AUTOSAR XML (schema 00049)
package /MICROSAR/NvM_swc/DataTypes
  impl type NvM_BlockIdType: range raw 1..32767, implementation-data-type=uint16
  impl type NvM_RequestResultType: compu {0=NVM_REQ_OK, 1=NVM_REQ_NOT_OK, 2=NVM_REQ_PENDING, 3=NVM_REQ_INTEGRITY_FAILED, 4=NVM_REQ_BLOCK_SKIPPED, 5=NVM_REQ_NV_INVALIDATED, 6=NVM_REQ_CANCELED, 7=NVM_REQ_REDUNDANCY_FAILED, 8=NVM_REQ_RESTORED_FROM_ROM}, range raw 0..8, implementation-data-type=uint8
package /MICROSAR/NvM_swc/Interfaces
  4 x client server interface, all with is-service=true, service-kind=NON-VOLATILE-RAM-MANAGER:
    NvMAdministration
      operation SetBlockProtection: possible-error=NvMAdministration/E_NOT_OK
        arg ProtectionEnabled: type=boolean, direction=IN
      error E_NOT_OK: error-code=1
    NvMService_AC3_SRBS_Defs
      7 x operation, all with possible-error=NvMService_AC3_SRBS_Defs/E_NOT_OK:
        GetErrorStatus
          arg ErrorStatus: type=NvM_RequestResultType, direction=OUT
        SetRamBlockStatus
          arg RamBlockStatus: type=boolean, direction=IN
        ReadBlock
          arg DstPtr: type=dtRef_VOID, direction=IN
        WriteBlock
          arg SrcPtr: type=dtRef_const_VOID, direction=IN
        RestoreBlockDefaults
          arg DstPtr: type=dtRef_VOID, direction=IN
        InvalidateNvBlock
        EraseBlock
      error E_NOT_OK: error-code=1
    NvMService_AC3_SRBS
      6 x operation, all with possible-error=NvMService_AC3_SRBS/E_NOT_OK:
        GetErrorStatus
          arg ErrorStatus: type=NvM_RequestResultType, direction=OUT
        SetRamBlockStatus
          arg RamBlockStatus: type=boolean, direction=IN
        ReadBlock
          arg DstPtr: type=dtRef_VOID, direction=IN
        WriteBlock
          arg SrcPtr: type=dtRef_const_VOID, direction=IN
        InvalidateNvBlock
        EraseBlock
      error E_NOT_OK: error-code=1
    NvMService_AC3_SRBS_DS_Defs
      9 x operation, all with possible-error=NvMService_AC3_SRBS_DS_Defs/E_NOT_OK:
        GetErrorStatus
          arg ErrorStatus: type=NvM_RequestResultType, direction=OUT
        SetRamBlockStatus
          arg RamBlockStatus: type=boolean, direction=IN
        ReadBlock
          arg DstPtr: type=dtRef_VOID, direction=IN
        WriteBlock
          arg SrcPtr: type=dtRef_const_VOID, direction=IN
        RestoreBlockDefaults
          arg DstPtr: type=dtRef_VOID, direction=IN
        SetDataIndex
          arg DataIndex: type=uint8, direction=IN
        GetDataIndex
          arg DataIndex: type=uint8, direction=OUT
        InvalidateNvBlock
        EraseBlock
      error E_NOT_OK: error-code=1
package /MICROSAR/NvM_swc/ComponentTypes
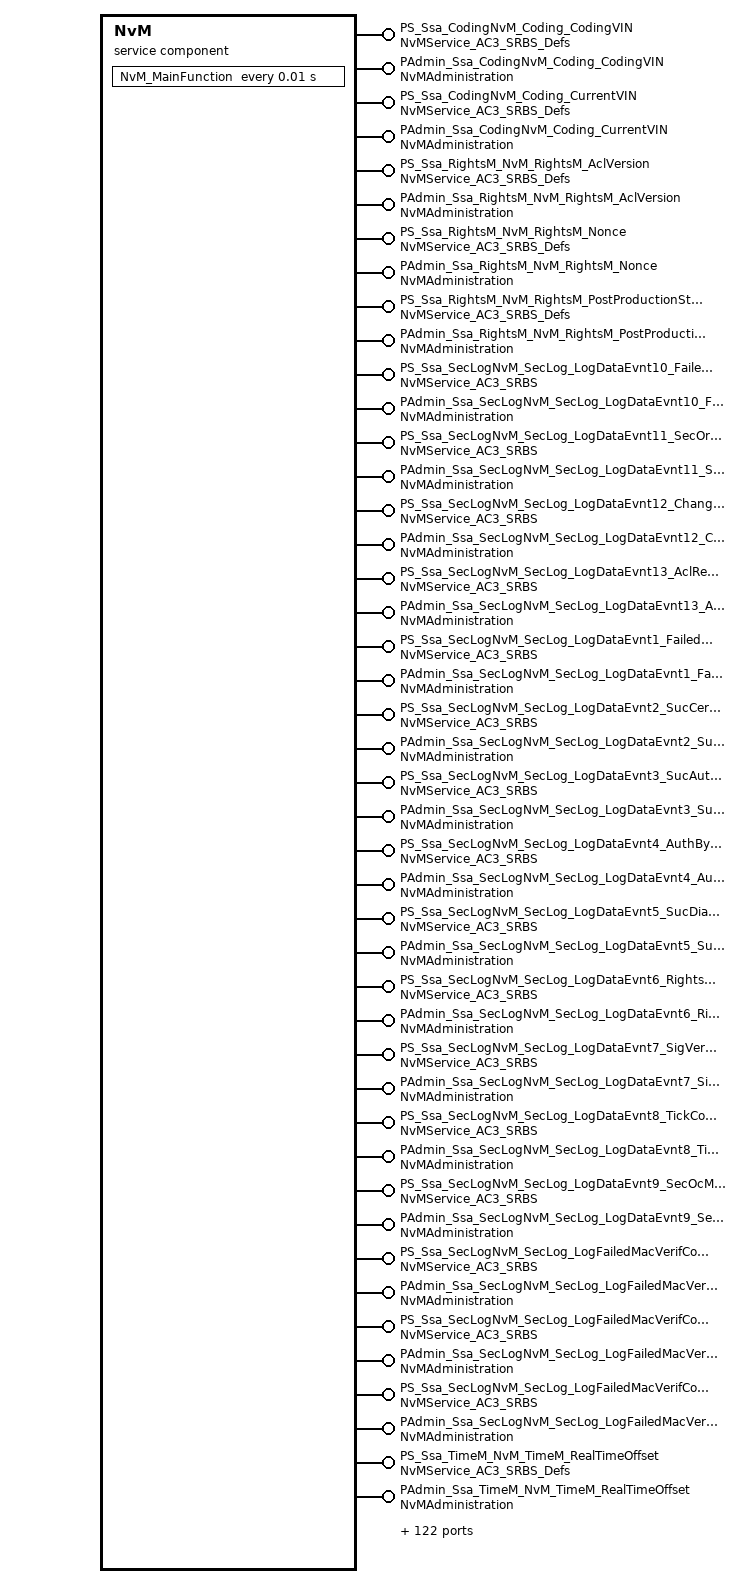
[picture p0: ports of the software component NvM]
  service sw component type NvM: category=SERVICE_COMPONENT
    166 x provide port:
      PS_Ssa_CodingNvM_Coding_CodingVIN: provided-interface=NvMService_AC3_SRBS_Defs
      PAdmin_Ssa_CodingNvM_Coding_CodingVIN: provided-interface=NvMAdministration
      PS_Ssa_CodingNvM_Coding_CurrentVIN: provided-interface=NvMService_AC3_SRBS_Defs
      PAdmin_Ssa_CodingNvM_Coding_CurrentVIN: provided-interface=NvMAdministration
      PS_Ssa_RightsM_NvM_RightsM_AclVersion: provided-interface=NvMService_AC3_SRBS_Defs
      PAdmin_Ssa_RightsM_NvM_RightsM_AclVersion: provided-interface=NvMAdministration
      PS_Ssa_RightsM_NvM_RightsM_Nonce: provided-interface=NvMService_AC3_SRBS_Defs
      PAdmin_Ssa_RightsM_NvM_RightsM_Nonce: provided-interface=NvMAdministration
      PS_Ssa_RightsM_NvM_RightsM_PostProductionStatus: provided-interface=NvMService_AC3_SRBS_Defs
      PAdmin_Ssa_RightsM_NvM_RightsM_PostProductionStatus: provided-interface=NvMAdministration
      PS_Ssa_SecLogNvM_SecLog_LogDataEvnt10_FailedPduMacVerif: provided-interface=NvMService_AC3_SRBS
      PAdmin_Ssa_SecLogNvM_SecLog_LogDataEvnt10_FailedPduMacVerif: provided-interface=NvMAdministration
      PS_Ssa_SecLogNvM_SecLog_LogDataEvnt11_SecOrAuthBoot: provided-interface=NvMService_AC3_SRBS
      PAdmin_Ssa_SecLogNvM_SecLog_LogDataEvnt11_SecOrAuthBoot: provided-interface=NvMAdministration
      PS_Ssa_SecLogNvM_SecLog_LogDataEvnt12_ChangeOfVin: provided-interface=NvMService_AC3_SRBS
      PAdmin_Ssa_SecLogNvM_SecLog_LogDataEvnt12_ChangeOfVin: provided-interface=NvMAdministration
      PS_Ssa_SecLogNvM_SecLog_LogDataEvnt13_AclReplacement: provided-interface=NvMService_AC3_SRBS
      PAdmin_Ssa_SecLogNvM_SecLog_LogDataEvnt13_AclReplacement: provided-interface=NvMAdministration
      PS_Ssa_SecLogNvM_SecLog_LogDataEvnt1_FailedCertVerif: provided-interface=NvMService_AC3_SRBS
      PAdmin_Ssa_SecLogNvM_SecLog_LogDataEvnt1_FailedCertVerif: provided-interface=NvMAdministration
      PS_Ssa_SecLogNvM_SecLog_LogDataEvnt2_SucCertVerif: provided-interface=NvMService_AC3_SRBS
      PAdmin_Ssa_SecLogNvM_SecLog_LogDataEvnt2_SucCertVerif: provided-interface=NvMAdministration
      PS_Ssa_SecLogNvM_SecLog_LogDataEvnt3_SucAuthAndEnhanceRights: provided-interface=NvMService_AC3_SRBS
      PAdmin_Ssa_SecLogNvM_SecLog_LogDataEvnt3_SucAuthAndEnhanceRights: provided-interface=NvMAdministration
      PS_Ssa_SecLogNvM_SecLog_LogDataEvnt4_AuthBySecAccess: provided-interface=NvMService_AC3_SRBS
      PAdmin_Ssa_SecLogNvM_SecLog_LogDataEvnt4_AuthBySecAccess: provided-interface=NvMAdministration
      PS_Ssa_SecLogNvM_SecLog_LogDataEvnt5_SucDiagServiceExec: provided-interface=NvMService_AC3_SRBS
      PAdmin_Ssa_SecLogNvM_SecLog_LogDataEvnt5_SucDiagServiceExec: provided-interface=NvMAdministration
      PS_Ssa_SecLogNvM_SecLog_LogDataEvnt6_RightsMgmt: provided-interface=NvMService_AC3_SRBS
      PAdmin_Ssa_SecLogNvM_SecLog_LogDataEvnt6_RightsMgmt: provided-interface=NvMAdministration
      PS_Ssa_SecLogNvM_SecLog_LogDataEvnt7_SigVerif: provided-interface=NvMService_AC3_SRBS
      PAdmin_Ssa_SecLogNvM_SecLog_LogDataEvnt7_SigVerif: provided-interface=NvMAdministration
      PS_Ssa_SecLogNvM_SecLog_LogDataEvnt8_TickCountDateAndTime: provided-interface=NvMService_AC3_SRBS
      PAdmin_Ssa_SecLogNvM_SecLog_LogDataEvnt8_TickCountDateAndTime: provided-interface=NvMAdministration
      PS_Ssa_SecLogNvM_SecLog_LogDataEvnt9_SecOcMisconfig: provided-interface=NvMService_AC3_SRBS
      PAdmin_Ssa_SecLogNvM_SecLog_LogDataEvnt9_SecOcMisconfig: provided-interface=NvMAdministration
      PS_Ssa_SecLogNvM_SecLog_LogFailedMacVerifCount_ExceededTh1: provided-interface=NvMService_AC3_SRBS
      PAdmin_Ssa_SecLogNvM_SecLog_LogFailedMacVerifCount_ExceededTh1: provided-interface=NvMAdministration
      PS_Ssa_SecLogNvM_SecLog_LogFailedMacVerifCount_ExceededTh2: provided-interface=NvMService_AC3_SRBS
      PAdmin_Ssa_SecLogNvM_SecLog_LogFailedMacVerifCount_ExceededTh2: provided-interface=NvMAdministration
      PS_Ssa_SecLogNvM_SecLog_LogFailedMacVerifCount_ExceededTh3: provided-interface=NvMService_AC3_SRBS
      PAdmin_Ssa_SecLogNvM_SecLog_LogFailedMacVerifCount_ExceededTh3: provided-interface=NvMAdministration
      PS_Ssa_TimeM_NvM_TimeM_RealTimeOffset: provided-interface=NvMService_AC3_SRBS_Defs
      PAdmin_Ssa_TimeM_NvM_TimeM_RealTimeOffset: provided-interface=NvMAdministration
      PS_Ssa_TimeM_NvM_TimeM_TickCount: provided-interface=NvMService_AC3_SRBS_Defs
      PAdmin_Ssa_TimeM_NvM_TimeM_TickCount: provided-interface=NvMAdministration
      PS_Ct_MBBL_SsaAppl_CodingNvmCoding_CurrentVehicleEquipment: provided-interface=NvMService_AC3_SRBS
      PAdmin_Ct_MBBL_SsaAppl_CodingNvmCoding_CurrentVehicleEquipment: provided-interface=NvMAdministration
      PS_Ct_MBBL_SsaAppl_CodingNvmCoding_TensioningCycleBSR: provided-interface=NvMService_AC3_SRBS
      PAdmin_Ct_MBBL_SsaAppl_CodingNvmCoding_TensioningCycleBSR: provided-interface=NvMAdministration
      PS_Ct_MBBL_SsaAppl_CodingNvmCoding_PreSafeCyclesLevel: provided-interface=NvMService_AC3_SRBS
      PAdmin_Ct_MBBL_SsaAppl_CodingNvmCoding_PreSafeCyclesLevel: provided-interface=NvMAdministration
      PS_Ct_MBBL_SsaAppl_CodingNvmCoding_ReleaseCyclesBsrAndPreSafe: provided-interface=NvMService_AC3_SRBS
      PAdmin_Ct_MBBL_SsaAppl_CodingNvmCoding_ReleaseCyclesBsrAndPreSafe: provided-interface=NvMAdministration
      PS_Ct_MBBL_SsaAppl_CodingNvmCoding_ZZZVehicleEquipmentDevelopment: provided-interface=NvMService_AC3_SRBS
      PAdmin_Ct_MBBL_SsaAppl_CodingNvmCoding_ZZZVehicleEquipmentDevelopment: provided-interface=NvMAdministration
      PS_Ct_MBBL_SsaAppl_CodingNvmCoding_CalibrationID: provided-interface=NvMService_AC3_SRBS
      PAdmin_Ct_MBBL_SsaAppl_CodingNvmCoding_CalibrationID: provided-interface=NvMAdministration
      PS_NvMBlockDescriptor_FblMetaData: provided-interface=NvMService_AC3_SRBS_DS_Defs
      PAdmin_NvMBlockDescriptor_FblMetaData: provided-interface=NvMAdministration
      PS_NVP_BLOCK_ID_ECU_LOCATION: provided-interface=NvMService_AC3_SRBS_Defs
      PAdmin_NVP_BLOCK_ID_ECU_LOCATION: provided-interface=NvMAdministration
      PS_NVP_BLOCK_ID_BELT_ASSEMBLY_MANUF_DATE_AND_SN: provided-interface=NvMService_AC3_SRBS_Defs
      PAdmin_NVP_BLOCK_ID_BELT_ASSEMBLY_MANUF_DATE_AND_SN: provided-interface=NvMAdministration
      PS_NVP_BLOCK_ID_HB_CALIBRATION: provided-interface=NvMService_AC3_SRBS_Defs
      PAdmin_NVP_BLOCK_ID_HB_CALIBRATION: provided-interface=NvMAdministration
      PS_NVP_BLOCK_ID_AEE_TRACEABILITY: provided-interface=NvMService_AC3_SRBS_Defs
      PAdmin_NVP_BLOCK_ID_AEE_TRACEABILITY: provided-interface=NvMAdministration
      PS_NVP_BLOCK_ID_EXECUTION_COUNTERS: provided-interface=NvMService_AC3_SRBS_Defs
      PAdmin_NVP_BLOCK_ID_EXECUTION_COUNTERS: provided-interface=NvMAdministration
      PS_NVP_BLOCK_ID_TESTS_PARAM: provided-interface=NvMService_AC3_SRBS_Defs
      PAdmin_NVP_BLOCK_ID_TESTS_PARAM: provided-interface=NvMAdministration
      PS_NVP_BLOCK_ID_CYCLE: provided-interface=NvMService_AC3_SRBS_Defs
      PAdmin_NVP_BLOCK_ID_CYCLE: provided-interface=NvMAdministration
      PS_NVP_BLOCK_ID_STEP: provided-interface=NvMService_AC3_SRBS_Defs
      PAdmin_NVP_BLOCK_ID_STEP: provided-interface=NvMAdministration
      PS_CALIB_BLOCK_ID_EOL_PARAM: provided-interface=NvMService_AC3_SRBS_Defs
      PAdmin_CALIB_BLOCK_ID_EOL_PARAM: provided-interface=NvMAdministration
      PS_CALIB_BLOCK_ID_BFS_PRIO_PARAM: provided-interface=NvMService_AC3_SRBS_Defs
      PAdmin_CALIB_BLOCK_ID_BFS_PRIO_PARAM: provided-interface=NvMAdministration
      PS_CALIB_BLOCK_ID_PID_PARAM: provided-interface=NvMService_AC3_SRBS_Defs
      PAdmin_CALIB_BLOCK_ID_PID_PARAM: provided-interface=NvMAdministration
      PS_CALIB_BLOCK_ID_WEIGHT_REL_TABLE: provided-interface=NvMService_AC3_SRBS_Defs
      PAdmin_CALIB_BLOCK_ID_WEIGHT_REL_TABLE: provided-interface=NvMAdministration
      PS_CALIB_BLOCK_ID_WEIGHT_TENS0_TABLE: provided-interface=NvMService_AC3_SRBS_Defs
      PAdmin_CALIB_BLOCK_ID_WEIGHT_TENS0_TABLE: provided-interface=NvMAdministration
      PS_CALIB_BLOCK_ID_WEIGHT_TENS1_TABLE: provided-interface=NvMService_AC3_SRBS_Defs
      PAdmin_CALIB_BLOCK_ID_WEIGHT_TENS1_TABLE: provided-interface=NvMAdministration
      PS_CALIB_BLOCK_ID_WEIGHT_TENS2_TABLE: provided-interface=NvMService_AC3_SRBS_Defs
      PAdmin_CALIB_BLOCK_ID_WEIGHT_TENS2_TABLE: provided-interface=NvMAdministration
      PS_CALIB_BLOCK_ID_WEIGHT_TENS3_TABLE: provided-interface=NvMService_AC3_SRBS_Defs
      PAdmin_CALIB_BLOCK_ID_WEIGHT_TENS3_TABLE: provided-interface=NvMAdministration
      PS_CALIB_BLOCK_ID_INT_CURRENT_CORR: provided-interface=NvMService_AC3_SRBS_Defs
      PAdmin_CALIB_BLOCK_ID_INT_CURRENT_CORR: provided-interface=NvMAdministration
      PS_CALIB_BLOCK_ID_INT_CURRENT_TABLE: provided-interface=NvMService_AC3_SRBS_Defs
      PAdmin_CALIB_BLOCK_ID_INT_CURRENT_TABLE: provided-interface=NvMAdministration
      PS_CALIB_BLOCK_ID_ECPL_ALPHA_TABLE: provided-interface=NvMService_AC3_SRBS_Defs
      PAdmin_CALIB_BLOCK_ID_ECPL_ALPHA_TABLE: provided-interface=NvMAdministration
      PS_CALIB_BLOCK_ID_POWER_DEGRADATION: provided-interface=NvMService_AC3_SRBS_Defs
      PAdmin_CALIB_BLOCK_ID_POWER_DEGRADATION: provided-interface=NvMAdministration
      PS_CALIB_BLOCK_ID_ECPL_BETA_TABLE: provided-interface=NvMService_AC3_SRBS_Defs
      PAdmin_CALIB_BLOCK_ID_ECPL_BETA_TABLE: provided-interface=NvMAdministration
      PS_CALIB_BLOCK_ID_ECPL_OTHER_PARAM: provided-interface=NvMService_AC3_SRBS_Defs
      PAdmin_CALIB_BLOCK_ID_ECPL_OTHER_PARAM: provided-interface=NvMAdministration
      PS_CALIB_BLOCK_ID_BPA_MOTOR_CURRENT: provided-interface=NvMService_AC3_SRBS_Defs
      PAdmin_CALIB_BLOCK_ID_BPA_MOTOR_CURRENT: provided-interface=NvMAdministration
      PS_CALIB_BLOCK_ID_VOLT_THRS: provided-interface=NvMService_AC3_SRBS_Defs
      PAdmin_CALIB_BLOCK_ID_VOLT_THRS: provided-interface=NvMAdministration
      PS_CALIB_BLOCK_ID_BATTERY_LOSS_DETECTION_THRS: provided-interface=NvMService_AC3_SRBS_Defs
      PAdmin_CALIB_BLOCK_ID_BATTERY_LOSS_DETECTION_THRS: provided-interface=NvMAdministration
      PS_CALIB_BLOCK_ID_BOOST: provided-interface=NvMService_AC3_SRBS_Defs
      PAdmin_CALIB_BLOCK_ID_BOOST: provided-interface=NvMAdministration
      PS_CALIB_BLOCK_ID_ECU_PROPERTIES: provided-interface=NvMService_AC3_SRBS_Defs
      PAdmin_CALIB_BLOCK_ID_ECU_PROPERTIES: provided-interface=NvMAdministration
      PS_CALIB_BLOCK_ID_SW_SELF_PROTECTION_THRS: provided-interface=NvMService_AC3_SRBS_Defs
      PAdmin_CALIB_BLOCK_ID_SW_SELF_PROTECTION_THRS: provided-interface=NvMAdministration
      PS_CALIB_BLOCK_ID_MOTOR_RESIST_PARAM: provided-interface=NvMService_AC3_SRBS_Defs
      PAdmin_CALIB_BLOCK_ID_MOTOR_RESIST_PARAM: provided-interface=NvMAdministration
      PS_CALIB_BLOCK_ID_BOOST_ACTIVATION: provided-interface=NvMService_AC3_SRBS_Defs
      PAdmin_CALIB_BLOCK_ID_BOOST_ACTIVATION: provided-interface=NvMAdministration
      PS_NVP_BLOCK_ID_MEASUREMENT_FRAME_12_CONFIG: provided-interface=NvMService_AC3_SRBS_Defs
      PAdmin_NVP_BLOCK_ID_MEASUREMENT_FRAME_12_CONFIG: provided-interface=NvMAdministration
      PS_NVP_BLOCK_ID_MEASUREMENT_FRAME_CONFIG: provided-interface=NvMService_AC3_SRBS_Defs
      PAdmin_NVP_BLOCK_ID_MEASUREMENT_FRAME_CONFIG: provided-interface=NvMAdministration
      PS_NVP_BLOCK_ID_WARM_RESET: provided-interface=NvMService_AC3_SRBS_Defs
      PAdmin_NVP_BLOCK_ID_WARM_RESET: provided-interface=NvMAdministration
      PS_NVP_BLOCK_ID_HWA_REPETITION: provided-interface=NvMService_AC3_SRBS_Defs
      PAdmin_NVP_BLOCK_ID_HWA_REPETITION: provided-interface=NvMAdministration
      PS_NVP_BLOCK_TEMP_SENSOR_TABLE: provided-interface=NvMService_AC3_SRBS_Defs
      PAdmin_NVP_BLOCK_TEMP_SENSOR_TABLE: provided-interface=NvMAdministration
      PS_NVP_BLOCK_ID_VELOCITY_PID_PARAM: provided-interface=NvMService_AC3_SRBS_Defs
      PAdmin_NVP_BLOCK_ID_VELOCITY_PID_PARAM: provided-interface=NvMAdministration
      PS_NVP_BLOCK_ID_AEC_STATUS: provided-interface=NvMService_AC3_SRBS_Defs
      PAdmin_NVP_BLOCK_ID_AEC_STATUS: provided-interface=NvMAdministration
      PS_NVP_BLOCK_ID_ATM_ENABLE_PARAM: provided-interface=NvMService_AC3_SRBS_Defs
      PAdmin_NVP_BLOCK_ID_ATM_ENABLE_PARAM: provided-interface=NvMAdministration
      PS_Ssa_KeyM_NvM_KeyM_TrustModelChainOfTrustState: provided-interface=NvMService_AC3_SRBS_Defs
      PAdmin_Ssa_KeyM_NvM_KeyM_TrustModelChainOfTrustState: provided-interface=NvMAdministration
      PS_NVP_BLOCK_ID_PRE_SAFE_RECORDER_1: provided-interface=NvMService_AC3_SRBS_Defs
      PAdmin_NVP_BLOCK_ID_PRE_SAFE_RECORDER_1: provided-interface=NvMAdministration
      PS_NVP_BLOCK_ID_PRE_SAFE_RECORDER_2: provided-interface=NvMService_AC3_SRBS_Defs
      PAdmin_NVP_BLOCK_ID_PRE_SAFE_RECORDER_2: provided-interface=NvMAdministration
      PS_NVP_BLOCK_ID_PRE_SAFE_RECORDER_ID: provided-interface=NvMService_AC3_SRBS_Defs
      PAdmin_NVP_BLOCK_ID_PRE_SAFE_RECORDER_ID: provided-interface=NvMAdministration
      PS_NVP_BLOCK_ID_SYSTEM_CONTEXT_0: provided-interface=NvMService_AC3_SRBS
      PAdmin_NVP_BLOCK_ID_SYSTEM_CONTEXT_0: provided-interface=NvMAdministration
      PS_NVP_BLOCK_ID_SYSTEM_CONTEXT_1: provided-interface=NvMService_AC3_SRBS
      PAdmin_NVP_BLOCK_ID_SYSTEM_CONTEXT_1: provided-interface=NvMAdministration
      PS_NVP_BLOCK_ID_SYSTEM_CONTEXT_2: provided-interface=NvMService_AC3_SRBS
      PAdmin_NVP_BLOCK_ID_SYSTEM_CONTEXT_2: provided-interface=NvMAdministration
      PS_NVP_BLOCK_ID_CYCLE_DELAYS_MB: provided-interface=NvMService_AC3_SRBS_Defs
      PAdmin_NVP_BLOCK_ID_CYCLE_DELAYS_MB: provided-interface=NvMAdministration
      PS_NVP_BLOCK_ID_HAPTIC_CONFIG_MB: provided-interface=NvMService_AC3_SRBS_Defs
      PAdmin_NVP_BLOCK_ID_HAPTIC_CONFIG_MB: provided-interface=NvMAdministration
      PS_NVP_BLOCK_ID_EOL_MAPPING_MB: provided-interface=NvMService_AC3_SRBS_Defs
      PAdmin_NVP_BLOCK_ID_EOL_MAPPING_MB: provided-interface=NvMAdministration
      PS_NVP_BLOCK_ID_HW_VERSION: provided-interface=NvMService_AC3_SRBS_Defs
      PAdmin_NVP_BLOCK_ID_HW_VERSION: provided-interface=NvMAdministration
      PS_NVP_BLOCK_ID_CAN_INPUT_SIGNALS: provided-interface=NvMService_AC3_SRBS_Defs
      PAdmin_NVP_BLOCK_ID_CAN_INPUT_SIGNALS: provided-interface=NvMAdministration
      PS_NVP_BLOCK_ID_PCBA_PPN: provided-interface=NvMService_AC3_SRBS_Defs
      PAdmin_NVP_BLOCK_ID_PCBA_PPN: provided-interface=NvMAdministration
      PS_NVP_BLOCK_ID_CSR_SUPPLIER_SIGNATURE: provided-interface=NvMService_AC3_SRBS_Defs
      PAdmin_NVP_BLOCK_ID_CSR_SUPPLIER_SIGNATURE: provided-interface=NvMAdministration
      PS_NVP_BLOCK_ID_HW_PARTNUMBER: provided-interface=NvMService_AC3_SRBS_Defs
      PAdmin_NVP_BLOCK_ID_HW_PARTNUMBER: provided-interface=NvMAdministration
    behavior NvMInternalBehavior: handle-termination-and-restart=NO-SUPPORT
      timing event Timer_NvM_MainFunction: start-on-event=NvM_MainFunction, period=0.01
      641 x operation invoked event:
        OpEventGetErrorStatus_GetErrorStatus_PS_Ssa_CodingNvM_Coding_CodingVIN: start-on-event=GetErrorStatus, operation=PS_Ssa_CodingNvM_Coding_CodingVIN.GetErrorStatus
        OpEventGetErrorStatus_GetErrorStatus_PS_Ssa_CodingNvM_Coding_CurrentVIN: start-on-event=GetErrorStatus, operation=PS_Ssa_CodingNvM_Coding_CurrentVIN.GetErrorStatus
        OpEventGetErrorStatus_GetErrorStatus_PS_Ssa_RightsM_NvM_RightsM_AclVersion: start-on-event=GetErrorStatus, operation=PS_Ssa_RightsM_NvM_RightsM_AclVersion.GetErrorStatus
        OpEventGetErrorStatus_GetErrorStatus_PS_Ssa_RightsM_NvM_RightsM_Nonce: start-on-event=GetErrorStatus, operation=PS_Ssa_RightsM_NvM_RightsM_Nonce.GetErrorStatus
        OpEventGetErrorStatus_GetErrorStatus_PS_Ssa_RightsM_NvM_RightsM_PostProductionStatus: start-on-event=GetErrorStatus, operation=PS_Ssa_RightsM_NvM_RightsM_PostProductionStatus.GetErrorStatus
        OpEventGetErrorStatus_GetErrorStatus_PS_Ssa_SecLogNvM_SecLog_LogDataEvnt10_FailedPduMacVerif: start-on-event=GetErrorStatus, operation=PS_Ssa_SecLogNvM_SecLog_LogDataEvnt10_FailedPduMacVerif.GetErrorStatus
        OpEventGetErrorStatus_GetErrorStatus_PS_Ssa_SecLogNvM_SecLog_LogDataEvnt11_SecOrAuthBoot: start-on-event=GetErrorStatus, operation=PS_Ssa_SecLogNvM_SecLog_LogDataEvnt11_SecOrAuthBoot.GetErrorStatus
        OpEventGetErrorStatus_GetErrorStatus_PS_Ssa_SecLogNvM_SecLog_LogDataEvnt12_ChangeOfVin: start-on-event=GetErrorStatus, operation=PS_Ssa_SecLogNvM_SecLog_LogDataEvnt12_ChangeOfVin.GetErrorStatus
        OpEventGetErrorStatus_GetErrorStatus_PS_Ssa_SecLogNvM_SecLog_LogDataEvnt13_AclReplacement: start-on-event=GetErrorStatus, operation=PS_Ssa_SecLogNvM_SecLog_LogDataEvnt13_AclReplacement.GetErrorStatus
        OpEventGetErrorStatus_GetErrorStatus_PS_Ssa_SecLogNvM_SecLog_LogDataEvnt1_FailedCertVerif: start-on-event=GetErrorStatus, operation=PS_Ssa_SecLogNvM_SecLog_LogDataEvnt1_FailedCertVerif.GetErrorStatus
        OpEventGetErrorStatus_GetErrorStatus_PS_Ssa_SecLogNvM_SecLog_LogDataEvnt2_SucCertVerif: start-on-event=GetErrorStatus, operation=PS_Ssa_SecLogNvM_SecLog_LogDataEvnt2_SucCertVerif.GetErrorStatus
        OpEventGetErrorStatus_GetErrorStatus_PS_Ssa_SecLogNvM_SecLog_LogDataEvnt3_SucAuthAndEnhanceRights: start-on-event=GetErrorStatus, operation=PS_Ssa_SecLogNvM_SecLog_LogDataEvnt3_SucAuthAndEnhanceRights.GetErrorStatus
        OpEventGetErrorStatus_GetErrorStatus_PS_Ssa_SecLogNvM_SecLog_LogDataEvnt4_AuthBySecAccess: start-on-event=GetErrorStatus, operation=PS_Ssa_SecLogNvM_SecLog_LogDataEvnt4_AuthBySecAccess.GetErrorStatus
        OpEventGetErrorStatus_GetErrorStatus_PS_Ssa_SecLogNvM_SecLog_LogDataEvnt5_SucDiagServiceExec: start-on-event=GetErrorStatus, operation=PS_Ssa_SecLogNvM_SecLog_LogDataEvnt5_SucDiagServiceExec.GetErrorStatus
        OpEventGetErrorStatus_GetErrorStatus_PS_Ssa_SecLogNvM_SecLog_LogDataEvnt6_RightsMgmt: start-on-event=GetErrorStatus, operation=PS_Ssa_SecLogNvM_SecLog_LogDataEvnt6_RightsMgmt.GetErrorStatus
        OpEventGetErrorStatus_GetErrorStatus_PS_Ssa_SecLogNvM_SecLog_LogDataEvnt7_SigVerif: start-on-event=GetErrorStatus, operation=PS_Ssa_SecLogNvM_SecLog_LogDataEvnt7_SigVerif.GetErrorStatus
        OpEventGetErrorStatus_GetErrorStatus_PS_Ssa_SecLogNvM_SecLog_LogDataEvnt8_TickCountDateAndTime: start-on-event=GetErrorStatus, operation=PS_Ssa_SecLogNvM_SecLog_LogDataEvnt8_TickCountDateAndTime.GetErrorStatus
        OpEventGetErrorStatus_GetErrorStatus_PS_Ssa_SecLogNvM_SecLog_LogDataEvnt9_SecOcMisconfig: start-on-event=GetErrorStatus, operation=PS_Ssa_SecLogNvM_SecLog_LogDataEvnt9_SecOcMisconfig.GetErrorStatus
        OpEventGetErrorStatus_GetErrorStatus_PS_Ssa_SecLogNvM_SecLog_LogFailedMacVerifCount_ExceededTh{1..3}: start-on-event=GetErrorStatus, operation=PS_Ssa_SecLogNvM_SecLog_LogFailedMacVerifCount_ExceededTh{1..3}.GetErrorStatus
        OpEventGetErrorStatus_GetErrorStatus_PS_Ssa_TimeM_NvM_TimeM_RealTimeOffset: start-on-event=GetErrorStatus, operation=PS_Ssa_TimeM_NvM_TimeM_RealTimeOffset.GetErrorStatus
        OpEventGetErrorStatus_GetErrorStatus_PS_Ssa_TimeM_NvM_TimeM_TickCount: start-on-event=GetErrorStatus, operation=PS_Ssa_TimeM_NvM_TimeM_TickCount.GetErrorStatus
        OpEventGetErrorStatus_GetErrorStatus_PS_Ct_MBBL_SsaAppl_CodingNvmCoding_CurrentVehicleEquipment: start-on-event=GetErrorStatus, operation=PS_Ct_MBBL_SsaAppl_CodingNvmCoding_CurrentVehicleEquipment.GetErrorStatus
        OpEventGetErrorStatus_GetErrorStatus_PS_Ct_MBBL_SsaAppl_CodingNvmCoding_TensioningCycleBSR: start-on-event=GetErrorStatus, operation=PS_Ct_MBBL_SsaAppl_CodingNvmCoding_TensioningCycleBSR.GetErrorStatus
        OpEventGetErrorStatus_GetErrorStatus_PS_Ct_MBBL_SsaAppl_CodingNvmCoding_PreSafeCyclesLevel: start-on-event=GetErrorStatus, operation=PS_Ct_MBBL_SsaAppl_CodingNvmCoding_PreSafeCyclesLevel.GetErrorStatus
        OpEventGetErrorStatus_GetErrorStatus_PS_Ct_MBBL_SsaAppl_CodingNvmCoding_ReleaseCyclesBsrAndPreSafe: start-on-event=GetErrorStatus, operation=PS_Ct_MBBL_SsaAppl_CodingNvmCoding_ReleaseCyclesBsrAndPreSafe.GetErrorStatus
        OpEventGetErrorStatus_GetErrorStatus_PS_Ct_MBBL_SsaAppl_CodingNvmCoding_ZZZVehicleEquipmentDevelopment: start-on-event=GetErrorStatus, operation=PS_Ct_MBBL_SsaAppl_CodingNvmCoding_ZZZVehicleEquipmentDevelopment.GetErrorStatus
        OpEventGetErrorStatus_GetErrorStatus_PS_Ct_MBBL_SsaAppl_CodingNvmCoding_CalibrationID: start-on-event=GetErrorStatus, operation=PS_Ct_MBBL_SsaAppl_CodingNvmCoding_CalibrationID.GetErrorStatus
        OpEventGetErrorStatus_GetErrorStatus_PS_NvMBlockDescriptor_FblMetaData: start-on-event=GetErrorStatus, operation=PS_NvMBlockDescriptor_FblMetaData.GetErrorStatus
        OpEventGetErrorStatus_GetErrorStatus_PS_NVP_BLOCK_ID_ECU_LOCATION: start-on-event=GetErrorStatus, operation=PS_NVP_BLOCK_ID_ECU_LOCATION.GetErrorStatus
        OpEventGetErrorStatus_GetErrorStatus_PS_NVP_BLOCK_ID_BELT_ASSEMBLY_MANUF_DATE_AND_SN: start-on-event=GetErrorStatus, operation=PS_NVP_BLOCK_ID_BELT_ASSEMBLY_MANUF_DATE_AND_SN.GetErrorStatus
        OpEventGetErrorStatus_GetErrorStatus_PS_NVP_BLOCK_ID_HB_CALIBRATION: start-on-event=GetErrorStatus, operation=PS_NVP_BLOCK_ID_HB_CALIBRATION.GetErrorStatus
        OpEventGetErrorStatus_GetErrorStatus_PS_NVP_BLOCK_ID_AEE_TRACEABILITY: start-on-event=GetErrorStatus, operation=PS_NVP_BLOCK_ID_AEE_TRACEABILITY.GetErrorStatus
        OpEventGetErrorStatus_GetErrorStatus_PS_NVP_BLOCK_ID_EXECUTION_COUNTERS: start-on-event=GetErrorStatus, operation=PS_NVP_BLOCK_ID_EXECUTION_COUNTERS.GetErrorStatus
        OpEventGetErrorStatus_GetErrorStatus_PS_NVP_BLOCK_ID_TESTS_PARAM: start-on-event=GetErrorStatus, operation=PS_NVP_BLOCK_ID_TESTS_PARAM.GetErrorStatus
        OpEventGetErrorStatus_GetErrorStatus_PS_NVP_BLOCK_ID_CYCLE: start-on-event=GetErrorStatus, operation=PS_NVP_BLOCK_ID_CYCLE.GetErrorStatus
        OpEventGetErrorStatus_GetErrorStatus_PS_NVP_BLOCK_ID_STEP: start-on-event=GetErrorStatus, operation=PS_NVP_BLOCK_ID_STEP.GetErrorStatus
        OpEventGetErrorStatus_GetErrorStatus_PS_CALIB_BLOCK_ID_EOL_PARAM: start-on-event=GetErrorStatus, operation=PS_CALIB_BLOCK_ID_EOL_PARAM.GetErrorStatus
        OpEventGetErrorStatus_GetErrorStatus_PS_CALIB_BLOCK_ID_BFS_PRIO_PARAM: start-on-event=GetErrorStatus, operation=PS_CALIB_BLOCK_ID_BFS_PRIO_PARAM.GetErrorStatus
        OpEventGetErrorStatus_GetErrorStatus_PS_CALIB_BLOCK_ID_PID_PARAM: start-on-event=GetErrorStatus, operation=PS_CALIB_BLOCK_ID_PID_PARAM.GetErrorStatus
        OpEventGetErrorStatus_GetErrorStatus_PS_CALIB_BLOCK_ID_WEIGHT_REL_TABLE: start-on-event=GetErrorStatus, operation=PS_CALIB_BLOCK_ID_WEIGHT_REL_TABLE.GetErrorStatus
        OpEventGetErrorStatus_GetErrorStatus_PS_CALIB_BLOCK_ID_WEIGHT_TENS{0..3}_TABLE: start-on-event=GetErrorStatus, operation=PS_CALIB_BLOCK_ID_WEIGHT_TENS{0..3}_TABLE.GetErrorStatus
        OpEventGetErrorStatus_GetErrorStatus_PS_CALIB_BLOCK_ID_INT_CURRENT_CORR: start-on-event=GetErrorStatus, operation=PS_CALIB_BLOCK_ID_INT_CURRENT_CORR.GetErrorStatus
        OpEventGetErrorStatus_GetErrorStatus_PS_CALIB_BLOCK_ID_INT_CURRENT_TABLE: start-on-event=GetErrorStatus, operation=PS_CALIB_BLOCK_ID_INT_CURRENT_TABLE.GetErrorStatus
        OpEventGetErrorStatus_GetErrorStatus_PS_CALIB_BLOCK_ID_ECPL_ALPHA_TABLE: start-on-event=GetErrorStatus, operation=PS_CALIB_BLOCK_ID_ECPL_ALPHA_TABLE.GetErrorStatus
        OpEventGetErrorStatus_GetErrorStatus_PS_CALIB_BLOCK_ID_POWER_DEGRADATION: start-on-event=GetErrorStatus, operation=PS_CALIB_BLOCK_ID_POWER_DEGRADATION.GetErrorStatus
        OpEventGetErrorStatus_GetErrorStatus_PS_CALIB_BLOCK_ID_ECPL_BETA_TABLE: start-on-event=GetErrorStatus, operation=PS_CALIB_BLOCK_ID_ECPL_BETA_TABLE.GetErrorStatus
        OpEventGetErrorStatus_GetErrorStatus_PS_CALIB_BLOCK_ID_ECPL_OTHER_PARAM: start-on-event=GetErrorStatus, operation=PS_CALIB_BLOCK_ID_ECPL_OTHER_PARAM.GetErrorStatus
        OpEventGetErrorStatus_GetErrorStatus_PS_CALIB_BLOCK_ID_BPA_MOTOR_CURRENT: start-on-event=GetErrorStatus, operation=PS_CALIB_BLOCK_ID_BPA_MOTOR_CURRENT.GetErrorStatus
        OpEventGetErrorStatus_GetErrorStatus_PS_CALIB_BLOCK_ID_VOLT_THRS: start-on-event=GetErrorStatus, operation=PS_CALIB_BLOCK_ID_VOLT_THRS.GetErrorStatus
        OpEventGetErrorStatus_GetErrorStatus_PS_CALIB_BLOCK_ID_BATTERY_LOSS_DETECTION_THRS: start-on-event=GetErrorStatus, operation=PS_CALIB_BLOCK_ID_BATTERY_LOSS_DETECTION_THRS.GetErrorStatus
        OpEventGetErrorStatus_GetErrorStatus_PS_CALIB_BLOCK_ID_BOOST: start-on-event=GetErrorStatus, operation=PS_CALIB_BLOCK_ID_BOOST.GetErrorStatus
        OpEventGetErrorStatus_GetErrorStatus_PS_CALIB_BLOCK_ID_ECU_PROPERTIES: start-on-event=GetErrorStatus, operation=PS_CALIB_BLOCK_ID_ECU_PROPERTIES.GetErrorStatus
        OpEventGetErrorStatus_GetErrorStatus_PS_CALIB_BLOCK_ID_SW_SELF_PROTECTION_THRS: start-on-event=GetErrorStatus, operation=PS_CALIB_BLOCK_ID_SW_SELF_PROTECTION_THRS.GetErrorStatus
        OpEventGetErrorStatus_GetErrorStatus_PS_CALIB_BLOCK_ID_MOTOR_RESIST_PARAM: start-on-event=GetErrorStatus, operation=PS_CALIB_BLOCK_ID_MOTOR_RESIST_PARAM.GetErrorStatus
        OpEventGetErrorStatus_GetErrorStatus_PS_CALIB_BLOCK_ID_BOOST_ACTIVATION: start-on-event=GetErrorStatus, operation=PS_CALIB_BLOCK_ID_BOOST_ACTIVATION.GetErrorStatus
        OpEventGetErrorStatus_GetErrorStatus_PS_NVP_BLOCK_ID_MEASUREMENT_FRAME_12_CONFIG: start-on-event=GetErrorStatus, operation=PS_NVP_BLOCK_ID_MEASUREMENT_FRAME_12_CONFIG.GetErrorStatus
        OpEventGetErrorStatus_GetErrorStatus_PS_NVP_BLOCK_ID_MEASUREMENT_FRAME_CONFIG: start-on-event=GetErrorStatus, operation=PS_NVP_BLOCK_ID_MEASUREMENT_FRAME_CONFIG.GetErrorStatus
        OpEventSetRamBlockStatus_SetRamBlockStatus_PS_Ssa_CodingNvM_Coding_CodingVIN: start-on-event=SetRamBlockStatus, operation=PS_Ssa_CodingNvM_Coding_CodingVIN.SetRamBlockStatus
        OpEventSetRamBlockStatus_SetRamBlockStatus_PS_Ssa_CodingNvM_Coding_CurrentVIN: start-on-event=SetRamBlockStatus, operation=PS_Ssa_CodingNvM_Coding_CurrentVIN.SetRamBlockStatus
        OpEventSetRamBlockStatus_SetRamBlockStatus_PS_Ssa_RightsM_NvM_RightsM_AclVersion: start-on-event=SetRamBlockStatus, operation=PS_Ssa_RightsM_NvM_RightsM_AclVersion.SetRamBlockStatus
        OpEventSetRamBlockStatus_SetRamBlockStatus_PS_Ssa_RightsM_NvM_RightsM_Nonce: start-on-event=SetRamBlockStatus, operation=PS_Ssa_RightsM_NvM_RightsM_Nonce.SetRamBlockStatus
        OpEventSetRamBlockStatus_SetRamBlockStatus_PS_Ssa_RightsM_NvM_RightsM_PostProductionStatus: start-on-event=SetRamBlockStatus, operation=PS_Ssa_RightsM_NvM_RightsM_PostProductionStatus.SetRamBlockStatus
        OpEventSetRamBlockStatus_SetRamBlockStatus_PS_Ssa_SecLogNvM_SecLog_LogDataEvnt10_FailedPduMacVerif: start-on-event=SetRamBlockStatus, operation=PS_Ssa_SecLogNvM_SecLog_LogDataEvnt10_FailedPduMacVerif.SetRamBlockStatus
        OpEventSetRamBlockStatus_SetRamBlockStatus_PS_Ssa_SecLogNvM_SecLog_LogDataEvnt11_SecOrAuthBoot: start-on-event=SetRamBlockStatus, operation=PS_Ssa_SecLogNvM_SecLog_LogDataEvnt11_SecOrAuthBoot.SetRamBlockStatus
        OpEventSetRamBlockStatus_SetRamBlockStatus_PS_Ssa_SecLogNvM_SecLog_LogDataEvnt12_ChangeOfVin: start-on-event=SetRamBlockStatus, operation=PS_Ssa_SecLogNvM_SecLog_LogDataEvnt12_ChangeOfVin.SetRamBlockStatus
        OpEventSetRamBlockStatus_SetRamBlockStatus_PS_Ssa_SecLogNvM_SecLog_LogDataEvnt13_AclReplacement: start-on-event=SetRamBlockStatus, operation=PS_Ssa_SecLogNvM_SecLog_LogDataEvnt13_AclReplacement.SetRamBlockStatus
        OpEventSetRamBlockStatus_SetRamBlockStatus_PS_Ssa_SecLogNvM_SecLog_LogDataEvnt1_FailedCertVerif: start-on-event=SetRamBlockStatus, operation=PS_Ssa_SecLogNvM_SecLog_LogDataEvnt1_FailedCertVerif.SetRamBlockStatus
        OpEventSetRamBlockStatus_SetRamBlockStatus_PS_Ssa_SecLogNvM_SecLog_LogDataEvnt2_SucCertVerif: start-on-event=SetRamBlockStatus, operation=PS_Ssa_SecLogNvM_SecLog_LogDataEvnt2_SucCertVerif.SetRamBlockStatus
        OpEventSetRamBlockStatus_SetRamBlockStatus_PS_Ssa_SecLogNvM_SecLog_LogDataEvnt3_SucAuthAndEnhanceRights: start-on-event=SetRamBlockStatus, operation=PS_Ssa_SecLogNvM_SecLog_LogDataEvnt3_SucAuthAndEnhanceRights.SetRamBlockStatus
        OpEventSetRamBlockStatus_SetRamBlockStatus_PS_Ssa_SecLogNvM_SecLog_LogDataEvnt4_AuthBySecAccess: start-on-event=SetRamBlockStatus, operation=PS_Ssa_SecLogNvM_SecLog_LogDataEvnt4_AuthBySecAccess.SetRamBlockStatus
        OpEventSetRamBlockStatus_SetRamBlockStatus_PS_Ssa_SecLogNvM_SecLog_LogDataEvnt5_SucDiagServiceExec: start-on-event=SetRamBlockStatus, operation=PS_Ssa_SecLogNvM_SecLog_LogDataEvnt5_SucDiagServiceExec.SetRamBlockStatus
        OpEventSetRamBlockStatus_SetRamBlockStatus_PS_Ssa_SecLogNvM_SecLog_LogDataEvnt6_RightsMgmt: start-on-event=SetRamBlockStatus, operation=PS_Ssa_SecLogNvM_SecLog_LogDataEvnt6_RightsMgmt.SetRamBlockStatus
        OpEventSetRamBlockStatus_SetRamBlockStatus_PS_Ssa_SecLogNvM_SecLog_LogDataEvnt7_SigVerif: start-on-event=SetRamBlockStatus, operation=PS_Ssa_SecLogNvM_SecLog_LogDataEvnt7_SigVerif.SetRamBlockStatus
        OpEventSetRamBlockStatus_SetRamBlockStatus_PS_Ssa_SecLogNvM_SecLog_LogDataEvnt8_TickCountDateAndTime: start-on-event=SetRamBlockStatus, operation=PS_Ssa_SecLogNvM_SecLog_LogDataEvnt8_TickCountDateAndTime.SetRamBlockStatus
        OpEventSetRamBlockStatus_SetRamBlockStatus_PS_Ssa_SecLogNvM_SecLog_LogDataEvnt9_SecOcMisconfig: start-on-event=SetRamBlockStatus, operation=PS_Ssa_SecLogNvM_SecLog_LogDataEvnt9_SecOcMisconfig.SetRamBlockStatus
        OpEventSetRamBlockStatus_SetRamBlockStatus_PS_Ssa_SecLogNvM_SecLog_LogFailedMacVerifCount_ExceededTh{1..3}: start-on-event=SetRamBlockStatus, operation=PS_Ssa_SecLogNvM_SecLog_LogFailedMacVerifCount_ExceededTh{1..3}.SetRamBlockStatus
        OpEventSetRamBlockStatus_SetRamBlockStatus_PS_Ssa_TimeM_NvM_TimeM_RealTimeOffset: start-on-event=SetRamBlockStatus, operation=PS_Ssa_TimeM_NvM_TimeM_RealTimeOffset.SetRamBlockStatus
        OpEventSetRamBlockStatus_SetRamBlockStatus_PS_Ssa_TimeM_NvM_TimeM_TickCount: start-on-event=SetRamBlockStatus, operation=PS_Ssa_TimeM_NvM_TimeM_TickCount.SetRamBlockStatus
        OpEventSetRamBlockStatus_SetRamBlockStatus_PS_Ct_MBBL_SsaAppl_CodingNvmCoding_CurrentVehicleEquipment: start-on-event=SetRamBlockStatus, operation=PS_Ct_MBBL_SsaAppl_CodingNvmCoding_CurrentVehicleEquipment.SetRamBlockStatus
        OpEventSetRamBlockStatus_SetRamBlockStatus_PS_Ct_MBBL_SsaAppl_CodingNvmCoding_TensioningCycleBSR: start-on-event=SetRamBlockStatus, operation=PS_Ct_MBBL_SsaAppl_CodingNvmCoding_TensioningCycleBSR.SetRamBlockStatus
        OpEventSetRamBlockStatus_SetRamBlockStatus_PS_Ct_MBBL_SsaAppl_CodingNvmCoding_PreSafeCyclesLevel: start-on-event=SetRamBlockStatus, operation=PS_Ct_MBBL_SsaAppl_CodingNvmCoding_PreSafeCyclesLevel.SetRamBlockStatus
        OpEventSetRamBlockStatus_SetRamBlockStatus_PS_Ct_MBBL_SsaAppl_CodingNvmCoding_ReleaseCyclesBsrAndPreSafe: start-on-event=SetRamBlockStatus, operation=PS_Ct_MBBL_SsaAppl_CodingNvmCoding_ReleaseCyclesBsrAndPreSafe.SetRamBlockStatus
        OpEventSetRamBlockStatus_SetRamBlockStatus_PS_Ct_MBBL_SsaAppl_CodingNvmCoding_ZZZVehicleEquipmentDevelopment: start-on-event=SetRamBlockStatus, operation=PS_Ct_MBBL_SsaAppl_CodingNvmCoding_ZZZVehicleEquipmentDevelopment.SetRamBlockStatus
        OpEventSetRamBlockStatus_SetRamBlockStatus_PS_Ct_MBBL_SsaAppl_CodingNvmCoding_CalibrationID: start-on-event=SetRamBlockStatus, operation=PS_Ct_MBBL_SsaAppl_CodingNvmCoding_CalibrationID.SetRamBlockStatus
        OpEventSetRamBlockStatus_SetRamBlockStatus_PS_NvMBlockDescriptor_FblMetaData: start-on-event=SetRamBlockStatus, operation=PS_NvMBlockDescriptor_FblMetaData.SetRamBlockStatus
        OpEventSetRamBlockStatus_SetRamBlockStatus_PS_NVP_BLOCK_ID_ECU_LOCATION: start-on-event=SetRamBlockStatus, operation=PS_NVP_BLOCK_ID_ECU_LOCATION.SetRamBlockStatus
        OpEventSetRamBlockStatus_SetRamBlockStatus_PS_NVP_BLOCK_ID_BELT_ASSEMBLY_MANUF_DATE_AND_SN: start-on-event=SetRamBlockStatus, operation=PS_NVP_BLOCK_ID_BELT_ASSEMBLY_MANUF_DATE_AND_SN.SetRamBlockStatus
        OpEventSetRamBlockStatus_SetRamBlockStatus_PS_NVP_BLOCK_ID_HB_CALIBRATION: start-on-event=SetRamBlockStatus, operation=PS_NVP_BLOCK_ID_HB_CALIBRATION.SetRamBlockStatus
        OpEventSetRamBlockStatus_SetRamBlockStatus_PS_NVP_BLOCK_ID_AEE_TRACEABILITY: start-on-event=SetRamBlockStatus, operation=PS_NVP_BLOCK_ID_AEE_TRACEABILITY.SetRamBlockStatus
        OpEventSetRamBlockStatus_SetRamBlockStatus_PS_NVP_BLOCK_ID_EXECUTION_COUNTERS: start-on-event=SetRamBlockStatus, operation=PS_NVP_BLOCK_ID_EXECUTION_COUNTERS.SetRamBlockStatus
        OpEventSetRamBlockStatus_SetRamBlockStatus_PS_NVP_BLOCK_ID_TESTS_PARAM: start-on-event=SetRamBlockStatus, operation=PS_NVP_BLOCK_ID_TESTS_PARAM.SetRamBlockStatus
        OpEventSetRamBlockStatus_SetRamBlockStatus_PS_NVP_BLOCK_ID_CYCLE: start-on-event=SetRamBlockStatus, operation=PS_NVP_BLOCK_ID_CYCLE.SetRamBlockStatus
        OpEventSetRamBlockStatus_SetRamBlockStatus_PS_NVP_BLOCK_ID_STEP: start-on-event=SetRamBlockStatus, operation=PS_NVP_BLOCK_ID_STEP.SetRamBlockStatus
        OpEventSetRamBlockStatus_SetRamBlockStatus_PS_CALIB_BLOCK_ID_EOL_PARAM: start-on-event=SetRamBlockStatus, operation=PS_CALIB_BLOCK_ID_EOL_PARAM.SetRamBlockStatus
        OpEventSetRamBlockStatus_SetRamBlockStatus_PS_CALIB_BLOCK_ID_BFS_PRIO_PARAM: start-on-event=SetRamBlockStatus, operation=PS_CALIB_BLOCK_ID_BFS_PRIO_PARAM.SetRamBlockStatus
        OpEventSetRamBlockStatus_SetRamBlockStatus_PS_CALIB_BLOCK_ID_PID_PARAM: start-on-event=SetRamBlockStatus, operation=PS_CALIB_BLOCK_ID_PID_PARAM.SetRamBlockStatus
        OpEventSetRamBlockStatus_SetRamBlockStatus_PS_CALIB_BLOCK_ID_WEIGHT_REL_TABLE: start-on-event=SetRamBlockStatus, operation=PS_CALIB_BLOCK_ID_WEIGHT_REL_TABLE.SetRamBlockStatus
        OpEventSetRamBlockStatus_SetRamBlockStatus_PS_CALIB_BLOCK_ID_WEIGHT_TENS{0..3}_TABLE: start-on-event=SetRamBlockStatus, operation=PS_CALIB_BLOCK_ID_WEIGHT_TENS{0..3}_TABLE.SetRamBlockStatus
        OpEventSetRamBlockStatus_SetRamBlockStatus_PS_CALIB_BLOCK_ID_INT_CURRENT_CORR: start-on-event=SetRamBlockStatus, operation=PS_CALIB_BLOCK_ID_INT_CURRENT_CORR.SetRamBlockStatus
        OpEventSetRamBlockStatus_SetRamBlockStatus_PS_CALIB_BLOCK_ID_INT_CURRENT_TABLE: start-on-event=SetRamBlockStatus, operation=PS_CALIB_BLOCK_ID_INT_CURRENT_TABLE.SetRamBlockStatus
        OpEventSetRamBlockStatus_SetRamBlockStatus_PS_CALIB_BLOCK_ID_ECPL_ALPHA_TABLE: start-on-event=SetRamBlockStatus, operation=PS_CALIB_BLOCK_ID_ECPL_ALPHA_TABLE.SetRamBlockStatus
        OpEventSetRamBlockStatus_SetRamBlockStatus_PS_CALIB_BLOCK_ID_POWER_DEGRADATION: start-on-event=SetRamBlockStatus, operation=PS_CALIB_BLOCK_ID_POWER_DEGRADATION.SetRamBlockStatus
        OpEventSetRamBlockStatus_SetRamBlockStatus_PS_CALIB_BLOCK_ID_ECPL_BETA_TABLE: start-on-event=SetRamBlockStatus, operation=PS_CALIB_BLOCK_ID_ECPL_BETA_TABLE.SetRamBlockStatus
        OpEventSetRamBlockStatus_SetRamBlockStatus_PS_CALIB_BLOCK_ID_ECPL_OTHER_PARAM: start-on-event=SetRamBlockStatus, operation=PS_CALIB_BLOCK_ID_ECPL_OTHER_PARAM.SetRamBlockStatus
        OpEventSetRamBlockStatus_SetRamBlockStatus_PS_CALIB_BLOCK_ID_BPA_MOTOR_CURRENT: start-on-event=SetRamBlockStatus, operation=PS_CALIB_BLOCK_ID_BPA_MOTOR_CURRENT.SetRamBlockStatus
        OpEventSetRamBlockStatus_SetRamBlockStatus_PS_CALIB_BLOCK_ID_VOLT_THRS: start-on-event=SetRamBlockStatus, operation=PS_CALIB_BLOCK_ID_VOLT_THRS.SetRamBlockStatus
        OpEventSetRamBlockStatus_SetRamBlockStatus_PS_CALIB_BLOCK_ID_BATTERY_LOSS_DETECTION_THRS: start-on-event=SetRamBlockStatus, operation=PS_CALIB_BLOCK_ID_BATTERY_LOSS_DETECTION_THRS.SetRamBlockStatus
        OpEventSetRamBlockStatus_SetRamBlockStatus_PS_CALIB_BLOCK_ID_BOOST: start-on-event=SetRamBlockStatus, operation=PS_CALIB_BLOCK_ID_BOOST.SetRamBlockStatus
        OpEventSetRamBlockStatus_SetRamBlockStatus_PS_CALIB_BLOCK_ID_ECU_PROPERTIES: start-on-event=SetRamBlockStatus, operation=PS_CALIB_BLOCK_ID_ECU_PROPERTIES.SetRamBlockStatus
        OpEventSetRamBlockStatus_SetRamBlockStatus_PS_CALIB_BLOCK_ID_SW_SELF_PROTECTION_THRS: start-on-event=SetRamBlockStatus, operation=PS_CALIB_BLOCK_ID_SW_SELF_PROTECTION_THRS.SetRamBlockStatus
        OpEventSetRamBlockStatus_SetRamBlockStatus_PS_CALIB_BLOCK_ID_MOTOR_RESIST_PARAM: start-on-event=SetRamBlockStatus, operation=PS_CALIB_BLOCK_ID_MOTOR_RESIST_PARAM.SetRamBlockStatus
        OpEventSetRamBlockStatus_SetRamBlockStatus_PS_CALIB_BLOCK_ID_BOOST_ACTIVATION: start-on-event=SetRamBlockStatus, operation=PS_CALIB_BLOCK_ID_BOOST_ACTIVATION.SetRamBlockStatus
        OpEventSetRamBlockStatus_SetRamBlockStatus_PS_NVP_BLOCK_ID_MEASUREMENT_FRAME_12_CONFIG: start-on-event=SetRamBlockStatus, operation=PS_NVP_BLOCK_ID_MEASUREMENT_FRAME_12_CONFIG.SetRamBlockStatus
        OpEventSetRamBlockStatus_SetRamBlockStatus_PS_NVP_BLOCK_ID_MEASUREMENT_FRAME_CONFIG: start-on-event=SetRamBlockStatus, operation=PS_NVP_BLOCK_ID_MEASUREMENT_FRAME_CONFIG.SetRamBlockStatus
        OpEventReadBlock_ReadBlock_PS_Ssa_CodingNvM_Coding_CodingVIN: start-on-event=ReadBlock, operation=PS_Ssa_CodingNvM_Coding_CodingVIN.ReadBlock
        OpEventReadBlock_ReadBlock_PS_Ssa_CodingNvM_Coding_CurrentVIN: start-on-event=ReadBlock, operation=PS_Ssa_CodingNvM_Coding_CurrentVIN.ReadBlock
        OpEventReadBlock_ReadBlock_PS_Ssa_RightsM_NvM_RightsM_AclVersion: start-on-event=ReadBlock, operation=PS_Ssa_RightsM_NvM_RightsM_AclVersion.ReadBlock
        OpEventReadBlock_ReadBlock_PS_Ssa_RightsM_NvM_RightsM_Nonce: start-on-event=ReadBlock, operation=PS_Ssa_RightsM_NvM_RightsM_Nonce.ReadBlock
        OpEventReadBlock_ReadBlock_PS_Ssa_RightsM_NvM_RightsM_PostProductionStatus: start-on-event=ReadBlock, operation=PS_Ssa_RightsM_NvM_RightsM_PostProductionStatus.ReadBlock
        OpEventReadBlock_ReadBlock_PS_Ssa_SecLogNvM_SecLog_LogDataEvnt10_FailedPduMacVerif: start-on-event=ReadBlock, operation=PS_Ssa_SecLogNvM_SecLog_LogDataEvnt10_FailedPduMacVerif.ReadBlock
        OpEventReadBlock_ReadBlock_PS_Ssa_SecLogNvM_SecLog_LogDataEvnt11_SecOrAuthBoot: start-on-event=ReadBlock, operation=PS_Ssa_SecLogNvM_SecLog_LogDataEvnt11_SecOrAuthBoot.ReadBlock
        OpEventReadBlock_ReadBlock_PS_Ssa_SecLogNvM_SecLog_LogDataEvnt12_ChangeOfVin: start-on-event=ReadBlock, operation=PS_Ssa_SecLogNvM_SecLog_LogDataEvnt12_ChangeOfVin.ReadBlock
        OpEventReadBlock_ReadBlock_PS_Ssa_SecLogNvM_SecLog_LogDataEvnt13_AclReplacement: start-on-event=ReadBlock, operation=PS_Ssa_SecLogNvM_SecLog_LogDataEvnt13_AclReplacement.ReadBlock
        OpEventReadBlock_ReadBlock_PS_Ssa_SecLogNvM_SecLog_LogDataEvnt1_FailedCertVerif: start-on-event=ReadBlock, operation=PS_Ssa_SecLogNvM_SecLog_LogDataEvnt1_FailedCertVerif.ReadBlock
        OpEventReadBlock_ReadBlock_PS_Ssa_SecLogNvM_SecLog_LogDataEvnt2_SucCertVerif: start-on-event=ReadBlock, operation=PS_Ssa_SecLogNvM_SecLog_LogDataEvnt2_SucCertVerif.ReadBlock
        OpEventReadBlock_ReadBlock_PS_Ssa_SecLogNvM_SecLog_LogDataEvnt3_SucAuthAndEnhanceRights: start-on-event=ReadBlock, operation=PS_Ssa_SecLogNvM_SecLog_LogDataEvnt3_SucAuthAndEnhanceRights.ReadBlock
        OpEventReadBlock_ReadBlock_PS_Ssa_SecLogNvM_SecLog_LogDataEvnt4_AuthBySecAccess: start-on-event=ReadBlock, operation=PS_Ssa_SecLogNvM_SecLog_LogDataEvnt4_AuthBySecAccess.ReadBlock
        OpEventReadBlock_ReadBlock_PS_Ssa_SecLogNvM_SecLog_LogDataEvnt5_SucDiagServiceExec: start-on-event=ReadBlock, operation=PS_Ssa_SecLogNvM_SecLog_LogDataEvnt5_SucDiagServiceExec.ReadBlock
        OpEventReadBlock_ReadBlock_PS_Ssa_SecLogNvM_SecLog_LogDataEvnt6_RightsMgmt: start-on-event=ReadBlock, operation=PS_Ssa_SecLogNvM_SecLog_LogDataEvnt6_RightsMgmt.ReadBlock
        OpEventReadBlock_ReadBlock_PS_Ssa_SecLogNvM_SecLog_LogDataEvnt7_SigVerif: start-on-event=ReadBlock, operation=PS_Ssa_SecLogNvM_SecLog_LogDataEvnt7_SigVerif.ReadBlock
        OpEventReadBlock_ReadBlock_PS_Ssa_SecLogNvM_SecLog_LogDataEvnt8_TickCountDateAndTime: start-on-event=ReadBlock, operation=PS_Ssa_SecLogNvM_SecLog_LogDataEvnt8_TickCountDateAndTime.ReadBlock
        OpEventReadBlock_ReadBlock_PS_Ssa_SecLogNvM_SecLog_LogDataEvnt9_SecOcMisconfig: start-on-event=ReadBlock, operation=PS_Ssa_SecLogNvM_SecLog_LogDataEvnt9_SecOcMisconfig.ReadBlock
        OpEventReadBlock_ReadBlock_PS_Ssa_SecLogNvM_SecLog_LogFailedMacVerifCount_ExceededTh{1..3}: start-on-event=ReadBlock, operation=PS_Ssa_SecLogNvM_SecLog_LogFailedMacVerifCount_ExceededTh{1..3}.ReadBlock
        OpEventReadBlock_ReadBlock_PS_Ssa_TimeM_NvM_TimeM_RealTimeOffset: start-on-event=ReadBlock, operation=PS_Ssa_TimeM_NvM_TimeM_RealTimeOffset.ReadBlock
        OpEventReadBlock_ReadBlock_PS_Ssa_TimeM_NvM_TimeM_TickCount: start-on-event=ReadBlock, operation=PS_Ssa_TimeM_NvM_TimeM_TickCount.ReadBlock
        OpEventReadBlock_ReadBlock_PS_Ct_MBBL_SsaAppl_CodingNvmCoding_CurrentVehicleEquipment: start-on-event=ReadBlock, operation=PS_Ct_MBBL_SsaAppl_CodingNvmCoding_CurrentVehicleEquipment.ReadBlock
        OpEventReadBlock_ReadBlock_PS_Ct_MBBL_SsaAppl_CodingNvmCoding_TensioningCycleBSR: start-on-event=ReadBlock, operation=PS_Ct_MBBL_SsaAppl_CodingNvmCoding_TensioningCycleBSR.ReadBlock
        OpEventReadBlock_ReadBlock_PS_Ct_MBBL_SsaAppl_CodingNvmCoding_PreSafeCyclesLevel: start-on-event=ReadBlock, operation=PS_Ct_MBBL_SsaAppl_CodingNvmCoding_PreSafeCyclesLevel.ReadBlock
        OpEventReadBlock_ReadBlock_PS_Ct_MBBL_SsaAppl_CodingNvmCoding_ReleaseCyclesBsrAndPreSafe: start-on-event=ReadBlock, operation=PS_Ct_MBBL_SsaAppl_CodingNvmCoding_ReleaseCyclesBsrAndPreSafe.ReadBlock
        OpEventReadBlock_ReadBlock_PS_Ct_MBBL_SsaAppl_CodingNvmCoding_ZZZVehicleEquipmentDevelopment: start-on-event=ReadBlock, operation=PS_Ct_MBBL_SsaAppl_CodingNvmCoding_ZZZVehicleEquipmentDevelopment.ReadBlock
        OpEventReadBlock_ReadBlock_PS_Ct_MBBL_SsaAppl_CodingNvmCoding_CalibrationID: start-on-event=ReadBlock, operation=PS_Ct_MBBL_SsaAppl_CodingNvmCoding_CalibrationID.ReadBlock
        OpEventReadBlock_ReadBlock_PS_NvMBlockDescriptor_FblMetaData: start-on-event=ReadBlock, operation=PS_NvMBlockDescriptor_FblMetaData.ReadBlock
        OpEventReadBlock_ReadBlock_PS_NVP_BLOCK_ID_ECU_LOCATION: start-on-event=ReadBlock, operation=PS_NVP_BLOCK_ID_ECU_LOCATION.ReadBlock
        OpEventReadBlock_ReadBlock_PS_NVP_BLOCK_ID_BELT_ASSEMBLY_MANUF_DATE_AND_SN: start-on-event=ReadBlock, operation=PS_NVP_BLOCK_ID_BELT_ASSEMBLY_MANUF_DATE_AND_SN.ReadBlock
        OpEventReadBlock_ReadBlock_PS_NVP_BLOCK_ID_HB_CALIBRATION: start-on-event=ReadBlock, operation=PS_NVP_BLOCK_ID_HB_CALIBRATION.ReadBlock
        OpEventReadBlock_ReadBlock_PS_NVP_BLOCK_ID_AEE_TRACEABILITY: start-on-event=ReadBlock, operation=PS_NVP_BLOCK_ID_AEE_TRACEABILITY.ReadBlock
        OpEventReadBlock_ReadBlock_PS_NVP_BLOCK_ID_EXECUTION_COUNTERS: start-on-event=ReadBlock, operation=PS_NVP_BLOCK_ID_EXECUTION_COUNTERS.ReadBlock
        OpEventReadBlock_ReadBlock_PS_NVP_BLOCK_ID_TESTS_PARAM: start-on-event=ReadBlock, operation=PS_NVP_BLOCK_ID_TESTS_PARAM.ReadBlock
        OpEventReadBlock_ReadBlock_PS_NVP_BLOCK_ID_CYCLE: start-on-event=ReadBlock, operation=PS_NVP_BLOCK_ID_CYCLE.ReadBlock
        OpEventReadBlock_ReadBlock_PS_NVP_BLOCK_ID_STEP: start-on-event=ReadBlock, operation=PS_NVP_BLOCK_ID_STEP.ReadBlock
        OpEventReadBlock_ReadBlock_PS_CALIB_BLOCK_ID_EOL_PARAM: start-on-event=ReadBlock, operation=PS_CALIB_BLOCK_ID_EOL_PARAM.ReadBlock
        OpEventReadBlock_ReadBlock_PS_CALIB_BLOCK_ID_BFS_PRIO_PARAM: start-on-event=ReadBlock, operation=PS_CALIB_BLOCK_ID_BFS_PRIO_PARAM.ReadBlock
        OpEventReadBlock_ReadBlock_PS_CALIB_BLOCK_ID_PID_PARAM: start-on-event=ReadBlock, operation=PS_CALIB_BLOCK_ID_PID_PARAM.ReadBlock
        OpEventReadBlock_ReadBlock_PS_CALIB_BLOCK_ID_WEIGHT_REL_TABLE: start-on-event=ReadBlock, operation=PS_CALIB_BLOCK_ID_WEIGHT_REL_TABLE.ReadBlock
        OpEventReadBlock_ReadBlock_PS_CALIB_BLOCK_ID_WEIGHT_TENS{0..3}_TABLE: start-on-event=ReadBlock, operation=PS_CALIB_BLOCK_ID_WEIGHT_TENS{0..3}_TABLE.ReadBlock
        OpEventReadBlock_ReadBlock_PS_CALIB_BLOCK_ID_INT_CURRENT_CORR: start-on-event=ReadBlock, operation=PS_CALIB_BLOCK_ID_INT_CURRENT_CORR.ReadBlock
        OpEventReadBlock_ReadBlock_PS_CALIB_BLOCK_ID_INT_CURRENT_TABLE: start-on-event=ReadBlock, operation=PS_CALIB_BLOCK_ID_INT_CURRENT_TABLE.ReadBlock
        OpEventReadBlock_ReadBlock_PS_CALIB_BLOCK_ID_ECPL_ALPHA_TABLE: start-on-event=ReadBlock, operation=PS_CALIB_BLOCK_ID_ECPL_ALPHA_TABLE.ReadBlock
        OpEventReadBlock_ReadBlock_PS_CALIB_BLOCK_ID_POWER_DEGRADATION: start-on-event=ReadBlock, operation=PS_CALIB_BLOCK_ID_POWER_DEGRADATION.ReadBlock
        OpEventReadBlock_ReadBlock_PS_CALIB_BLOCK_ID_ECPL_BETA_TABLE: start-on-event=ReadBlock, operation=PS_CALIB_BLOCK_ID_ECPL_BETA_TABLE.ReadBlock
        OpEventReadBlock_ReadBlock_PS_CALIB_BLOCK_ID_ECPL_OTHER_PARAM: start-on-event=ReadBlock, operation=PS_CALIB_BLOCK_ID_ECPL_OTHER_PARAM.ReadBlock
        OpEventReadBlock_ReadBlock_PS_CALIB_BLOCK_ID_BPA_MOTOR_CURRENT: start-on-event=ReadBlock, operation=PS_CALIB_BLOCK_ID_BPA_MOTOR_CURRENT.ReadBlock
        OpEventReadBlock_ReadBlock_PS_CALIB_BLOCK_ID_VOLT_THRS: start-on-event=ReadBlock, operation=PS_CALIB_BLOCK_ID_VOLT_THRS.ReadBlock
        OpEventReadBlock_ReadBlock_PS_CALIB_BLOCK_ID_BATTERY_LOSS_DETECTION_THRS: start-on-event=ReadBlock, operation=PS_CALIB_BLOCK_ID_BATTERY_LOSS_DETECTION_THRS.ReadBlock
        OpEventReadBlock_ReadBlock_PS_CALIB_BLOCK_ID_BOOST: start-on-event=ReadBlock, operation=PS_CALIB_BLOCK_ID_BOOST.ReadBlock
        OpEventReadBlock_ReadBlock_PS_CALIB_BLOCK_ID_ECU_PROPERTIES: start-on-event=ReadBlock, operation=PS_CALIB_BLOCK_ID_ECU_PROPERTIES.ReadBlock
        OpEventReadBlock_ReadBlock_PS_CALIB_BLOCK_ID_SW_SELF_PROTECTION_THRS: start-on-event=ReadBlock, operation=PS_CALIB_BLOCK_ID_SW_SELF_PROTECTION_THRS.ReadBlock
        OpEventReadBlock_ReadBlock_PS_CALIB_BLOCK_ID_MOTOR_RESIST_PARAM: start-on-event=ReadBlock, operation=PS_CALIB_BLOCK_ID_MOTOR_RESIST_PARAM.ReadBlock
        OpEventReadBlock_ReadBlock_PS_CALIB_BLOCK_ID_BOOST_ACTIVATION: start-on-event=ReadBlock, operation=PS_CALIB_BLOCK_ID_BOOST_ACTIVATION.ReadBlock
        OpEventReadBlock_ReadBlock_PS_NVP_BLOCK_ID_MEASUREMENT_FRAME_12_CONFIG: start-on-event=ReadBlock, operation=PS_NVP_BLOCK_ID_MEASUREMENT_FRAME_12_CONFIG.ReadBlock
        OpEventReadBlock_ReadBlock_PS_NVP_BLOCK_ID_MEASUREMENT_FRAME_CONFIG: start-on-event=ReadBlock, operation=PS_NVP_BLOCK_ID_MEASUREMENT_FRAME_CONFIG.ReadBlock
        OpEventWriteBlock_WriteBlock_PS_Ssa_CodingNvM_Coding_CodingVIN: start-on-event=WriteBlock, operation=PS_Ssa_CodingNvM_Coding_CodingVIN.WriteBlock
        OpEventWriteBlock_WriteBlock_PS_Ssa_CodingNvM_Coding_CurrentVIN: start-on-event=WriteBlock, operation=PS_Ssa_CodingNvM_Coding_CurrentVIN.WriteBlock
        OpEventWriteBlock_WriteBlock_PS_Ssa_RightsM_NvM_RightsM_AclVersion: start-on-event=WriteBlock, operation=PS_Ssa_RightsM_NvM_RightsM_AclVersion.WriteBlock
        OpEventWriteBlock_WriteBlock_PS_Ssa_RightsM_NvM_RightsM_Nonce: start-on-event=WriteBlock, operation=PS_Ssa_RightsM_NvM_RightsM_Nonce.WriteBlock
        OpEventWriteBlock_WriteBlock_PS_Ssa_RightsM_NvM_RightsM_PostProductionStatus: start-on-event=WriteBlock, operation=PS_Ssa_RightsM_NvM_RightsM_PostProductionStatus.WriteBlock
        OpEventWriteBlock_WriteBlock_PS_Ssa_SecLogNvM_SecLog_LogDataEvnt10_FailedPduMacVerif: start-on-event=WriteBlock, operation=PS_Ssa_SecLogNvM_SecLog_LogDataEvnt10_FailedPduMacVerif.WriteBlock
        OpEventWriteBlock_WriteBlock_PS_Ssa_SecLogNvM_SecLog_LogDataEvnt11_SecOrAuthBoot: start-on-event=WriteBlock, operation=PS_Ssa_SecLogNvM_SecLog_LogDataEvnt11_SecOrAuthBoot.WriteBlock
        OpEventWriteBlock_WriteBlock_PS_Ssa_SecLogNvM_SecLog_LogDataEvnt12_ChangeOfVin: start-on-event=WriteBlock, operation=PS_Ssa_SecLogNvM_SecLog_LogDataEvnt12_ChangeOfVin.WriteBlock
        OpEventWriteBlock_WriteBlock_PS_Ssa_SecLogNvM_SecLog_LogDataEvnt13_AclReplacement: start-on-event=WriteBlock, operation=PS_Ssa_SecLogNvM_SecLog_LogDataEvnt13_AclReplacement.WriteBlock
        OpEventWriteBlock_WriteBlock_PS_Ssa_SecLogNvM_SecLog_LogDataEvnt1_FailedCertVerif: start-on-event=WriteBlock, operation=PS_Ssa_SecLogNvM_SecLog_LogDataEvnt1_FailedCertVerif.WriteBlock
        OpEventWriteBlock_WriteBlock_PS_Ssa_SecLogNvM_SecLog_LogDataEvnt2_SucCertVerif: start-on-event=WriteBlock, operation=PS_Ssa_SecLogNvM_SecLog_LogDataEvnt2_SucCertVerif.WriteBlock
        OpEventWriteBlock_WriteBlock_PS_Ssa_SecLogNvM_SecLog_LogDataEvnt3_SucAuthAndEnhanceRights: start-on-event=WriteBlock, operation=PS_Ssa_SecLogNvM_SecLog_LogDataEvnt3_SucAuthAndEnhanceRights.WriteBlock
        OpEventWriteBlock_WriteBlock_PS_Ssa_SecLogNvM_SecLog_LogDataEvnt4_AuthBySecAccess: start-on-event=WriteBlock, operation=PS_Ssa_SecLogNvM_SecLog_LogDataEvnt4_AuthBySecAccess.WriteBlock
        OpEventWriteBlock_WriteBlock_PS_Ssa_SecLogNvM_SecLog_LogDataEvnt5_SucDiagServiceExec: start-on-event=WriteBlock, operation=PS_Ssa_SecLogNvM_SecLog_LogDataEvnt5_SucDiagServiceExec.WriteBlock
        OpEventWriteBlock_WriteBlock_PS_Ssa_SecLogNvM_SecLog_LogDataEvnt6_RightsMgmt: start-on-event=WriteBlock, operation=PS_Ssa_SecLogNvM_SecLog_LogDataEvnt6_RightsMgmt.WriteBlock
        OpEventWriteBlock_WriteBlock_PS_Ssa_SecLogNvM_SecLog_LogDataEvnt7_SigVerif: start-on-event=WriteBlock, operation=PS_Ssa_SecLogNvM_SecLog_LogDataEvnt7_SigVerif.WriteBlock
        OpEventWriteBlock_WriteBlock_PS_Ssa_SecLogNvM_SecLog_LogDataEvnt8_TickCountDateAndTime: start-on-event=WriteBlock, operation=PS_Ssa_SecLogNvM_SecLog_LogDataEvnt8_TickCountDateAndTime.WriteBlock
        OpEventWriteBlock_WriteBlock_PS_Ssa_SecLogNvM_SecLog_LogDataEvnt9_SecOcMisconfig: start-on-event=WriteBlock, operation=PS_Ssa_SecLogNvM_SecLog_LogDataEvnt9_SecOcMisconfig.WriteBlock
        OpEventWriteBlock_WriteBlock_PS_Ssa_SecLogNvM_SecLog_LogFailedMacVerifCount_ExceededTh{1..3}: start-on-event=WriteBlock, operation=PS_Ssa_SecLogNvM_SecLog_LogFailedMacVerifCount_ExceededTh{1..3}.WriteBlock
        OpEventWriteBlock_WriteBlock_PS_Ssa_TimeM_NvM_TimeM_RealTimeOffset: start-on-event=WriteBlock, operation=PS_Ssa_TimeM_NvM_TimeM_RealTimeOffset.WriteBlock
        OpEventWriteBlock_WriteBlock_PS_Ssa_TimeM_NvM_TimeM_TickCount: start-on-event=WriteBlock, operation=PS_Ssa_TimeM_NvM_TimeM_TickCount.WriteBlock
        OpEventWriteBlock_WriteBlock_PS_Ct_MBBL_SsaAppl_CodingNvmCoding_CurrentVehicleEquipment: start-on-event=WriteBlock, operation=PS_Ct_MBBL_SsaAppl_CodingNvmCoding_CurrentVehicleEquipment.WriteBlock
        OpEventWriteBlock_WriteBlock_PS_Ct_MBBL_SsaAppl_CodingNvmCoding_TensioningCycleBSR: start-on-event=WriteBlock, operation=PS_Ct_MBBL_SsaAppl_CodingNvmCoding_TensioningCycleBSR.WriteBlock
        OpEventWriteBlock_WriteBlock_PS_Ct_MBBL_SsaAppl_CodingNvmCoding_PreSafeCyclesLevel: start-on-event=WriteBlock, operation=PS_Ct_MBBL_SsaAppl_CodingNvmCoding_PreSafeCyclesLevel.WriteBlock
        OpEventWriteBlock_WriteBlock_PS_Ct_MBBL_SsaAppl_CodingNvmCoding_ReleaseCyclesBsrAndPreSafe: start-on-event=WriteBlock, operation=PS_Ct_MBBL_SsaAppl_CodingNvmCoding_ReleaseCyclesBsrAndPreSafe.WriteBlock
        OpEventWriteBlock_WriteBlock_PS_Ct_MBBL_SsaAppl_CodingNvmCoding_ZZZVehicleEquipmentDevelopment: start-on-event=WriteBlock, operation=PS_Ct_MBBL_SsaAppl_CodingNvmCoding_ZZZVehicleEquipmentDevelopment.WriteBlock
        OpEventWriteBlock_WriteBlock_PS_Ct_MBBL_SsaAppl_CodingNvmCoding_CalibrationID: start-on-event=WriteBlock, operation=PS_Ct_MBBL_SsaAppl_CodingNvmCoding_CalibrationID.WriteBlock
        OpEventWriteBlock_WriteBlock_PS_NvMBlockDescriptor_FblMetaData: start-on-event=WriteBlock, operation=PS_NvMBlockDescriptor_FblMetaData.WriteBlock
        OpEventWriteBlock_WriteBlock_PS_NVP_BLOCK_ID_ECU_LOCATION: start-on-event=WriteBlock, operation=PS_NVP_BLOCK_ID_ECU_LOCATION.WriteBlock
        OpEventWriteBlock_WriteBlock_PS_NVP_BLOCK_ID_BELT_ASSEMBLY_MANUF_DATE_AND_SN: start-on-event=WriteBlock, operation=PS_NVP_BLOCK_ID_BELT_ASSEMBLY_MANUF_DATE_AND_SN.WriteBlock
        OpEventWriteBlock_WriteBlock_PS_NVP_BLOCK_ID_HB_CALIBRATION: start-on-event=WriteBlock, operation=PS_NVP_BLOCK_ID_HB_CALIBRATION.WriteBlock
        OpEventWriteBlock_WriteBlock_PS_NVP_BLOCK_ID_AEE_TRACEABILITY: start-on-event=WriteBlock, operation=PS_NVP_BLOCK_ID_AEE_TRACEABILITY.WriteBlock
        OpEventWriteBlock_WriteBlock_PS_NVP_BLOCK_ID_EXECUTION_COUNTERS: start-on-event=WriteBlock, operation=PS_NVP_BLOCK_ID_EXECUTION_COUNTERS.WriteBlock
        OpEventWriteBlock_WriteBlock_PS_NVP_BLOCK_ID_TESTS_PARAM: start-on-event=WriteBlock, operation=PS_NVP_BLOCK_ID_TESTS_PARAM.WriteBlock
        OpEventWriteBlock_WriteBlock_PS_NVP_BLOCK_ID_CYCLE: start-on-event=WriteBlock, operation=PS_NVP_BLOCK_ID_CYCLE.WriteBlock
        OpEventWriteBlock_WriteBlock_PS_NVP_BLOCK_ID_STEP: start-on-event=WriteBlock, operation=PS_NVP_BLOCK_ID_STEP.WriteBlock
        OpEventWriteBlock_WriteBlock_PS_CALIB_BLOCK_ID_EOL_PARAM: start-on-event=WriteBlock, operation=PS_CALIB_BLOCK_ID_EOL_PARAM.WriteBlock
        OpEventWriteBlock_WriteBlock_PS_CALIB_BLOCK_ID_BFS_PRIO_PARAM: start-on-event=WriteBlock, operation=PS_CALIB_BLOCK_ID_BFS_PRIO_PARAM.WriteBlock
        OpEventWriteBlock_WriteBlock_PS_CALIB_BLOCK_ID_PID_PARAM: start-on-event=WriteBlock, operation=PS_CALIB_BLOCK_ID_PID_PARAM.WriteBlock
        OpEventWriteBlock_WriteBlock_PS_CALIB_BLOCK_ID_WEIGHT_REL_TABLE: start-on-event=WriteBlock, operation=PS_CALIB_BLOCK_ID_WEIGHT_REL_TABLE.WriteBlock
        OpEventWriteBlock_WriteBlock_PS_CALIB_BLOCK_ID_WEIGHT_TENS{0..3}_TABLE: start-on-event=WriteBlock, operation=PS_CALIB_BLOCK_ID_WEIGHT_TENS{0..3}_TABLE.WriteBlock
        OpEventWriteBlock_WriteBlock_PS_CALIB_BLOCK_ID_INT_CURRENT_CORR: start-on-event=WriteBlock, operation=PS_CALIB_BLOCK_ID_INT_CURRENT_CORR.WriteBlock
        OpEventWriteBlock_WriteBlock_PS_CALIB_BLOCK_ID_INT_CURRENT_TABLE: start-on-event=WriteBlock, operation=PS_CALIB_BLOCK_ID_INT_CURRENT_TABLE.WriteBlock
        OpEventWriteBlock_WriteBlock_PS_CALIB_BLOCK_ID_ECPL_ALPHA_TABLE: start-on-event=WriteBlock, operation=PS_CALIB_BLOCK_ID_ECPL_ALPHA_TABLE.WriteBlock
        OpEventWriteBlock_WriteBlock_PS_CALIB_BLOCK_ID_POWER_DEGRADATION: start-on-event=WriteBlock, operation=PS_CALIB_BLOCK_ID_POWER_DEGRADATION.WriteBlock
        OpEventWriteBlock_WriteBlock_PS_CALIB_BLOCK_ID_ECPL_BETA_TABLE: start-on-event=WriteBlock, operation=PS_CALIB_BLOCK_ID_ECPL_BETA_TABLE.WriteBlock
        OpEventWriteBlock_WriteBlock_PS_CALIB_BLOCK_ID_ECPL_OTHER_PARAM: start-on-event=WriteBlock, operation=PS_CALIB_BLOCK_ID_ECPL_OTHER_PARAM.WriteBlock
        OpEventWriteBlock_WriteBlock_PS_CALIB_BLOCK_ID_BPA_MOTOR_CURRENT: start-on-event=WriteBlock, operation=PS_CALIB_BLOCK_ID_BPA_MOTOR_CURRENT.WriteBlock
        OpEventWriteBlock_WriteBlock_PS_CALIB_BLOCK_ID_VOLT_THRS: start-on-event=WriteBlock, operation=PS_CALIB_BLOCK_ID_VOLT_THRS.WriteBlock
        OpEventWriteBlock_WriteBlock_PS_CALIB_BLOCK_ID_BATTERY_LOSS_DETECTION_THRS: start-on-event=WriteBlock, operation=PS_CALIB_BLOCK_ID_BATTERY_LOSS_DETECTION_THRS.WriteBlock
        OpEventWriteBlock_WriteBlock_PS_CALIB_BLOCK_ID_BOOST: start-on-event=WriteBlock, operation=PS_CALIB_BLOCK_ID_BOOST.WriteBlock
        OpEventWriteBlock_WriteBlock_PS_CALIB_BLOCK_ID_ECU_PROPERTIES: start-on-event=WriteBlock, operation=PS_CALIB_BLOCK_ID_ECU_PROPERTIES.WriteBlock
        OpEventWriteBlock_WriteBlock_PS_CALIB_BLOCK_ID_SW_SELF_PROTECTION_THRS: start-on-event=WriteBlock, operation=PS_CALIB_BLOCK_ID_SW_SELF_PROTECTION_THRS.WriteBlock
        OpEventWriteBlock_WriteBlock_PS_CALIB_BLOCK_ID_MOTOR_RESIST_PARAM: start-on-event=WriteBlock, operation=PS_CALIB_BLOCK_ID_MOTOR_RESIST_PARAM.WriteBlock
        OpEventWriteBlock_WriteBlock_PS_CALIB_BLOCK_ID_BOOST_ACTIVATION: start-on-event=WriteBlock, operation=PS_CALIB_BLOCK_ID_BOOST_ACTIVATION.WriteBlock
        OpEventWriteBlock_WriteBlock_PS_NVP_BLOCK_ID_MEASUREMENT_FRAME_12_CONFIG: start-on-event=WriteBlock, operation=PS_NVP_BLOCK_ID_MEASUREMENT_FRAME_12_CONFIG.WriteBlock
        OpEventWriteBlock_WriteBlock_PS_NVP_BLOCK_ID_MEASUREMENT_FRAME_CONFIG: start-on-event=WriteBlock, operation=PS_NVP_BLOCK_ID_MEASUREMENT_FRAME_CONFIG.WriteBlock
        OpEventRestoreBlockDefaults_RestoreBlockDefaults_PS_Ssa_CodingNvM_Coding_CodingVIN: start-on-event=RestoreBlockDefaults, operation=PS_Ssa_CodingNvM_Coding_CodingVIN.RestoreBlockDefaults
        OpEventRestoreBlockDefaults_RestoreBlockDefaults_PS_Ssa_CodingNvM_Coding_CurrentVIN: start-on-event=RestoreBlockDefaults, operation=PS_Ssa_CodingNvM_Coding_CurrentVIN.RestoreBlockDefaults
        OpEventRestoreBlockDefaults_RestoreBlockDefaults_PS_Ssa_RightsM_NvM_RightsM_AclVersion: start-on-event=RestoreBlockDefaults, operation=PS_Ssa_RightsM_NvM_RightsM_AclVersion.RestoreBlockDefaults
        OpEventRestoreBlockDefaults_RestoreBlockDefaults_PS_Ssa_RightsM_NvM_RightsM_Nonce: start-on-event=RestoreBlockDefaults, operation=PS_Ssa_RightsM_NvM_RightsM_Nonce.RestoreBlockDefaults
        OpEventRestoreBlockDefaults_RestoreBlockDefaults_PS_Ssa_RightsM_NvM_RightsM_PostProductionStatus: start-on-event=RestoreBlockDefaults, operation=PS_Ssa_RightsM_NvM_RightsM_PostProductionStatus.RestoreBlockDefaults
        OpEventRestoreBlockDefaults_RestoreBlockDefaults_PS_Ssa_TimeM_NvM_TimeM_RealTimeOffset: start-on-event=RestoreBlockDefaults, operation=PS_Ssa_TimeM_NvM_TimeM_RealTimeOffset.RestoreBlockDefaults
        OpEventRestoreBlockDefaults_RestoreBlockDefaults_PS_Ssa_TimeM_NvM_TimeM_TickCount: start-on-event=RestoreBlockDefaults, operation=PS_Ssa_TimeM_NvM_TimeM_TickCount.RestoreBlockDefaults
        OpEventRestoreBlockDefaults_RestoreBlockDefaults_PS_NvMBlockDescriptor_FblMetaData: start-on-event=RestoreBlockDefaults, operation=PS_NvMBlockDescriptor_FblMetaData.RestoreBlockDefaults
        OpEventRestoreBlockDefaults_RestoreBlockDefaults_PS_NVP_BLOCK_ID_ECU_LOCATION: start-on-event=RestoreBlockDefaults, operation=PS_NVP_BLOCK_ID_ECU_LOCATION.RestoreBlockDefaults
        OpEventRestoreBlockDefaults_RestoreBlockDefaults_PS_NVP_BLOCK_ID_BELT_ASSEMBLY_MANUF_DATE_AND_SN: start-on-event=RestoreBlockDefaults, operation=PS_NVP_BLOCK_ID_BELT_ASSEMBLY_MANUF_DATE_AND_SN.RestoreBlockDefaults
        OpEventRestoreBlockDefaults_RestoreBlockDefaults_PS_NVP_BLOCK_ID_HB_CALIBRATION: start-on-event=RestoreBlockDefaults, operation=PS_NVP_BLOCK_ID_HB_CALIBRATION.RestoreBlockDefaults
        OpEventRestoreBlockDefaults_RestoreBlockDefaults_PS_NVP_BLOCK_ID_AEE_TRACEABILITY: start-on-event=RestoreBlockDefaults, operation=PS_NVP_BLOCK_ID_AEE_TRACEABILITY.RestoreBlockDefaults
        OpEventRestoreBlockDefaults_RestoreBlockDefaults_PS_NVP_BLOCK_ID_EXECUTION_COUNTERS: start-on-event=RestoreBlockDefaults, operation=PS_NVP_BLOCK_ID_EXECUTION_COUNTERS.RestoreBlockDefaults
        OpEventRestoreBlockDefaults_RestoreBlockDefaults_PS_NVP_BLOCK_ID_TESTS_PARAM: start-on-event=RestoreBlockDefaults, operation=PS_NVP_BLOCK_ID_TESTS_PARAM.RestoreBlockDefaults
        OpEventRestoreBlockDefaults_RestoreBlockDefaults_PS_NVP_BLOCK_ID_CYCLE: start-on-event=RestoreBlockDefaults, operation=PS_NVP_BLOCK_ID_CYCLE.RestoreBlockDefaults
        OpEventRestoreBlockDefaults_RestoreBlockDefaults_PS_NVP_BLOCK_ID_STEP: start-on-event=RestoreBlockDefaults, operation=PS_NVP_BLOCK_ID_STEP.RestoreBlockDefaults
        OpEventRestoreBlockDefaults_RestoreBlockDefaults_PS_CALIB_BLOCK_ID_EOL_PARAM: start-on-event=RestoreBlockDefaults, operation=PS_CALIB_BLOCK_ID_EOL_PARAM.RestoreBlockDefaults
        OpEventRestoreBlockDefaults_RestoreBlockDefaults_PS_CALIB_BLOCK_ID_BFS_PRIO_PARAM: start-on-event=RestoreBlockDefaults, operation=PS_CALIB_BLOCK_ID_BFS_PRIO_PARAM.RestoreBlockDefaults
        OpEventRestoreBlockDefaults_RestoreBlockDefaults_PS_CALIB_BLOCK_ID_PID_PARAM: start-on-event=RestoreBlockDefaults, operation=PS_CALIB_BLOCK_ID_PID_PARAM.RestoreBlockDefaults
        OpEventRestoreBlockDefaults_RestoreBlockDefaults_PS_CALIB_BLOCK_ID_WEIGHT_REL_TABLE: start-on-event=RestoreBlockDefaults, operation=PS_CALIB_BLOCK_ID_WEIGHT_REL_TABLE.RestoreBlockDefaults
        OpEventRestoreBlockDefaults_RestoreBlockDefaults_PS_CALIB_BLOCK_ID_WEIGHT_TENS{0..3}_TABLE: start-on-event=RestoreBlockDefaults, operation=PS_CALIB_BLOCK_ID_WEIGHT_TENS{0..3}_TABLE.RestoreBlockDefaults
        OpEventRestoreBlockDefaults_RestoreBlockDefaults_PS_CALIB_BLOCK_ID_INT_CURRENT_CORR: start-on-event=RestoreBlockDefaults, operation=PS_CALIB_BLOCK_ID_INT_CURRENT_CORR.RestoreBlockDefaults
        OpEventRestoreBlockDefaults_RestoreBlockDefaults_PS_CALIB_BLOCK_ID_INT_CURRENT_TABLE: start-on-event=RestoreBlockDefaults, operation=PS_CALIB_BLOCK_ID_INT_CURRENT_TABLE.RestoreBlockDefaults
        OpEventRestoreBlockDefaults_RestoreBlockDefaults_PS_CALIB_BLOCK_ID_ECPL_ALPHA_TABLE: start-on-event=RestoreBlockDefaults, operation=PS_CALIB_BLOCK_ID_ECPL_ALPHA_TABLE.RestoreBlockDefaults
        OpEventRestoreBlockDefaults_RestoreBlockDefaults_PS_CALIB_BLOCK_ID_POWER_DEGRADATION: start-on-event=RestoreBlockDefaults, operation=PS_CALIB_BLOCK_ID_POWER_DEGRADATION.RestoreBlockDefaults
        OpEventRestoreBlockDefaults_RestoreBlockDefaults_PS_CALIB_BLOCK_ID_ECPL_BETA_TABLE: start-on-event=RestoreBlockDefaults, operation=PS_CALIB_BLOCK_ID_ECPL_BETA_TABLE.RestoreBlockDefaults
        OpEventRestoreBlockDefaults_RestoreBlockDefaults_PS_CALIB_BLOCK_ID_ECPL_OTHER_PARAM: start-on-event=RestoreBlockDefaults, operation=PS_CALIB_BLOCK_ID_ECPL_OTHER_PARAM.RestoreBlockDefaults
        OpEventRestoreBlockDefaults_RestoreBlockDefaults_PS_CALIB_BLOCK_ID_BPA_MOTOR_CURRENT: start-on-event=RestoreBlockDefaults, operation=PS_CALIB_BLOCK_ID_BPA_MOTOR_CURRENT.RestoreBlockDefaults
        OpEventRestoreBlockDefaults_RestoreBlockDefaults_PS_CALIB_BLOCK_ID_VOLT_THRS: start-on-event=RestoreBlockDefaults, operation=PS_CALIB_BLOCK_ID_VOLT_THRS.RestoreBlockDefaults
        OpEventRestoreBlockDefaults_RestoreBlockDefaults_PS_CALIB_BLOCK_ID_BATTERY_LOSS_DETECTION_THRS: start-on-event=RestoreBlockDefaults, operation=PS_CALIB_BLOCK_ID_BATTERY_LOSS_DETECTION_THRS.RestoreBlockDefaults
        OpEventRestoreBlockDefaults_RestoreBlockDefaults_PS_CALIB_BLOCK_ID_BOOST: start-on-event=RestoreBlockDefaults, operation=PS_CALIB_BLOCK_ID_BOOST.RestoreBlockDefaults
        OpEventRestoreBlockDefaults_RestoreBlockDefaults_PS_CALIB_BLOCK_ID_ECU_PROPERTIES: start-on-event=RestoreBlockDefaults, operation=PS_CALIB_BLOCK_ID_ECU_PROPERTIES.RestoreBlockDefaults
        OpEventRestoreBlockDefaults_RestoreBlockDefaults_PS_CALIB_BLOCK_ID_SW_SELF_PROTECTION_THRS: start-on-event=RestoreBlockDefaults, operation=PS_CALIB_BLOCK_ID_SW_SELF_PROTECTION_THRS.RestoreBlockDefaults
        OpEventRestoreBlockDefaults_RestoreBlockDefaults_PS_CALIB_BLOCK_ID_MOTOR_RESIST_PARAM: start-on-event=RestoreBlockDefaults, operation=PS_CALIB_BLOCK_ID_MOTOR_RESIST_PARAM.RestoreBlockDefaults
        OpEventRestoreBlockDefaults_RestoreBlockDefaults_PS_CALIB_BLOCK_ID_BOOST_ACTIVATION: start-on-event=RestoreBlockDefaults, operation=PS_CALIB_BLOCK_ID_BOOST_ACTIVATION.RestoreBlockDefaults
        OpEventRestoreBlockDefaults_RestoreBlockDefaults_PS_NVP_BLOCK_ID_MEASUREMENT_FRAME_12_CONFIG: start-on-event=RestoreBlockDefaults, operation=PS_NVP_BLOCK_ID_MEASUREMENT_FRAME_12_CONFIG.RestoreBlockDefaults
        OpEventRestoreBlockDefaults_RestoreBlockDefaults_PS_NVP_BLOCK_ID_MEASUREMENT_FRAME_CONFIG: start-on-event=RestoreBlockDefaults, operation=PS_NVP_BLOCK_ID_MEASUREMENT_FRAME_CONFIG.RestoreBlockDefaults
        OpEventInvalidateNvBlock_InvalidateNvBlock_PS_Ssa_CodingNvM_Coding_CodingVIN: start-on-event=InvalidateNvBlock, operation=PS_Ssa_CodingNvM_Coding_CodingVIN.InvalidateNvBlock
        OpEventInvalidateNvBlock_InvalidateNvBlock_PS_Ssa_CodingNvM_Coding_CurrentVIN: start-on-event=InvalidateNvBlock, operation=PS_Ssa_CodingNvM_Coding_CurrentVIN.InvalidateNvBlock
        OpEventInvalidateNvBlock_InvalidateNvBlock_PS_Ssa_RightsM_NvM_RightsM_AclVersion: start-on-event=InvalidateNvBlock, operation=PS_Ssa_RightsM_NvM_RightsM_AclVersion.InvalidateNvBlock
        OpEventInvalidateNvBlock_InvalidateNvBlock_PS_Ssa_RightsM_NvM_RightsM_Nonce: start-on-event=InvalidateNvBlock, operation=PS_Ssa_RightsM_NvM_RightsM_Nonce.InvalidateNvBlock
        OpEventInvalidateNvBlock_InvalidateNvBlock_PS_Ssa_RightsM_NvM_RightsM_PostProductionStatus: start-on-event=InvalidateNvBlock, operation=PS_Ssa_RightsM_NvM_RightsM_PostProductionStatus.InvalidateNvBlock
        OpEventInvalidateNvBlock_InvalidateNvBlock_PS_Ssa_SecLogNvM_SecLog_LogDataEvnt10_FailedPduMacVerif: start-on-event=InvalidateNvBlock, operation=PS_Ssa_SecLogNvM_SecLog_LogDataEvnt10_FailedPduMacVerif.InvalidateNvBlock
        OpEventInvalidateNvBlock_InvalidateNvBlock_PS_Ssa_SecLogNvM_SecLog_LogDataEvnt11_SecOrAuthBoot: start-on-event=InvalidateNvBlock, operation=PS_Ssa_SecLogNvM_SecLog_LogDataEvnt11_SecOrAuthBoot.InvalidateNvBlock
        OpEventInvalidateNvBlock_InvalidateNvBlock_PS_Ssa_SecLogNvM_SecLog_LogDataEvnt12_ChangeOfVin: start-on-event=InvalidateNvBlock, operation=PS_Ssa_SecLogNvM_SecLog_LogDataEvnt12_ChangeOfVin.InvalidateNvBlock
        OpEventInvalidateNvBlock_InvalidateNvBlock_PS_Ssa_SecLogNvM_SecLog_LogDataEvnt13_AclReplacement: start-on-event=InvalidateNvBlock, operation=PS_Ssa_SecLogNvM_SecLog_LogDataEvnt13_AclReplacement.InvalidateNvBlock
        OpEventInvalidateNvBlock_InvalidateNvBlock_PS_Ssa_SecLogNvM_SecLog_LogDataEvnt1_FailedCertVerif: start-on-event=InvalidateNvBlock, operation=PS_Ssa_SecLogNvM_SecLog_LogDataEvnt1_FailedCertVerif.InvalidateNvBlock
        OpEventInvalidateNvBlock_InvalidateNvBlock_PS_Ssa_SecLogNvM_SecLog_LogDataEvnt2_SucCertVerif: start-on-event=InvalidateNvBlock, operation=PS_Ssa_SecLogNvM_SecLog_LogDataEvnt2_SucCertVerif.InvalidateNvBlock
        OpEventInvalidateNvBlock_InvalidateNvBlock_PS_Ssa_SecLogNvM_SecLog_LogDataEvnt3_SucAuthAndEnhanceRights: start-on-event=InvalidateNvBlock, operation=PS_Ssa_SecLogNvM_SecLog_LogDataEvnt3_SucAuthAndEnhanceRights.InvalidateNvBlock
        OpEventInvalidateNvBlock_InvalidateNvBlock_PS_Ssa_SecLogNvM_SecLog_LogDataEvnt4_AuthBySecAccess: start-on-event=InvalidateNvBlock, operation=PS_Ssa_SecLogNvM_SecLog_LogDataEvnt4_AuthBySecAccess.InvalidateNvBlock
        OpEventInvalidateNvBlock_InvalidateNvBlock_PS_Ssa_SecLogNvM_SecLog_LogDataEvnt5_SucDiagServiceExec: start-on-event=InvalidateNvBlock, operation=PS_Ssa_SecLogNvM_SecLog_LogDataEvnt5_SucDiagServiceExec.InvalidateNvBlock
        OpEventInvalidateNvBlock_InvalidateNvBlock_PS_Ssa_SecLogNvM_SecLog_LogDataEvnt6_RightsMgmt: start-on-event=InvalidateNvBlock, operation=PS_Ssa_SecLogNvM_SecLog_LogDataEvnt6_RightsMgmt.InvalidateNvBlock
        OpEventInvalidateNvBlock_InvalidateNvBlock_PS_Ssa_SecLogNvM_SecLog_LogDataEvnt7_SigVerif: start-on-event=InvalidateNvBlock, operation=PS_Ssa_SecLogNvM_SecLog_LogDataEvnt7_SigVerif.InvalidateNvBlock
        OpEventInvalidateNvBlock_InvalidateNvBlock_PS_Ssa_SecLogNvM_SecLog_LogDataEvnt8_TickCountDateAndTime: start-on-event=InvalidateNvBlock, operation=PS_Ssa_SecLogNvM_SecLog_LogDataEvnt8_TickCountDateAndTime.InvalidateNvBlock
        OpEventInvalidateNvBlock_InvalidateNvBlock_PS_Ssa_SecLogNvM_SecLog_LogDataEvnt9_SecOcMisconfig: start-on-event=InvalidateNvBlock, operation=PS_Ssa_SecLogNvM_SecLog_LogDataEvnt9_SecOcMisconfig.InvalidateNvBlock
        OpEventInvalidateNvBlock_InvalidateNvBlock_PS_Ssa_SecLogNvM_SecLog_LogFailedMacVerifCount_ExceededTh{1..3}: start-on-event=InvalidateNvBlock, operation=PS_Ssa_SecLogNvM_SecLog_LogFailedMacVerifCount_ExceededTh{1..3}.InvalidateNvBlock
        OpEventInvalidateNvBlock_InvalidateNvBlock_PS_Ssa_TimeM_NvM_TimeM_RealTimeOffset: start-on-event=InvalidateNvBlock, operation=PS_Ssa_TimeM_NvM_TimeM_RealTimeOffset.InvalidateNvBlock
        OpEventInvalidateNvBlock_InvalidateNvBlock_PS_Ssa_TimeM_NvM_TimeM_TickCount: start-on-event=InvalidateNvBlock, operation=PS_Ssa_TimeM_NvM_TimeM_TickCount.InvalidateNvBlock
        OpEventInvalidateNvBlock_InvalidateNvBlock_PS_Ct_MBBL_SsaAppl_CodingNvmCoding_CurrentVehicleEquipment: start-on-event=InvalidateNvBlock, operation=PS_Ct_MBBL_SsaAppl_CodingNvmCoding_CurrentVehicleEquipment.InvalidateNvBlock
        OpEventInvalidateNvBlock_InvalidateNvBlock_PS_Ct_MBBL_SsaAppl_CodingNvmCoding_TensioningCycleBSR: start-on-event=InvalidateNvBlock, operation=PS_Ct_MBBL_SsaAppl_CodingNvmCoding_TensioningCycleBSR.InvalidateNvBlock
        OpEventInvalidateNvBlock_InvalidateNvBlock_PS_Ct_MBBL_SsaAppl_CodingNvmCoding_PreSafeCyclesLevel: start-on-event=InvalidateNvBlock, operation=PS_Ct_MBBL_SsaAppl_CodingNvmCoding_PreSafeCyclesLevel.InvalidateNvBlock
        OpEventInvalidateNvBlock_InvalidateNvBlock_PS_Ct_MBBL_SsaAppl_CodingNvmCoding_ReleaseCyclesBsrAndPreSafe: start-on-event=InvalidateNvBlock, operation=PS_Ct_MBBL_SsaAppl_CodingNvmCoding_ReleaseCyclesBsrAndPreSafe.InvalidateNvBlock
        OpEventInvalidateNvBlock_InvalidateNvBlock_PS_Ct_MBBL_SsaAppl_CodingNvmCoding_ZZZVehicleEquipmentDevelopment: start-on-event=InvalidateNvBlock, operation=PS_Ct_MBBL_SsaAppl_CodingNvmCoding_ZZZVehicleEquipmentDevelopment.InvalidateNvBlock
        OpEventInvalidateNvBlock_InvalidateNvBlock_PS_Ct_MBBL_SsaAppl_CodingNvmCoding_CalibrationID: start-on-event=InvalidateNvBlock, operation=PS_Ct_MBBL_SsaAppl_CodingNvmCoding_CalibrationID.InvalidateNvBlock
        OpEventInvalidateNvBlock_InvalidateNvBlock_PS_NvMBlockDescriptor_FblMetaData: start-on-event=InvalidateNvBlock, operation=PS_NvMBlockDescriptor_FblMetaData.InvalidateNvBlock
        OpEventInvalidateNvBlock_InvalidateNvBlock_PS_NVP_BLOCK_ID_ECU_LOCATION: start-on-event=InvalidateNvBlock, operation=PS_NVP_BLOCK_ID_ECU_LOCATION.InvalidateNvBlock
        OpEventInvalidateNvBlock_InvalidateNvBlock_PS_NVP_BLOCK_ID_BELT_ASSEMBLY_MANUF_DATE_AND_SN: start-on-event=InvalidateNvBlock, operation=PS_NVP_BLOCK_ID_BELT_ASSEMBLY_MANUF_DATE_AND_SN.InvalidateNvBlock
        OpEventInvalidateNvBlock_InvalidateNvBlock_PS_NVP_BLOCK_ID_HB_CALIBRATION: start-on-event=InvalidateNvBlock, operation=PS_NVP_BLOCK_ID_HB_CALIBRATION.InvalidateNvBlock
        OpEventInvalidateNvBlock_InvalidateNvBlock_PS_NVP_BLOCK_ID_AEE_TRACEABILITY: start-on-event=InvalidateNvBlock, operation=PS_NVP_BLOCK_ID_AEE_TRACEABILITY.InvalidateNvBlock
        OpEventInvalidateNvBlock_InvalidateNvBlock_PS_NVP_BLOCK_ID_EXECUTION_COUNTERS: start-on-event=InvalidateNvBlock, operation=PS_NVP_BLOCK_ID_EXECUTION_COUNTERS.InvalidateNvBlock
        OpEventInvalidateNvBlock_InvalidateNvBlock_PS_NVP_BLOCK_ID_TESTS_PARAM: start-on-event=InvalidateNvBlock, operation=PS_NVP_BLOCK_ID_TESTS_PARAM.InvalidateNvBlock
        OpEventInvalidateNvBlock_InvalidateNvBlock_PS_NVP_BLOCK_ID_CYCLE: start-on-event=InvalidateNvBlock, operation=PS_NVP_BLOCK_ID_CYCLE.InvalidateNvBlock
        OpEventInvalidateNvBlock_InvalidateNvBlock_PS_NVP_BLOCK_ID_STEP: start-on-event=InvalidateNvBlock, operation=PS_NVP_BLOCK_ID_STEP.InvalidateNvBlock
        OpEventInvalidateNvBlock_InvalidateNvBlock_PS_CALIB_BLOCK_ID_EOL_PARAM: start-on-event=InvalidateNvBlock, operation=PS_CALIB_BLOCK_ID_EOL_PARAM.InvalidateNvBlock
        OpEventInvalidateNvBlock_InvalidateNvBlock_PS_CALIB_BLOCK_ID_BFS_PRIO_PARAM: start-on-event=InvalidateNvBlock, operation=PS_CALIB_BLOCK_ID_BFS_PRIO_PARAM.InvalidateNvBlock
        OpEventInvalidateNvBlock_InvalidateNvBlock_PS_CALIB_BLOCK_ID_PID_PARAM: start-on-event=InvalidateNvBlock, operation=PS_CALIB_BLOCK_ID_PID_PARAM.InvalidateNvBlock
        OpEventInvalidateNvBlock_InvalidateNvBlock_PS_CALIB_BLOCK_ID_WEIGHT_REL_TABLE: start-on-event=InvalidateNvBlock, operation=PS_CALIB_BLOCK_ID_WEIGHT_REL_TABLE.InvalidateNvBlock
        OpEventInvalidateNvBlock_InvalidateNvBlock_PS_CALIB_BLOCK_ID_WEIGHT_TENS{0..3}_TABLE: start-on-event=InvalidateNvBlock, operation=PS_CALIB_BLOCK_ID_WEIGHT_TENS{0..3}_TABLE.InvalidateNvBlock
        OpEventInvalidateNvBlock_InvalidateNvBlock_PS_CALIB_BLOCK_ID_INT_CURRENT_CORR: start-on-event=InvalidateNvBlock, operation=PS_CALIB_BLOCK_ID_INT_CURRENT_CORR.InvalidateNvBlock
        OpEventInvalidateNvBlock_InvalidateNvBlock_PS_CALIB_BLOCK_ID_INT_CURRENT_TABLE: start-on-event=InvalidateNvBlock, operation=PS_CALIB_BLOCK_ID_INT_CURRENT_TABLE.InvalidateNvBlock
        OpEventInvalidateNvBlock_InvalidateNvBlock_PS_CALIB_BLOCK_ID_ECPL_ALPHA_TABLE: start-on-event=InvalidateNvBlock, operation=PS_CALIB_BLOCK_ID_ECPL_ALPHA_TABLE.InvalidateNvBlock
        OpEventInvalidateNvBlock_InvalidateNvBlock_PS_CALIB_BLOCK_ID_POWER_DEGRADATION: start-on-event=InvalidateNvBlock, operation=PS_CALIB_BLOCK_ID_POWER_DEGRADATION.InvalidateNvBlock
        OpEventInvalidateNvBlock_InvalidateNvBlock_PS_CALIB_BLOCK_ID_ECPL_BETA_TABLE: start-on-event=InvalidateNvBlock, operation=PS_CALIB_BLOCK_ID_ECPL_BETA_TABLE.InvalidateNvBlock
        OpEventInvalidateNvBlock_InvalidateNvBlock_PS_CALIB_BLOCK_ID_ECPL_OTHER_PARAM: start-on-event=InvalidateNvBlock, operation=PS_CALIB_BLOCK_ID_ECPL_OTHER_PARAM.InvalidateNvBlock
        OpEventInvalidateNvBlock_InvalidateNvBlock_PS_CALIB_BLOCK_ID_BPA_MOTOR_CURRENT: start-on-event=InvalidateNvBlock, operation=PS_CALIB_BLOCK_ID_BPA_MOTOR_CURRENT.InvalidateNvBlock
        OpEventInvalidateNvBlock_InvalidateNvBlock_PS_CALIB_BLOCK_ID_VOLT_THRS: start-on-event=InvalidateNvBlock, operation=PS_CALIB_BLOCK_ID_VOLT_THRS.InvalidateNvBlock
        OpEventInvalidateNvBlock_InvalidateNvBlock_PS_CALIB_BLOCK_ID_BATTERY_LOSS_DETECTION_THRS: start-on-event=InvalidateNvBlock, operation=PS_CALIB_BLOCK_ID_BATTERY_LOSS_DETECTION_THRS.InvalidateNvBlock
        OpEventInvalidateNvBlock_InvalidateNvBlock_PS_CALIB_BLOCK_ID_BOOST: start-on-event=InvalidateNvBlock, operation=PS_CALIB_BLOCK_ID_BOOST.InvalidateNvBlock
        OpEventInvalidateNvBlock_InvalidateNvBlock_PS_CALIB_BLOCK_ID_ECU_PROPERTIES: start-on-event=InvalidateNvBlock, operation=PS_CALIB_BLOCK_ID_ECU_PROPERTIES.InvalidateNvBlock
        OpEventInvalidateNvBlock_InvalidateNvBlock_PS_CALIB_BLOCK_ID_SW_SELF_PROTECTION_THRS: start-on-event=InvalidateNvBlock, operation=PS_CALIB_BLOCK_ID_SW_SELF_PROTECTION_THRS.InvalidateNvBlock
        OpEventInvalidateNvBlock_InvalidateNvBlock_PS_CALIB_BLOCK_ID_MOTOR_RESIST_PARAM: start-on-event=InvalidateNvBlock, operation=PS_CALIB_BLOCK_ID_MOTOR_RESIST_PARAM.InvalidateNvBlock
        OpEventInvalidateNvBlock_InvalidateNvBlock_PS_CALIB_BLOCK_ID_BOOST_ACTIVATION: start-on-event=InvalidateNvBlock, operation=PS_CALIB_BLOCK_ID_BOOST_ACTIVATION.InvalidateNvBlock
        OpEventInvalidateNvBlock_InvalidateNvBlock_PS_NVP_BLOCK_ID_MEASUREMENT_FRAME_12_CONFIG: start-on-event=InvalidateNvBlock, operation=PS_NVP_BLOCK_ID_MEASUREMENT_FRAME_12_CONFIG.InvalidateNvBlock
        OpEventInvalidateNvBlock_InvalidateNvBlock_PS_NVP_BLOCK_ID_MEASUREMENT_FRAME_CONFIG: start-on-event=InvalidateNvBlock, operation=PS_NVP_BLOCK_ID_MEASUREMENT_FRAME_CONFIG.InvalidateNvBlock
        OpEventEraseBlock_EraseBlock_PS_Ssa_CodingNvM_Coding_CodingVIN: start-on-event=EraseBlock, operation=PS_Ssa_CodingNvM_Coding_CodingVIN.EraseBlock
        OpEventEraseBlock_EraseBlock_PS_Ssa_CodingNvM_Coding_CurrentVIN: start-on-event=EraseBlock, operation=PS_Ssa_CodingNvM_Coding_CurrentVIN.EraseBlock
        OpEventEraseBlock_EraseBlock_PS_Ssa_RightsM_NvM_RightsM_AclVersion: start-on-event=EraseBlock, operation=PS_Ssa_RightsM_NvM_RightsM_AclVersion.EraseBlock
        OpEventEraseBlock_EraseBlock_PS_Ssa_RightsM_NvM_RightsM_Nonce: start-on-event=EraseBlock, operation=PS_Ssa_RightsM_NvM_RightsM_Nonce.EraseBlock
        OpEventEraseBlock_EraseBlock_PS_Ssa_RightsM_NvM_RightsM_PostProductionStatus: start-on-event=EraseBlock, operation=PS_Ssa_RightsM_NvM_RightsM_PostProductionStatus.EraseBlock
        OpEventEraseBlock_EraseBlock_PS_Ssa_SecLogNvM_SecLog_LogDataEvnt10_FailedPduMacVerif: start-on-event=EraseBlock, operation=PS_Ssa_SecLogNvM_SecLog_LogDataEvnt10_FailedPduMacVerif.EraseBlock
        OpEventEraseBlock_EraseBlock_PS_Ssa_SecLogNvM_SecLog_LogDataEvnt11_SecOrAuthBoot: start-on-event=EraseBlock, operation=PS_Ssa_SecLogNvM_SecLog_LogDataEvnt11_SecOrAuthBoot.EraseBlock
        OpEventEraseBlock_EraseBlock_PS_Ssa_SecLogNvM_SecLog_LogDataEvnt12_ChangeOfVin: start-on-event=EraseBlock, operation=PS_Ssa_SecLogNvM_SecLog_LogDataEvnt12_ChangeOfVin.EraseBlock
        OpEventEraseBlock_EraseBlock_PS_Ssa_SecLogNvM_SecLog_LogDataEvnt13_AclReplacement: start-on-event=EraseBlock, operation=PS_Ssa_SecLogNvM_SecLog_LogDataEvnt13_AclReplacement.EraseBlock
        OpEventEraseBlock_EraseBlock_PS_Ssa_SecLogNvM_SecLog_LogDataEvnt1_FailedCertVerif: start-on-event=EraseBlock, operation=PS_Ssa_SecLogNvM_SecLog_LogDataEvnt1_FailedCertVerif.EraseBlock
        OpEventEraseBlock_EraseBlock_PS_Ssa_SecLogNvM_SecLog_LogDataEvnt2_SucCertVerif: start-on-event=EraseBlock, operation=PS_Ssa_SecLogNvM_SecLog_LogDataEvnt2_SucCertVerif.EraseBlock
        OpEventEraseBlock_EraseBlock_PS_Ssa_SecLogNvM_SecLog_LogDataEvnt3_SucAuthAndEnhanceRights: start-on-event=EraseBlock, operation=PS_Ssa_SecLogNvM_SecLog_LogDataEvnt3_SucAuthAndEnhanceRights.EraseBlock
        OpEventEraseBlock_EraseBlock_PS_Ssa_SecLogNvM_SecLog_LogDataEvnt4_AuthBySecAccess: start-on-event=EraseBlock, operation=PS_Ssa_SecLogNvM_SecLog_LogDataEvnt4_AuthBySecAccess.EraseBlock
        OpEventEraseBlock_EraseBlock_PS_Ssa_SecLogNvM_SecLog_LogDataEvnt5_SucDiagServiceExec: start-on-event=EraseBlock, operation=PS_Ssa_SecLogNvM_SecLog_LogDataEvnt5_SucDiagServiceExec.EraseBlock
        OpEventEraseBlock_EraseBlock_PS_Ssa_SecLogNvM_SecLog_LogDataEvnt6_RightsMgmt: start-on-event=EraseBlock, operation=PS_Ssa_SecLogNvM_SecLog_LogDataEvnt6_RightsMgmt.EraseBlock
        OpEventEraseBlock_EraseBlock_PS_Ssa_SecLogNvM_SecLog_LogDataEvnt7_SigVerif: start-on-event=EraseBlock, operation=PS_Ssa_SecLogNvM_SecLog_LogDataEvnt7_SigVerif.EraseBlock
        OpEventEraseBlock_EraseBlock_PS_Ssa_SecLogNvM_SecLog_LogDataEvnt8_TickCountDateAndTime: start-on-event=EraseBlock, operation=PS_Ssa_SecLogNvM_SecLog_LogDataEvnt8_TickCountDateAndTime.EraseBlock
        OpEventEraseBlock_EraseBlock_PS_Ssa_SecLogNvM_SecLog_LogDataEvnt9_SecOcMisconfig: start-on-event=EraseBlock, operation=PS_Ssa_SecLogNvM_SecLog_LogDataEvnt9_SecOcMisconfig.EraseBlock
        OpEventEraseBlock_EraseBlock_PS_Ssa_SecLogNvM_SecLog_LogFailedMacVerifCount_ExceededTh{1..3}: start-on-event=EraseBlock, operation=PS_Ssa_SecLogNvM_SecLog_LogFailedMacVerifCount_ExceededTh{1..3}.EraseBlock
        OpEventEraseBlock_EraseBlock_PS_Ssa_TimeM_NvM_TimeM_RealTimeOffset: start-on-event=EraseBlock, operation=PS_Ssa_TimeM_NvM_TimeM_RealTimeOffset.EraseBlock
        OpEventEraseBlock_EraseBlock_PS_Ssa_TimeM_NvM_TimeM_TickCount: start-on-event=EraseBlock, operation=PS_Ssa_TimeM_NvM_TimeM_TickCount.EraseBlock
        OpEventEraseBlock_EraseBlock_PS_Ct_MBBL_SsaAppl_CodingNvmCoding_CurrentVehicleEquipment: start-on-event=EraseBlock, operation=PS_Ct_MBBL_SsaAppl_CodingNvmCoding_CurrentVehicleEquipment.EraseBlock
        OpEventEraseBlock_EraseBlock_PS_Ct_MBBL_SsaAppl_CodingNvmCoding_TensioningCycleBSR: start-on-event=EraseBlock, operation=PS_Ct_MBBL_SsaAppl_CodingNvmCoding_TensioningCycleBSR.EraseBlock
        OpEventEraseBlock_EraseBlock_PS_Ct_MBBL_SsaAppl_CodingNvmCoding_PreSafeCyclesLevel: start-on-event=EraseBlock, operation=PS_Ct_MBBL_SsaAppl_CodingNvmCoding_PreSafeCyclesLevel.EraseBlock
        OpEventEraseBlock_EraseBlock_PS_Ct_MBBL_SsaAppl_CodingNvmCoding_ReleaseCyclesBsrAndPreSafe: start-on-event=EraseBlock, operation=PS_Ct_MBBL_SsaAppl_CodingNvmCoding_ReleaseCyclesBsrAndPreSafe.EraseBlock
        OpEventEraseBlock_EraseBlock_PS_Ct_MBBL_SsaAppl_CodingNvmCoding_ZZZVehicleEquipmentDevelopment: start-on-event=EraseBlock, operation=PS_Ct_MBBL_SsaAppl_CodingNvmCoding_ZZZVehicleEquipmentDevelopment.EraseBlock
        OpEventEraseBlock_EraseBlock_PS_Ct_MBBL_SsaAppl_CodingNvmCoding_CalibrationID: start-on-event=EraseBlock, operation=PS_Ct_MBBL_SsaAppl_CodingNvmCoding_CalibrationID.EraseBlock
        OpEventEraseBlock_EraseBlock_PS_NvMBlockDescriptor_FblMetaData: start-on-event=EraseBlock, operation=PS_NvMBlockDescriptor_FblMetaData.EraseBlock
        OpEventEraseBlock_EraseBlock_PS_NVP_BLOCK_ID_ECU_LOCATION: start-on-event=EraseBlock, operation=PS_NVP_BLOCK_ID_ECU_LOCATION.EraseBlock
        OpEventEraseBlock_EraseBlock_PS_NVP_BLOCK_ID_BELT_ASSEMBLY_MANUF_DATE_AND_SN: start-on-event=EraseBlock, operation=PS_NVP_BLOCK_ID_BELT_ASSEMBLY_MANUF_DATE_AND_SN.EraseBlock
        OpEventEraseBlock_EraseBlock_PS_NVP_BLOCK_ID_HB_CALIBRATION: start-on-event=EraseBlock, operation=PS_NVP_BLOCK_ID_HB_CALIBRATION.EraseBlock
        OpEventEraseBlock_EraseBlock_PS_NVP_BLOCK_ID_AEE_TRACEABILITY: start-on-event=EraseBlock, operation=PS_NVP_BLOCK_ID_AEE_TRACEABILITY.EraseBlock
        OpEventEraseBlock_EraseBlock_PS_NVP_BLOCK_ID_EXECUTION_COUNTERS: start-on-event=EraseBlock, operation=PS_NVP_BLOCK_ID_EXECUTION_COUNTERS.EraseBlock
        OpEventEraseBlock_EraseBlock_PS_NVP_BLOCK_ID_TESTS_PARAM: start-on-event=EraseBlock, operation=PS_NVP_BLOCK_ID_TESTS_PARAM.EraseBlock
        OpEventEraseBlock_EraseBlock_PS_NVP_BLOCK_ID_CYCLE: start-on-event=EraseBlock, operation=PS_NVP_BLOCK_ID_CYCLE.EraseBlock
        OpEventEraseBlock_EraseBlock_PS_NVP_BLOCK_ID_STEP: start-on-event=EraseBlock, operation=PS_NVP_BLOCK_ID_STEP.EraseBlock
        OpEventEraseBlock_EraseBlock_PS_CALIB_BLOCK_ID_EOL_PARAM: start-on-event=EraseBlock, operation=PS_CALIB_BLOCK_ID_EOL_PARAM.EraseBlock
        OpEventEraseBlock_EraseBlock_PS_CALIB_BLOCK_ID_BFS_PRIO_PARAM: start-on-event=EraseBlock, operation=PS_CALIB_BLOCK_ID_BFS_PRIO_PARAM.EraseBlock
        OpEventEraseBlock_EraseBlock_PS_CALIB_BLOCK_ID_PID_PARAM: start-on-event=EraseBlock, operation=PS_CALIB_BLOCK_ID_PID_PARAM.EraseBlock
        OpEventEraseBlock_EraseBlock_PS_CALIB_BLOCK_ID_WEIGHT_REL_TABLE: start-on-event=EraseBlock, operation=PS_CALIB_BLOCK_ID_WEIGHT_REL_TABLE.EraseBlock
        OpEventEraseBlock_EraseBlock_PS_CALIB_BLOCK_ID_WEIGHT_TENS{0..3}_TABLE: start-on-event=EraseBlock, operation=PS_CALIB_BLOCK_ID_WEIGHT_TENS{0..3}_TABLE.EraseBlock
        OpEventEraseBlock_EraseBlock_PS_CALIB_BLOCK_ID_INT_CURRENT_CORR: start-on-event=EraseBlock, operation=PS_CALIB_BLOCK_ID_INT_CURRENT_CORR.EraseBlock
        OpEventEraseBlock_EraseBlock_PS_CALIB_BLOCK_ID_INT_CURRENT_TABLE: start-on-event=EraseBlock, operation=PS_CALIB_BLOCK_ID_INT_CURRENT_TABLE.EraseBlock
        OpEventEraseBlock_EraseBlock_PS_CALIB_BLOCK_ID_ECPL_ALPHA_TABLE: start-on-event=EraseBlock, operation=PS_CALIB_BLOCK_ID_ECPL_ALPHA_TABLE.EraseBlock
        OpEventEraseBlock_EraseBlock_PS_CALIB_BLOCK_ID_POWER_DEGRADATION: start-on-event=EraseBlock, operation=PS_CALIB_BLOCK_ID_POWER_DEGRADATION.EraseBlock
        OpEventEraseBlock_EraseBlock_PS_CALIB_BLOCK_ID_ECPL_BETA_TABLE: start-on-event=EraseBlock, operation=PS_CALIB_BLOCK_ID_ECPL_BETA_TABLE.EraseBlock
        OpEventEraseBlock_EraseBlock_PS_CALIB_BLOCK_ID_ECPL_OTHER_PARAM: start-on-event=EraseBlock, operation=PS_CALIB_BLOCK_ID_ECPL_OTHER_PARAM.EraseBlock
        OpEventEraseBlock_EraseBlock_PS_CALIB_BLOCK_ID_BPA_MOTOR_CURRENT: start-on-event=EraseBlock, operation=PS_CALIB_BLOCK_ID_BPA_MOTOR_CURRENT.EraseBlock
        OpEventEraseBlock_EraseBlock_PS_CALIB_BLOCK_ID_VOLT_THRS: start-on-event=EraseBlock, operation=PS_CALIB_BLOCK_ID_VOLT_THRS.EraseBlock
        OpEventEraseBlock_EraseBlock_PS_CALIB_BLOCK_ID_BATTERY_LOSS_DETECTION_THRS: start-on-event=EraseBlock, operation=PS_CALIB_BLOCK_ID_BATTERY_LOSS_DETECTION_THRS.EraseBlock
        OpEventEraseBlock_EraseBlock_PS_CALIB_BLOCK_ID_BOOST: start-on-event=EraseBlock, operation=PS_CALIB_BLOCK_ID_BOOST.EraseBlock
        OpEventEraseBlock_EraseBlock_PS_CALIB_BLOCK_ID_ECU_PROPERTIES: start-on-event=EraseBlock, operation=PS_CALIB_BLOCK_ID_ECU_PROPERTIES.EraseBlock
        OpEventEraseBlock_EraseBlock_PS_CALIB_BLOCK_ID_SW_SELF_PROTECTION_THRS: start-on-event=EraseBlock, operation=PS_CALIB_BLOCK_ID_SW_SELF_PROTECTION_THRS.EraseBlock
        OpEventEraseBlock_EraseBlock_PS_CALIB_BLOCK_ID_MOTOR_RESIST_PARAM: start-on-event=EraseBlock, operation=PS_CALIB_BLOCK_ID_MOTOR_RESIST_PARAM.EraseBlock
        OpEventEraseBlock_EraseBlock_PS_CALIB_BLOCK_ID_BOOST_ACTIVATION: start-on-event=EraseBlock, operation=PS_CALIB_BLOCK_ID_BOOST_ACTIVATION.EraseBlock
        OpEventEraseBlock_EraseBlock_PS_NVP_BLOCK_ID_MEASUREMENT_FRAME_12_CONFIG: start-on-event=EraseBlock, operation=PS_NVP_BLOCK_ID_MEASUREMENT_FRAME_12_CONFIG.EraseBlock
        OpEventEraseBlock_EraseBlock_PS_NVP_BLOCK_ID_MEASUREMENT_FRAME_CONFIG: start-on-event=EraseBlock, operation=PS_NVP_BLOCK_ID_MEASUREMENT_FRAME_CONFIG.EraseBlock
        OpEventSetBlockProtection_SetBlockProtection_PAdmin_Ssa_CodingNvM_Coding_CodingVIN: start-on-event=SetBlockProtection, operation=PAdmin_Ssa_CodingNvM_Coding_CodingVIN.SetBlockProtection
        OpEventSetBlockProtection_SetBlockProtection_PAdmin_Ssa_CodingNvM_Coding_CurrentVIN: start-on-event=SetBlockProtection, operation=PAdmin_Ssa_CodingNvM_Coding_CurrentVIN.SetBlockProtection
        OpEventSetBlockProtection_SetBlockProtection_PAdmin_Ssa_RightsM_NvM_RightsM_AclVersion: start-on-event=SetBlockProtection, operation=PAdmin_Ssa_RightsM_NvM_RightsM_AclVersion.SetBlockProtection
        OpEventSetBlockProtection_SetBlockProtection_PAdmin_Ssa_RightsM_NvM_RightsM_Nonce: start-on-event=SetBlockProtection, operation=PAdmin_Ssa_RightsM_NvM_RightsM_Nonce.SetBlockProtection
        OpEventSetBlockProtection_SetBlockProtection_PAdmin_Ssa_RightsM_NvM_RightsM_PostProductionStatus: start-on-event=SetBlockProtection, operation=PAdmin_Ssa_RightsM_NvM_RightsM_PostProductionStatus.SetBlockProtection
        OpEventSetBlockProtection_SetBlockProtection_PAdmin_Ssa_SecLogNvM_SecLog_LogDataEvnt10_FailedPduMacVerif: start-on-event=SetBlockProtection, operation=PAdmin_Ssa_SecLogNvM_SecLog_LogDataEvnt10_FailedPduMacVerif.SetBlockProtection
        OpEventSetBlockProtection_SetBlockProtection_PAdmin_Ssa_SecLogNvM_SecLog_LogDataEvnt11_SecOrAuthBoot: start-on-event=SetBlockProtection, operation=PAdmin_Ssa_SecLogNvM_SecLog_LogDataEvnt11_SecOrAuthBoot.SetBlockProtection
        OpEventSetBlockProtection_SetBlockProtection_PAdmin_Ssa_SecLogNvM_SecLog_LogDataEvnt12_ChangeOfVin: start-on-event=SetBlockProtection, operation=PAdmin_Ssa_SecLogNvM_SecLog_LogDataEvnt12_ChangeOfVin.SetBlockProtection
        OpEventSetBlockProtection_SetBlockProtection_PAdmin_Ssa_SecLogNvM_SecLog_LogDataEvnt13_AclReplacement: start-on-event=SetBlockProtection, operation=PAdmin_Ssa_SecLogNvM_SecLog_LogDataEvnt13_AclReplacement.SetBlockProtection
        OpEventSetBlockProtection_SetBlockProtection_PAdmin_Ssa_SecLogNvM_SecLog_LogDataEvnt1_FailedCertVerif: start-on-event=SetBlockProtection, operation=PAdmin_Ssa_SecLogNvM_SecLog_LogDataEvnt1_FailedCertVerif.SetBlockProtection
        OpEventSetBlockProtection_SetBlockProtection_PAdmin_Ssa_SecLogNvM_SecLog_LogDataEvnt2_SucCertVerif: start-on-event=SetBlockProtection, operation=PAdmin_Ssa_SecLogNvM_SecLog_LogDataEvnt2_SucCertVerif.SetBlockProtection
        OpEventSetBlockProtection_SetBlockProtection_PAdmin_Ssa_SecLogNvM_SecLog_LogDataEvnt3_SucAuthAndEnhanceRights: start-on-event=SetBlockProtection, operation=PAdmin_Ssa_SecLogNvM_SecLog_LogDataEvnt3_SucAuthAndEnhanceRights.SetBlockProtection
        OpEventSetBlockProtection_SetBlockProtection_PAdmin_Ssa_SecLogNvM_SecLog_LogDataEvnt4_AuthBySecAccess: start-on-event=SetBlockProtection, operation=PAdmin_Ssa_SecLogNvM_SecLog_LogDataEvnt4_AuthBySecAccess.SetBlockProtection
        OpEventSetBlockProtection_SetBlockProtection_PAdmin_Ssa_SecLogNvM_SecLog_LogDataEvnt5_SucDiagServiceExec: start-on-event=SetBlockProtection, operation=PAdmin_Ssa_SecLogNvM_SecLog_LogDataEvnt5_SucDiagServiceExec.SetBlockProtection
        OpEventSetBlockProtection_SetBlockProtection_PAdmin_Ssa_SecLogNvM_SecLog_LogDataEvnt6_RightsMgmt: start-on-event=SetBlockProtection, operation=PAdmin_Ssa_SecLogNvM_SecLog_LogDataEvnt6_RightsMgmt.SetBlockProtection
        OpEventSetBlockProtection_SetBlockProtection_PAdmin_Ssa_SecLogNvM_SecLog_LogDataEvnt7_SigVerif: start-on-event=SetBlockProtection, operation=PAdmin_Ssa_SecLogNvM_SecLog_LogDataEvnt7_SigVerif.SetBlockProtection
        OpEventSetBlockProtection_SetBlockProtection_PAdmin_Ssa_SecLogNvM_SecLog_LogDataEvnt8_TickCountDateAndTime: start-on-event=SetBlockProtection, operation=PAdmin_Ssa_SecLogNvM_SecLog_LogDataEvnt8_TickCountDateAndTime.SetBlockProtection
        OpEventSetBlockProtection_SetBlockProtection_PAdmin_Ssa_SecLogNvM_SecLog_LogDataEvnt9_SecOcMisconfig: start-on-event=SetBlockProtection, operation=PAdmin_Ssa_SecLogNvM_SecLog_LogDataEvnt9_SecOcMisconfig.SetBlockProtection
        OpEventSetBlockProtection_SetBlockProtection_PAdmin_Ssa_SecLogNvM_SecLog_LogFailedMacVerifCount_ExceededTh{1..3}: start-on-event=SetBlockProtection, operation=PAdmin_Ssa_SecLogNvM_SecLog_LogFailedMacVerifCount_ExceededTh{1..3}.SetBlockProtection
        OpEventSetBlockProtection_SetBlockProtection_PAdmin_Ssa_TimeM_NvM_TimeM_RealTimeOffset: start-on-event=SetBlockProtection, operation=PAdmin_Ssa_TimeM_NvM_TimeM_RealTimeOffset.SetBlockProtection
        OpEventSetBlockProtection_SetBlockProtection_PAdmin_Ssa_TimeM_NvM_TimeM_TickCount: start-on-event=SetBlockProtection, operation=PAdmin_Ssa_TimeM_NvM_TimeM_TickCount.SetBlockProtection
        OpEventSetBlockProtection_SetBlockProtection_PAdmin_Ct_MBBL_SsaAppl_CodingNvmCoding_CurrentVehicleEquipment: start-on-event=SetBlockProtection, operation=PAdmin_Ct_MBBL_SsaAppl_CodingNvmCoding_CurrentVehicleEquipment.SetBlockProtection
        OpEventSetBlockProtection_SetBlockProtection_PAdmin_Ct_MBBL_SsaAppl_CodingNvmCoding_TensioningCycleBSR: start-on-event=SetBlockProtection, operation=PAdmin_Ct_MBBL_SsaAppl_CodingNvmCoding_TensioningCycleBSR.SetBlockProtection
        OpEventSetBlockProtection_SetBlockProtection_PAdmin_Ct_MBBL_SsaAppl_CodingNvmCoding_PreSafeCyclesLevel: start-on-event=SetBlockProtection, operation=PAdmin_Ct_MBBL_SsaAppl_CodingNvmCoding_PreSafeCyclesLevel.SetBlockProtection
        OpEventSetBlockProtection_SetBlockProtection_PAdmin_Ct_MBBL_SsaAppl_CodingNvmCoding_ReleaseCyclesBsrAndPreSafe: start-on-event=SetBlockProtection, operation=PAdmin_Ct_MBBL_SsaAppl_CodingNvmCoding_ReleaseCyclesBsrAndPreSafe.SetBlockProtection
        OpEventSetBlockProtection_SetBlockProtection_PAdmin_Ct_MBBL_SsaAppl_CodingNvmCoding_ZZZVehicleEquipmentDevelopment: start-on-event=SetBlockProtection, operation=PAdmin_Ct_MBBL_SsaAppl_CodingNvmCoding_ZZZVehicleEquipmentDevelopment.SetBlockProtection
        OpEventSetBlockProtection_SetBlockProtection_PAdmin_Ct_MBBL_SsaAppl_CodingNvmCoding_CalibrationID: start-on-event=SetBlockProtection, operation=PAdmin_Ct_MBBL_SsaAppl_CodingNvmCoding_CalibrationID.SetBlockProtection
        OpEventSetBlockProtection_SetBlockProtection_PAdmin_NvMBlockDescriptor_FblMetaData: start-on-event=SetBlockProtection, operation=PAdmin_NvMBlockDescriptor_FblMetaData.SetBlockProtection
        OpEventSetBlockProtection_SetBlockProtection_PAdmin_NVP_BLOCK_ID_ECU_LOCATION: start-on-event=SetBlockProtection, operation=PAdmin_NVP_BLOCK_ID_ECU_LOCATION.SetBlockProtection
        OpEventSetBlockProtection_SetBlockProtection_PAdmin_NVP_BLOCK_ID_BELT_ASSEMBLY_MANUF_DATE_AND_SN: start-on-event=SetBlockProtection, operation=PAdmin_NVP_BLOCK_ID_BELT_ASSEMBLY_MANUF_DATE_AND_SN.SetBlockProtection
        OpEventSetBlockProtection_SetBlockProtection_PAdmin_NVP_BLOCK_ID_HB_CALIBRATION: start-on-event=SetBlockProtection, operation=PAdmin_NVP_BLOCK_ID_HB_CALIBRATION.SetBlockProtection
        OpEventSetBlockProtection_SetBlockProtection_PAdmin_NVP_BLOCK_ID_AEE_TRACEABILITY: start-on-event=SetBlockProtection, operation=PAdmin_NVP_BLOCK_ID_AEE_TRACEABILITY.SetBlockProtection
        OpEventSetBlockProtection_SetBlockProtection_PAdmin_NVP_BLOCK_ID_EXECUTION_COUNTERS: start-on-event=SetBlockProtection, operation=PAdmin_NVP_BLOCK_ID_EXECUTION_COUNTERS.SetBlockProtection
        OpEventSetBlockProtection_SetBlockProtection_PAdmin_NVP_BLOCK_ID_TESTS_PARAM: start-on-event=SetBlockProtection, operation=PAdmin_NVP_BLOCK_ID_TESTS_PARAM.SetBlockProtection
        OpEventSetBlockProtection_SetBlockProtection_PAdmin_NVP_BLOCK_ID_CYCLE: start-on-event=SetBlockProtection, operation=PAdmin_NVP_BLOCK_ID_CYCLE.SetBlockProtection
        OpEventSetBlockProtection_SetBlockProtection_PAdmin_NVP_BLOCK_ID_STEP: start-on-event=SetBlockProtection, operation=PAdmin_NVP_BLOCK_ID_STEP.SetBlockProtection
        OpEventSetBlockProtection_SetBlockProtection_PAdmin_CALIB_BLOCK_ID_EOL_PARAM: start-on-event=SetBlockProtection, operation=PAdmin_CALIB_BLOCK_ID_EOL_PARAM.SetBlockProtection
        OpEventSetBlockProtection_SetBlockProtection_PAdmin_CALIB_BLOCK_ID_BFS_PRIO_PARAM: start-on-event=SetBlockProtection, operation=PAdmin_CALIB_BLOCK_ID_BFS_PRIO_PARAM.SetBlockProtection
        OpEventSetBlockProtection_SetBlockProtection_PAdmin_CALIB_BLOCK_ID_PID_PARAM: start-on-event=SetBlockProtection, operation=PAdmin_CALIB_BLOCK_ID_PID_PARAM.SetBlockProtection
        OpEventSetBlockProtection_SetBlockProtection_PAdmin_CALIB_BLOCK_ID_WEIGHT_REL_TABLE: start-on-event=SetBlockProtection, operation=PAdmin_CALIB_BLOCK_ID_WEIGHT_REL_TABLE.SetBlockProtection
        OpEventSetBlockProtection_SetBlockProtection_PAdmin_CALIB_BLOCK_ID_WEIGHT_TENS{0..3}_TABLE: start-on-event=SetBlockProtection, operation=PAdmin_CALIB_BLOCK_ID_WEIGHT_TENS{0..3}_TABLE.SetBlockProtection
        OpEventSetBlockProtection_SetBlockProtection_PAdmin_CALIB_BLOCK_ID_INT_CURRENT_CORR: start-on-event=SetBlockProtection, operation=PAdmin_CALIB_BLOCK_ID_INT_CURRENT_CORR.SetBlockProtection
        OpEventSetBlockProtection_SetBlockProtection_PAdmin_CALIB_BLOCK_ID_INT_CURRENT_TABLE: start-on-event=SetBlockProtection, operation=PAdmin_CALIB_BLOCK_ID_INT_CURRENT_TABLE.SetBlockProtection
        OpEventSetBlockProtection_SetBlockProtection_PAdmin_CALIB_BLOCK_ID_ECPL_ALPHA_TABLE: start-on-event=SetBlockProtection, operation=PAdmin_CALIB_BLOCK_ID_ECPL_ALPHA_TABLE.SetBlockProtection
        OpEventSetBlockProtection_SetBlockProtection_PAdmin_CALIB_BLOCK_ID_POWER_DEGRADATION: start-on-event=SetBlockProtection, operation=PAdmin_CALIB_BLOCK_ID_POWER_DEGRADATION.SetBlockProtection
        OpEventSetBlockProtection_SetBlockProtection_PAdmin_CALIB_BLOCK_ID_ECPL_BETA_TABLE: start-on-event=SetBlockProtection, operation=PAdmin_CALIB_BLOCK_ID_ECPL_BETA_TABLE.SetBlockProtection
        OpEventSetBlockProtection_SetBlockProtection_PAdmin_CALIB_BLOCK_ID_ECPL_OTHER_PARAM: start-on-event=SetBlockProtection, operation=PAdmin_CALIB_BLOCK_ID_ECPL_OTHER_PARAM.SetBlockProtection
        OpEventSetBlockProtection_SetBlockProtection_PAdmin_CALIB_BLOCK_ID_BPA_MOTOR_CURRENT: start-on-event=SetBlockProtection, operation=PAdmin_CALIB_BLOCK_ID_BPA_MOTOR_CURRENT.SetBlockProtection
        OpEventSetBlockProtection_SetBlockProtection_PAdmin_CALIB_BLOCK_ID_VOLT_THRS: start-on-event=SetBlockProtection, operation=PAdmin_CALIB_BLOCK_ID_VOLT_THRS.SetBlockProtection
        OpEventSetBlockProtection_SetBlockProtection_PAdmin_CALIB_BLOCK_ID_BATTERY_LOSS_DETECTION_THRS: start-on-event=SetBlockProtection, operation=PAdmin_CALIB_BLOCK_ID_BATTERY_LOSS_DETECTION_THRS.SetBlockProtection
        OpEventSetBlockProtection_SetBlockProtection_PAdmin_CALIB_BLOCK_ID_BOOST: start-on-event=SetBlockProtection, operation=PAdmin_CALIB_BLOCK_ID_BOOST.SetBlockProtection
        OpEventSetBlockProtection_SetBlockProtection_PAdmin_CALIB_BLOCK_ID_ECU_PROPERTIES: start-on-event=SetBlockProtection, operation=PAdmin_CALIB_BLOCK_ID_ECU_PROPERTIES.SetBlockProtection
        OpEventSetBlockProtection_SetBlockProtection_PAdmin_CALIB_BLOCK_ID_SW_SELF_PROTECTION_THRS: start-on-event=SetBlockProtection, operation=PAdmin_CALIB_BLOCK_ID_SW_SELF_PROTECTION_THRS.SetBlockProtection
        OpEventSetBlockProtection_SetBlockProtection_PAdmin_CALIB_BLOCK_ID_MOTOR_RESIST_PARAM: start-on-event=SetBlockProtection, operation=PAdmin_CALIB_BLOCK_ID_MOTOR_RESIST_PARAM.SetBlockProtection
        OpEventSetBlockProtection_SetBlockProtection_PAdmin_CALIB_BLOCK_ID_BOOST_ACTIVATION: start-on-event=SetBlockProtection, operation=PAdmin_CALIB_BLOCK_ID_BOOST_ACTIVATION.SetBlockProtection
        OpEventSetBlockProtection_SetBlockProtection_PAdmin_NVP_BLOCK_ID_MEASUREMENT_FRAME_12_CONFIG: start-on-event=SetBlockProtection, operation=PAdmin_NVP_BLOCK_ID_MEASUREMENT_FRAME_12_CONFIG.SetBlockProtection
        OpEventSetBlockProtection_SetBlockProtection_PAdmin_NVP_BLOCK_ID_MEASUREMENT_FRAME_CONFIG: start-on-event=SetBlockProtection, operation=PAdmin_NVP_BLOCK_ID_MEASUREMENT_FRAME_CONFIG.SetBlockProtection
        OpEventSetDataIndex_SetDataIndex_PS_NvMBlockDescriptor_FblMetaData: start-on-event=SetDataIndex, operation=PS_NvMBlockDescriptor_FblMetaData.SetDataIndex
        OpEventGetDataIndex_GetDataIndex_PS_NvMBlockDescriptor_FblMetaData: start-on-event=GetDataIndex, operation=PS_NvMBlockDescriptor_FblMetaData.GetDataIndex
        OpEventGetErrorStatus_GetErrorStatus_PS_NVP_BLOCK_ID_WARM_RESET: start-on-event=GetErrorStatus, operation=PS_NVP_BLOCK_ID_WARM_RESET.GetErrorStatus
        OpEventSetRamBlockStatus_SetRamBlockStatus_PS_NVP_BLOCK_ID_WARM_RESET: start-on-event=SetRamBlockStatus, operation=PS_NVP_BLOCK_ID_WARM_RESET.SetRamBlockStatus
        OpEventReadBlock_ReadBlock_PS_NVP_BLOCK_ID_WARM_RESET: start-on-event=ReadBlock, operation=PS_NVP_BLOCK_ID_WARM_RESET.ReadBlock
        OpEventWriteBlock_WriteBlock_PS_NVP_BLOCK_ID_WARM_RESET: start-on-event=WriteBlock, operation=PS_NVP_BLOCK_ID_WARM_RESET.WriteBlock
        OpEventRestoreBlockDefaults_RestoreBlockDefaults_PS_NVP_BLOCK_ID_WARM_RESET: start-on-event=RestoreBlockDefaults, operation=PS_NVP_BLOCK_ID_WARM_RESET.RestoreBlockDefaults
        OpEventInvalidateNvBlock_InvalidateNvBlock_PS_NVP_BLOCK_ID_WARM_RESET: start-on-event=InvalidateNvBlock, operation=PS_NVP_BLOCK_ID_WARM_RESET.InvalidateNvBlock
        OpEventEraseBlock_EraseBlock_PS_NVP_BLOCK_ID_WARM_RESET: start-on-event=EraseBlock, operation=PS_NVP_BLOCK_ID_WARM_RESET.EraseBlock
        OpEventSetBlockProtection_SetBlockProtection_PAdmin_NVP_BLOCK_ID_WARM_RESET: start-on-event=SetBlockProtection, operation=PAdmin_NVP_BLOCK_ID_WARM_RESET.SetBlockProtection
        OpEventGetErrorStatus_GetErrorStatus_PS_NVP_BLOCK_ID_HWA_REPETITION: start-on-event=GetErrorStatus, operation=PS_NVP_BLOCK_ID_HWA_REPETITION.GetErrorStatus
        OpEventGetErrorStatus_GetErrorStatus_PS_NVP_BLOCK_TEMP_SENSOR_TABLE: start-on-event=GetErrorStatus, operation=PS_NVP_BLOCK_TEMP_SENSOR_TABLE.GetErrorStatus
        OpEventGetErrorStatus_GetErrorStatus_PS_NVP_BLOCK_ID_VELOCITY_PID_PARAM: start-on-event=GetErrorStatus, operation=PS_NVP_BLOCK_ID_VELOCITY_PID_PARAM.GetErrorStatus
        OpEventGetErrorStatus_GetErrorStatus_PS_NVP_BLOCK_ID_AEC_STATUS: start-on-event=GetErrorStatus, operation=PS_NVP_BLOCK_ID_AEC_STATUS.GetErrorStatus
        OpEventGetErrorStatus_GetErrorStatus_PS_NVP_BLOCK_ID_ATM_ENABLE_PARAM: start-on-event=GetErrorStatus, operation=PS_NVP_BLOCK_ID_ATM_ENABLE_PARAM.GetErrorStatus
        OpEventSetRamBlockStatus_SetRamBlockStatus_PS_NVP_BLOCK_ID_HWA_REPETITION: start-on-event=SetRamBlockStatus, operation=PS_NVP_BLOCK_ID_HWA_REPETITION.SetRamBlockStatus
        OpEventSetRamBlockStatus_SetRamBlockStatus_PS_NVP_BLOCK_TEMP_SENSOR_TABLE: start-on-event=SetRamBlockStatus, operation=PS_NVP_BLOCK_TEMP_SENSOR_TABLE.SetRamBlockStatus
        OpEventSetRamBlockStatus_SetRamBlockStatus_PS_NVP_BLOCK_ID_VELOCITY_PID_PARAM: start-on-event=SetRamBlockStatus, operation=PS_NVP_BLOCK_ID_VELOCITY_PID_PARAM.SetRamBlockStatus
        OpEventSetRamBlockStatus_SetRamBlockStatus_PS_NVP_BLOCK_ID_AEC_STATUS: start-on-event=SetRamBlockStatus, operation=PS_NVP_BLOCK_ID_AEC_STATUS.SetRamBlockStatus
        OpEventSetRamBlockStatus_SetRamBlockStatus_PS_NVP_BLOCK_ID_ATM_ENABLE_PARAM: start-on-event=SetRamBlockStatus, operation=PS_NVP_BLOCK_ID_ATM_ENABLE_PARAM.SetRamBlockStatus
        OpEventReadBlock_ReadBlock_PS_NVP_BLOCK_ID_HWA_REPETITION: start-on-event=ReadBlock, operation=PS_NVP_BLOCK_ID_HWA_REPETITION.ReadBlock
        OpEventReadBlock_ReadBlock_PS_NVP_BLOCK_TEMP_SENSOR_TABLE: start-on-event=ReadBlock, operation=PS_NVP_BLOCK_TEMP_SENSOR_TABLE.ReadBlock
        OpEventReadBlock_ReadBlock_PS_NVP_BLOCK_ID_VELOCITY_PID_PARAM: start-on-event=ReadBlock, operation=PS_NVP_BLOCK_ID_VELOCITY_PID_PARAM.ReadBlock
        OpEventReadBlock_ReadBlock_PS_NVP_BLOCK_ID_AEC_STATUS: start-on-event=ReadBlock, operation=PS_NVP_BLOCK_ID_AEC_STATUS.ReadBlock
        OpEventReadBlock_ReadBlock_PS_NVP_BLOCK_ID_ATM_ENABLE_PARAM: start-on-event=ReadBlock, operation=PS_NVP_BLOCK_ID_ATM_ENABLE_PARAM.ReadBlock
        OpEventWriteBlock_WriteBlock_PS_NVP_BLOCK_ID_HWA_REPETITION: start-on-event=WriteBlock, operation=PS_NVP_BLOCK_ID_HWA_REPETITION.WriteBlock
        OpEventWriteBlock_WriteBlock_PS_NVP_BLOCK_TEMP_SENSOR_TABLE: start-on-event=WriteBlock, operation=PS_NVP_BLOCK_TEMP_SENSOR_TABLE.WriteBlock
        OpEventWriteBlock_WriteBlock_PS_NVP_BLOCK_ID_VELOCITY_PID_PARAM: start-on-event=WriteBlock, operation=PS_NVP_BLOCK_ID_VELOCITY_PID_PARAM.WriteBlock
        OpEventWriteBlock_WriteBlock_PS_NVP_BLOCK_ID_AEC_STATUS: start-on-event=WriteBlock, operation=PS_NVP_BLOCK_ID_AEC_STATUS.WriteBlock
        OpEventWriteBlock_WriteBlock_PS_NVP_BLOCK_ID_ATM_ENABLE_PARAM: start-on-event=WriteBlock, operation=PS_NVP_BLOCK_ID_ATM_ENABLE_PARAM.WriteBlock
        OpEventRestoreBlockDefaults_RestoreBlockDefaults_PS_NVP_BLOCK_ID_HWA_REPETITION: start-on-event=RestoreBlockDefaults, operation=PS_NVP_BLOCK_ID_HWA_REPETITION.RestoreBlockDefaults
        OpEventRestoreBlockDefaults_RestoreBlockDefaults_PS_NVP_BLOCK_TEMP_SENSOR_TABLE: start-on-event=RestoreBlockDefaults, operation=PS_NVP_BLOCK_TEMP_SENSOR_TABLE.RestoreBlockDefaults
        OpEventRestoreBlockDefaults_RestoreBlockDefaults_PS_NVP_BLOCK_ID_VELOCITY_PID_PARAM: start-on-event=RestoreBlockDefaults, operation=PS_NVP_BLOCK_ID_VELOCITY_PID_PARAM.RestoreBlockDefaults
        OpEventRestoreBlockDefaults_RestoreBlockDefaults_PS_NVP_BLOCK_ID_AEC_STATUS: start-on-event=RestoreBlockDefaults, operation=PS_NVP_BLOCK_ID_AEC_STATUS.RestoreBlockDefaults
        OpEventRestoreBlockDefaults_RestoreBlockDefaults_PS_NVP_BLOCK_ID_ATM_ENABLE_PARAM: start-on-event=RestoreBlockDefaults, operation=PS_NVP_BLOCK_ID_ATM_ENABLE_PARAM.RestoreBlockDefaults
        OpEventInvalidateNvBlock_InvalidateNvBlock_PS_NVP_BLOCK_ID_HWA_REPETITION: start-on-event=InvalidateNvBlock, operation=PS_NVP_BLOCK_ID_HWA_REPETITION.InvalidateNvBlock
        OpEventInvalidateNvBlock_InvalidateNvBlock_PS_NVP_BLOCK_TEMP_SENSOR_TABLE: start-on-event=InvalidateNvBlock, operation=PS_NVP_BLOCK_TEMP_SENSOR_TABLE.InvalidateNvBlock
        OpEventInvalidateNvBlock_InvalidateNvBlock_PS_NVP_BLOCK_ID_VELOCITY_PID_PARAM: start-on-event=InvalidateNvBlock, operation=PS_NVP_BLOCK_ID_VELOCITY_PID_PARAM.InvalidateNvBlock
        OpEventInvalidateNvBlock_InvalidateNvBlock_PS_NVP_BLOCK_ID_AEC_STATUS: start-on-event=InvalidateNvBlock, operation=PS_NVP_BLOCK_ID_AEC_STATUS.InvalidateNvBlock
        OpEventInvalidateNvBlock_InvalidateNvBlock_PS_NVP_BLOCK_ID_ATM_ENABLE_PARAM: start-on-event=InvalidateNvBlock, operation=PS_NVP_BLOCK_ID_ATM_ENABLE_PARAM.InvalidateNvBlock
        OpEventEraseBlock_EraseBlock_PS_NVP_BLOCK_ID_HWA_REPETITION: start-on-event=EraseBlock, operation=PS_NVP_BLOCK_ID_HWA_REPETITION.EraseBlock
        OpEventEraseBlock_EraseBlock_PS_NVP_BLOCK_TEMP_SENSOR_TABLE: start-on-event=EraseBlock, operation=PS_NVP_BLOCK_TEMP_SENSOR_TABLE.EraseBlock
        OpEventEraseBlock_EraseBlock_PS_NVP_BLOCK_ID_VELOCITY_PID_PARAM: start-on-event=EraseBlock, operation=PS_NVP_BLOCK_ID_VELOCITY_PID_PARAM.EraseBlock
        OpEventEraseBlock_EraseBlock_PS_NVP_BLOCK_ID_AEC_STATUS: start-on-event=EraseBlock, operation=PS_NVP_BLOCK_ID_AEC_STATUS.EraseBlock
        OpEventEraseBlock_EraseBlock_PS_NVP_BLOCK_ID_ATM_ENABLE_PARAM: start-on-event=EraseBlock, operation=PS_NVP_BLOCK_ID_ATM_ENABLE_PARAM.EraseBlock
        OpEventSetBlockProtection_SetBlockProtection_PAdmin_NVP_BLOCK_ID_HWA_REPETITION: start-on-event=SetBlockProtection, operation=PAdmin_NVP_BLOCK_ID_HWA_REPETITION.SetBlockProtection
        OpEventSetBlockProtection_SetBlockProtection_PAdmin_NVP_BLOCK_TEMP_SENSOR_TABLE: start-on-event=SetBlockProtection, operation=PAdmin_NVP_BLOCK_TEMP_SENSOR_TABLE.SetBlockProtection
        OpEventSetBlockProtection_SetBlockProtection_PAdmin_NVP_BLOCK_ID_VELOCITY_PID_PARAM: start-on-event=SetBlockProtection, operation=PAdmin_NVP_BLOCK_ID_VELOCITY_PID_PARAM.SetBlockProtection
        OpEventSetBlockProtection_SetBlockProtection_PAdmin_NVP_BLOCK_ID_AEC_STATUS: start-on-event=SetBlockProtection, operation=PAdmin_NVP_BLOCK_ID_AEC_STATUS.SetBlockProtection
        OpEventSetBlockProtection_SetBlockProtection_PAdmin_NVP_BLOCK_ID_ATM_ENABLE_PARAM: start-on-event=SetBlockProtection, operation=PAdmin_NVP_BLOCK_ID_ATM_ENABLE_PARAM.SetBlockProtection
        OpEventGetErrorStatus_GetErrorStatus_PS_Ssa_KeyM_NvM_KeyM_TrustModelChainOfTrustState: start-on-event=GetErrorStatus, operation=PS_Ssa_KeyM_NvM_KeyM_TrustModelChainOfTrustState.GetErrorStatus
        OpEventSetRamBlockStatus_SetRamBlockStatus_PS_Ssa_KeyM_NvM_KeyM_TrustModelChainOfTrustState: start-on-event=SetRamBlockStatus, operation=PS_Ssa_KeyM_NvM_KeyM_TrustModelChainOfTrustState.SetRamBlockStatus
        OpEventReadBlock_ReadBlock_PS_Ssa_KeyM_NvM_KeyM_TrustModelChainOfTrustState: start-on-event=ReadBlock, operation=PS_Ssa_KeyM_NvM_KeyM_TrustModelChainOfTrustState.ReadBlock
        OpEventWriteBlock_WriteBlock_PS_Ssa_KeyM_NvM_KeyM_TrustModelChainOfTrustState: start-on-event=WriteBlock, operation=PS_Ssa_KeyM_NvM_KeyM_TrustModelChainOfTrustState.WriteBlock
        OpEventRestoreBlockDefaults_RestoreBlockDefaults_PS_Ssa_KeyM_NvM_KeyM_TrustModelChainOfTrustState: start-on-event=RestoreBlockDefaults, operation=PS_Ssa_KeyM_NvM_KeyM_TrustModelChainOfTrustState.RestoreBlockDefaults
        OpEventInvalidateNvBlock_InvalidateNvBlock_PS_Ssa_KeyM_NvM_KeyM_TrustModelChainOfTrustState: start-on-event=InvalidateNvBlock, operation=PS_Ssa_KeyM_NvM_KeyM_TrustModelChainOfTrustState.InvalidateNvBlock
        OpEventEraseBlock_EraseBlock_PS_Ssa_KeyM_NvM_KeyM_TrustModelChainOfTrustState: start-on-event=EraseBlock, operation=PS_Ssa_KeyM_NvM_KeyM_TrustModelChainOfTrustState.EraseBlock
        OpEventSetBlockProtection_SetBlockProtection_PAdmin_Ssa_KeyM_NvM_KeyM_TrustModelChainOfTrustState: start-on-event=SetBlockProtection, operation=PAdmin_Ssa_KeyM_NvM_KeyM_TrustModelChainOfTrustState.SetBlockProtection
        OpEventGetErrorStatus_GetErrorStatus_PS_NVP_BLOCK_ID_PRE_SAFE_RECORDER_1: start-on-event=GetErrorStatus, operation=PS_NVP_BLOCK_ID_PRE_SAFE_RECORDER_1.GetErrorStatus
        OpEventSetRamBlockStatus_SetRamBlockStatus_PS_NVP_BLOCK_ID_PRE_SAFE_RECORDER_1: start-on-event=SetRamBlockStatus, operation=PS_NVP_BLOCK_ID_PRE_SAFE_RECORDER_1.SetRamBlockStatus
        OpEventReadBlock_ReadBlock_PS_NVP_BLOCK_ID_PRE_SAFE_RECORDER_1: start-on-event=ReadBlock, operation=PS_NVP_BLOCK_ID_PRE_SAFE_RECORDER_1.ReadBlock
        OpEventWriteBlock_WriteBlock_PS_NVP_BLOCK_ID_PRE_SAFE_RECORDER_1: start-on-event=WriteBlock, operation=PS_NVP_BLOCK_ID_PRE_SAFE_RECORDER_1.WriteBlock
        OpEventRestoreBlockDefaults_RestoreBlockDefaults_PS_NVP_BLOCK_ID_PRE_SAFE_RECORDER_1: start-on-event=RestoreBlockDefaults, operation=PS_NVP_BLOCK_ID_PRE_SAFE_RECORDER_1.RestoreBlockDefaults
        OpEventInvalidateNvBlock_InvalidateNvBlock_PS_NVP_BLOCK_ID_PRE_SAFE_RECORDER_1: start-on-event=InvalidateNvBlock, operation=PS_NVP_BLOCK_ID_PRE_SAFE_RECORDER_1.InvalidateNvBlock
        OpEventEraseBlock_EraseBlock_PS_NVP_BLOCK_ID_PRE_SAFE_RECORDER_1: start-on-event=EraseBlock, operation=PS_NVP_BLOCK_ID_PRE_SAFE_RECORDER_1.EraseBlock
        OpEventSetBlockProtection_SetBlockProtection_PAdmin_NVP_BLOCK_ID_PRE_SAFE_RECORDER_1: start-on-event=SetBlockProtection, operation=PAdmin_NVP_BLOCK_ID_PRE_SAFE_RECORDER_1.SetBlockProtection
        OpEventGetErrorStatus_GetErrorStatus_PS_NVP_BLOCK_ID_PRE_SAFE_RECORDER_2: start-on-event=GetErrorStatus, operation=PS_NVP_BLOCK_ID_PRE_SAFE_RECORDER_2.GetErrorStatus
        OpEventSetRamBlockStatus_SetRamBlockStatus_PS_NVP_BLOCK_ID_PRE_SAFE_RECORDER_2: start-on-event=SetRamBlockStatus, operation=PS_NVP_BLOCK_ID_PRE_SAFE_RECORDER_2.SetRamBlockStatus
        OpEventReadBlock_ReadBlock_PS_NVP_BLOCK_ID_PRE_SAFE_RECORDER_2: start-on-event=ReadBlock, operation=PS_NVP_BLOCK_ID_PRE_SAFE_RECORDER_2.ReadBlock
        OpEventWriteBlock_WriteBlock_PS_NVP_BLOCK_ID_PRE_SAFE_RECORDER_2: start-on-event=WriteBlock, operation=PS_NVP_BLOCK_ID_PRE_SAFE_RECORDER_2.WriteBlock
        OpEventRestoreBlockDefaults_RestoreBlockDefaults_PS_NVP_BLOCK_ID_PRE_SAFE_RECORDER_2: start-on-event=RestoreBlockDefaults, operation=PS_NVP_BLOCK_ID_PRE_SAFE_RECORDER_2.RestoreBlockDefaults
        OpEventInvalidateNvBlock_InvalidateNvBlock_PS_NVP_BLOCK_ID_PRE_SAFE_RECORDER_2: start-on-event=InvalidateNvBlock, operation=PS_NVP_BLOCK_ID_PRE_SAFE_RECORDER_2.InvalidateNvBlock
        OpEventEraseBlock_EraseBlock_PS_NVP_BLOCK_ID_PRE_SAFE_RECORDER_2: start-on-event=EraseBlock, operation=PS_NVP_BLOCK_ID_PRE_SAFE_RECORDER_2.EraseBlock
        OpEventSetBlockProtection_SetBlockProtection_PAdmin_NVP_BLOCK_ID_PRE_SAFE_RECORDER_2: start-on-event=SetBlockProtection, operation=PAdmin_NVP_BLOCK_ID_PRE_SAFE_RECORDER_2.SetBlockProtection
        OpEventGetErrorStatus_GetErrorStatus_PS_NVP_BLOCK_ID_PRE_SAFE_RECORDER_ID: start-on-event=GetErrorStatus, operation=PS_NVP_BLOCK_ID_PRE_SAFE_RECORDER_ID.GetErrorStatus
        OpEventSetRamBlockStatus_SetRamBlockStatus_PS_NVP_BLOCK_ID_PRE_SAFE_RECORDER_ID: start-on-event=SetRamBlockStatus, operation=PS_NVP_BLOCK_ID_PRE_SAFE_RECORDER_ID.SetRamBlockStatus
        OpEventReadBlock_ReadBlock_PS_NVP_BLOCK_ID_PRE_SAFE_RECORDER_ID: start-on-event=ReadBlock, operation=PS_NVP_BLOCK_ID_PRE_SAFE_RECORDER_ID.ReadBlock
        OpEventWriteBlock_WriteBlock_PS_NVP_BLOCK_ID_PRE_SAFE_RECORDER_ID: start-on-event=WriteBlock, operation=PS_NVP_BLOCK_ID_PRE_SAFE_RECORDER_ID.WriteBlock
        OpEventRestoreBlockDefaults_RestoreBlockDefaults_PS_NVP_BLOCK_ID_PRE_SAFE_RECORDER_ID: start-on-event=RestoreBlockDefaults, operation=PS_NVP_BLOCK_ID_PRE_SAFE_RECORDER_ID.RestoreBlockDefaults
        OpEventInvalidateNvBlock_InvalidateNvBlock_PS_NVP_BLOCK_ID_PRE_SAFE_RECORDER_ID: start-on-event=InvalidateNvBlock, operation=PS_NVP_BLOCK_ID_PRE_SAFE_RECORDER_ID.InvalidateNvBlock
        OpEventEraseBlock_EraseBlock_PS_NVP_BLOCK_ID_PRE_SAFE_RECORDER_ID: start-on-event=EraseBlock, operation=PS_NVP_BLOCK_ID_PRE_SAFE_RECORDER_ID.EraseBlock
        OpEventSetBlockProtection_SetBlockProtection_PAdmin_NVP_BLOCK_ID_PRE_SAFE_RECORDER_ID: start-on-event=SetBlockProtection, operation=PAdmin_NVP_BLOCK_ID_PRE_SAFE_RECORDER_ID.SetBlockProtection
        OpEventGetErrorStatus_GetErrorStatus_PS_NVP_BLOCK_ID_SYSTEM_CONTEXT_0: start-on-event=GetErrorStatus, operation=PS_NVP_BLOCK_ID_SYSTEM_CONTEXT_0.GetErrorStatus
        OpEventSetRamBlockStatus_SetRamBlockStatus_PS_NVP_BLOCK_ID_SYSTEM_CONTEXT_0: start-on-event=SetRamBlockStatus, operation=PS_NVP_BLOCK_ID_SYSTEM_CONTEXT_0.SetRamBlockStatus
        OpEventReadBlock_ReadBlock_PS_NVP_BLOCK_ID_SYSTEM_CONTEXT_0: start-on-event=ReadBlock, operation=PS_NVP_BLOCK_ID_SYSTEM_CONTEXT_0.ReadBlock
        OpEventWriteBlock_WriteBlock_PS_NVP_BLOCK_ID_SYSTEM_CONTEXT_0: start-on-event=WriteBlock, operation=PS_NVP_BLOCK_ID_SYSTEM_CONTEXT_0.WriteBlock
        OpEventInvalidateNvBlock_InvalidateNvBlock_PS_NVP_BLOCK_ID_SYSTEM_CONTEXT_0: start-on-event=InvalidateNvBlock, operation=PS_NVP_BLOCK_ID_SYSTEM_CONTEXT_0.InvalidateNvBlock
        OpEventEraseBlock_EraseBlock_PS_NVP_BLOCK_ID_SYSTEM_CONTEXT_0: start-on-event=EraseBlock, operation=PS_NVP_BLOCK_ID_SYSTEM_CONTEXT_0.EraseBlock
        OpEventSetBlockProtection_SetBlockProtection_PAdmin_NVP_BLOCK_ID_SYSTEM_CONTEXT_0: start-on-event=SetBlockProtection, operation=PAdmin_NVP_BLOCK_ID_SYSTEM_CONTEXT_0.SetBlockProtection
        OpEventGetErrorStatus_GetErrorStatus_PS_NVP_BLOCK_ID_SYSTEM_CONTEXT_1: start-on-event=GetErrorStatus, operation=PS_NVP_BLOCK_ID_SYSTEM_CONTEXT_1.GetErrorStatus
        OpEventGetErrorStatus_GetErrorStatus_PS_NVP_BLOCK_ID_SYSTEM_CONTEXT_2: start-on-event=GetErrorStatus, operation=PS_NVP_BLOCK_ID_SYSTEM_CONTEXT_2.GetErrorStatus
        OpEventSetRamBlockStatus_SetRamBlockStatus_PS_NVP_BLOCK_ID_SYSTEM_CONTEXT_1: start-on-event=SetRamBlockStatus, operation=PS_NVP_BLOCK_ID_SYSTEM_CONTEXT_1.SetRamBlockStatus
        OpEventSetRamBlockStatus_SetRamBlockStatus_PS_NVP_BLOCK_ID_SYSTEM_CONTEXT_2: start-on-event=SetRamBlockStatus, operation=PS_NVP_BLOCK_ID_SYSTEM_CONTEXT_2.SetRamBlockStatus
        OpEventReadBlock_ReadBlock_PS_NVP_BLOCK_ID_SYSTEM_CONTEXT_1: start-on-event=ReadBlock, operation=PS_NVP_BLOCK_ID_SYSTEM_CONTEXT_1.ReadBlock
        OpEventReadBlock_ReadBlock_PS_NVP_BLOCK_ID_SYSTEM_CONTEXT_2: start-on-event=ReadBlock, operation=PS_NVP_BLOCK_ID_SYSTEM_CONTEXT_2.ReadBlock
        OpEventWriteBlock_WriteBlock_PS_NVP_BLOCK_ID_SYSTEM_CONTEXT_1: start-on-event=WriteBlock, operation=PS_NVP_BLOCK_ID_SYSTEM_CONTEXT_1.WriteBlock
        OpEventWriteBlock_WriteBlock_PS_NVP_BLOCK_ID_SYSTEM_CONTEXT_2: start-on-event=WriteBlock, operation=PS_NVP_BLOCK_ID_SYSTEM_CONTEXT_2.WriteBlock
        OpEventInvalidateNvBlock_InvalidateNvBlock_PS_NVP_BLOCK_ID_SYSTEM_CONTEXT_1: start-on-event=InvalidateNvBlock, operation=PS_NVP_BLOCK_ID_SYSTEM_CONTEXT_1.InvalidateNvBlock
        OpEventInvalidateNvBlock_InvalidateNvBlock_PS_NVP_BLOCK_ID_SYSTEM_CONTEXT_2: start-on-event=InvalidateNvBlock, operation=PS_NVP_BLOCK_ID_SYSTEM_CONTEXT_2.InvalidateNvBlock
        OpEventEraseBlock_EraseBlock_PS_NVP_BLOCK_ID_SYSTEM_CONTEXT_1: start-on-event=EraseBlock, operation=PS_NVP_BLOCK_ID_SYSTEM_CONTEXT_1.EraseBlock
        OpEventEraseBlock_EraseBlock_PS_NVP_BLOCK_ID_SYSTEM_CONTEXT_2: start-on-event=EraseBlock, operation=PS_NVP_BLOCK_ID_SYSTEM_CONTEXT_2.EraseBlock
        OpEventSetBlockProtection_SetBlockProtection_PAdmin_NVP_BLOCK_ID_SYSTEM_CONTEXT_1: start-on-event=SetBlockProtection, operation=PAdmin_NVP_BLOCK_ID_SYSTEM_CONTEXT_1.SetBlockProtection
        OpEventSetBlockProtection_SetBlockProtection_PAdmin_NVP_BLOCK_ID_SYSTEM_CONTEXT_2: start-on-event=SetBlockProtection, operation=PAdmin_NVP_BLOCK_ID_SYSTEM_CONTEXT_2.SetBlockProtection
        OpEventGetErrorStatus_GetErrorStatus_PS_NVP_BLOCK_ID_CYCLE_DELAYS_MB: start-on-event=GetErrorStatus, operation=PS_NVP_BLOCK_ID_CYCLE_DELAYS_MB.GetErrorStatus
        OpEventGetErrorStatus_GetErrorStatus_PS_NVP_BLOCK_ID_HAPTIC_CONFIG_MB: start-on-event=GetErrorStatus, operation=PS_NVP_BLOCK_ID_HAPTIC_CONFIG_MB.GetErrorStatus
        OpEventGetErrorStatus_GetErrorStatus_PS_NVP_BLOCK_ID_EOL_MAPPING_MB: start-on-event=GetErrorStatus, operation=PS_NVP_BLOCK_ID_EOL_MAPPING_MB.GetErrorStatus
        OpEventSetRamBlockStatus_SetRamBlockStatus_PS_NVP_BLOCK_ID_CYCLE_DELAYS_MB: start-on-event=SetRamBlockStatus, operation=PS_NVP_BLOCK_ID_CYCLE_DELAYS_MB.SetRamBlockStatus
        OpEventSetRamBlockStatus_SetRamBlockStatus_PS_NVP_BLOCK_ID_HAPTIC_CONFIG_MB: start-on-event=SetRamBlockStatus, operation=PS_NVP_BLOCK_ID_HAPTIC_CONFIG_MB.SetRamBlockStatus
        OpEventSetRamBlockStatus_SetRamBlockStatus_PS_NVP_BLOCK_ID_EOL_MAPPING_MB: start-on-event=SetRamBlockStatus, operation=PS_NVP_BLOCK_ID_EOL_MAPPING_MB.SetRamBlockStatus
        OpEventReadBlock_ReadBlock_PS_NVP_BLOCK_ID_CYCLE_DELAYS_MB: start-on-event=ReadBlock, operation=PS_NVP_BLOCK_ID_CYCLE_DELAYS_MB.ReadBlock
        OpEventReadBlock_ReadBlock_PS_NVP_BLOCK_ID_HAPTIC_CONFIG_MB: start-on-event=ReadBlock, operation=PS_NVP_BLOCK_ID_HAPTIC_CONFIG_MB.ReadBlock
        OpEventReadBlock_ReadBlock_PS_NVP_BLOCK_ID_EOL_MAPPING_MB: start-on-event=ReadBlock, operation=PS_NVP_BLOCK_ID_EOL_MAPPING_MB.ReadBlock
        OpEventWriteBlock_WriteBlock_PS_NVP_BLOCK_ID_CYCLE_DELAYS_MB: start-on-event=WriteBlock, operation=PS_NVP_BLOCK_ID_CYCLE_DELAYS_MB.WriteBlock
        OpEventWriteBlock_WriteBlock_PS_NVP_BLOCK_ID_HAPTIC_CONFIG_MB: start-on-event=WriteBlock, operation=PS_NVP_BLOCK_ID_HAPTIC_CONFIG_MB.WriteBlock
        OpEventWriteBlock_WriteBlock_PS_NVP_BLOCK_ID_EOL_MAPPING_MB: start-on-event=WriteBlock, operation=PS_NVP_BLOCK_ID_EOL_MAPPING_MB.WriteBlock
        OpEventRestoreBlockDefaults_RestoreBlockDefaults_PS_NVP_BLOCK_ID_CYCLE_DELAYS_MB: start-on-event=RestoreBlockDefaults, operation=PS_NVP_BLOCK_ID_CYCLE_DELAYS_MB.RestoreBlockDefaults
        OpEventRestoreBlockDefaults_RestoreBlockDefaults_PS_NVP_BLOCK_ID_HAPTIC_CONFIG_MB: start-on-event=RestoreBlockDefaults, operation=PS_NVP_BLOCK_ID_HAPTIC_CONFIG_MB.RestoreBlockDefaults
        OpEventRestoreBlockDefaults_RestoreBlockDefaults_PS_NVP_BLOCK_ID_EOL_MAPPING_MB: start-on-event=RestoreBlockDefaults, operation=PS_NVP_BLOCK_ID_EOL_MAPPING_MB.RestoreBlockDefaults
        OpEventInvalidateNvBlock_InvalidateNvBlock_PS_NVP_BLOCK_ID_CYCLE_DELAYS_MB: start-on-event=InvalidateNvBlock, operation=PS_NVP_BLOCK_ID_CYCLE_DELAYS_MB.InvalidateNvBlock
        OpEventInvalidateNvBlock_InvalidateNvBlock_PS_NVP_BLOCK_ID_HAPTIC_CONFIG_MB: start-on-event=InvalidateNvBlock, operation=PS_NVP_BLOCK_ID_HAPTIC_CONFIG_MB.InvalidateNvBlock
        OpEventInvalidateNvBlock_InvalidateNvBlock_PS_NVP_BLOCK_ID_EOL_MAPPING_MB: start-on-event=InvalidateNvBlock, operation=PS_NVP_BLOCK_ID_EOL_MAPPING_MB.InvalidateNvBlock
        OpEventEraseBlock_EraseBlock_PS_NVP_BLOCK_ID_CYCLE_DELAYS_MB: start-on-event=EraseBlock, operation=PS_NVP_BLOCK_ID_CYCLE_DELAYS_MB.EraseBlock
        OpEventEraseBlock_EraseBlock_PS_NVP_BLOCK_ID_HAPTIC_CONFIG_MB: start-on-event=EraseBlock, operation=PS_NVP_BLOCK_ID_HAPTIC_CONFIG_MB.EraseBlock
        OpEventEraseBlock_EraseBlock_PS_NVP_BLOCK_ID_EOL_MAPPING_MB: start-on-event=EraseBlock, operation=PS_NVP_BLOCK_ID_EOL_MAPPING_MB.EraseBlock
        OpEventSetBlockProtection_SetBlockProtection_PAdmin_NVP_BLOCK_ID_CYCLE_DELAYS_MB: start-on-event=SetBlockProtection, operation=PAdmin_NVP_BLOCK_ID_CYCLE_DELAYS_MB.SetBlockProtection
        OpEventSetBlockProtection_SetBlockProtection_PAdmin_NVP_BLOCK_ID_HAPTIC_CONFIG_MB: start-on-event=SetBlockProtection, operation=PAdmin_NVP_BLOCK_ID_HAPTIC_CONFIG_MB.SetBlockProtection
        OpEventSetBlockProtection_SetBlockProtection_PAdmin_NVP_BLOCK_ID_EOL_MAPPING_MB: start-on-event=SetBlockProtection, operation=PAdmin_NVP_BLOCK_ID_EOL_MAPPING_MB.SetBlockProtection
        OpEventGetErrorStatus_GetErrorStatus_PS_NVP_BLOCK_ID_HW_VERSION: start-on-event=GetErrorStatus, operation=PS_NVP_BLOCK_ID_HW_VERSION.GetErrorStatus
        OpEventSetRamBlockStatus_SetRamBlockStatus_PS_NVP_BLOCK_ID_HW_VERSION: start-on-event=SetRamBlockStatus, operation=PS_NVP_BLOCK_ID_HW_VERSION.SetRamBlockStatus
        OpEventReadBlock_ReadBlock_PS_NVP_BLOCK_ID_HW_VERSION: start-on-event=ReadBlock, operation=PS_NVP_BLOCK_ID_HW_VERSION.ReadBlock
        OpEventWriteBlock_WriteBlock_PS_NVP_BLOCK_ID_HW_VERSION: start-on-event=WriteBlock, operation=PS_NVP_BLOCK_ID_HW_VERSION.WriteBlock
        OpEventRestoreBlockDefaults_RestoreBlockDefaults_PS_NVP_BLOCK_ID_HW_VERSION: start-on-event=RestoreBlockDefaults, operation=PS_NVP_BLOCK_ID_HW_VERSION.RestoreBlockDefaults
        OpEventInvalidateNvBlock_InvalidateNvBlock_PS_NVP_BLOCK_ID_HW_VERSION: start-on-event=InvalidateNvBlock, operation=PS_NVP_BLOCK_ID_HW_VERSION.InvalidateNvBlock
        OpEventEraseBlock_EraseBlock_PS_NVP_BLOCK_ID_HW_VERSION: start-on-event=EraseBlock, operation=PS_NVP_BLOCK_ID_HW_VERSION.EraseBlock
        OpEventSetBlockProtection_SetBlockProtection_PAdmin_NVP_BLOCK_ID_HW_VERSION: start-on-event=SetBlockProtection, operation=PAdmin_NVP_BLOCK_ID_HW_VERSION.SetBlockProtection
        OpEventGetErrorStatus_GetErrorStatus_PS_NVP_BLOCK_ID_CAN_INPUT_SIGNALS: start-on-event=GetErrorStatus, operation=PS_NVP_BLOCK_ID_CAN_INPUT_SIGNALS.GetErrorStatus
        OpEventSetRamBlockStatus_SetRamBlockStatus_PS_NVP_BLOCK_ID_CAN_INPUT_SIGNALS: start-on-event=SetRamBlockStatus, operation=PS_NVP_BLOCK_ID_CAN_INPUT_SIGNALS.SetRamBlockStatus
        OpEventReadBlock_ReadBlock_PS_NVP_BLOCK_ID_CAN_INPUT_SIGNALS: start-on-event=ReadBlock, operation=PS_NVP_BLOCK_ID_CAN_INPUT_SIGNALS.ReadBlock
        OpEventWriteBlock_WriteBlock_PS_NVP_BLOCK_ID_CAN_INPUT_SIGNALS: start-on-event=WriteBlock, operation=PS_NVP_BLOCK_ID_CAN_INPUT_SIGNALS.WriteBlock
        OpEventRestoreBlockDefaults_RestoreBlockDefaults_PS_NVP_BLOCK_ID_CAN_INPUT_SIGNALS: start-on-event=RestoreBlockDefaults, operation=PS_NVP_BLOCK_ID_CAN_INPUT_SIGNALS.RestoreBlockDefaults
        OpEventInvalidateNvBlock_InvalidateNvBlock_PS_NVP_BLOCK_ID_CAN_INPUT_SIGNALS: start-on-event=InvalidateNvBlock, operation=PS_NVP_BLOCK_ID_CAN_INPUT_SIGNALS.InvalidateNvBlock
        OpEventEraseBlock_EraseBlock_PS_NVP_BLOCK_ID_CAN_INPUT_SIGNALS: start-on-event=EraseBlock, operation=PS_NVP_BLOCK_ID_CAN_INPUT_SIGNALS.EraseBlock
        OpEventSetBlockProtection_SetBlockProtection_PAdmin_NVP_BLOCK_ID_CAN_INPUT_SIGNALS: start-on-event=SetBlockProtection, operation=PAdmin_NVP_BLOCK_ID_CAN_INPUT_SIGNALS.SetBlockProtection
        OpEventGetErrorStatus_GetErrorStatus_PS_NVP_BLOCK_ID_PCBA_PPN: start-on-event=GetErrorStatus, operation=PS_NVP_BLOCK_ID_PCBA_PPN.GetErrorStatus
        OpEventSetRamBlockStatus_SetRamBlockStatus_PS_NVP_BLOCK_ID_PCBA_PPN: start-on-event=SetRamBlockStatus, operation=PS_NVP_BLOCK_ID_PCBA_PPN.SetRamBlockStatus
        OpEventReadBlock_ReadBlock_PS_NVP_BLOCK_ID_PCBA_PPN: start-on-event=ReadBlock, operation=PS_NVP_BLOCK_ID_PCBA_PPN.ReadBlock
        OpEventWriteBlock_WriteBlock_PS_NVP_BLOCK_ID_PCBA_PPN: start-on-event=WriteBlock, operation=PS_NVP_BLOCK_ID_PCBA_PPN.WriteBlock
        OpEventRestoreBlockDefaults_RestoreBlockDefaults_PS_NVP_BLOCK_ID_PCBA_PPN: start-on-event=RestoreBlockDefaults, operation=PS_NVP_BLOCK_ID_PCBA_PPN.RestoreBlockDefaults
        OpEventInvalidateNvBlock_InvalidateNvBlock_PS_NVP_BLOCK_ID_PCBA_PPN: start-on-event=InvalidateNvBlock, operation=PS_NVP_BLOCK_ID_PCBA_PPN.InvalidateNvBlock
        OpEventEraseBlock_EraseBlock_PS_NVP_BLOCK_ID_PCBA_PPN: start-on-event=EraseBlock, operation=PS_NVP_BLOCK_ID_PCBA_PPN.EraseBlock
        OpEventSetBlockProtection_SetBlockProtection_PAdmin_NVP_BLOCK_ID_PCBA_PPN: start-on-event=SetBlockProtection, operation=PAdmin_NVP_BLOCK_ID_PCBA_PPN.SetBlockProtection
        OpEventGetErrorStatus_GetErrorStatus_PS_NVP_BLOCK_ID_CSR_SUPPLIER_SIGNATURE: start-on-event=GetErrorStatus, operation=PS_NVP_BLOCK_ID_CSR_SUPPLIER_SIGNATURE.GetErrorStatus
        OpEventSetRamBlockStatus_SetRamBlockStatus_PS_NVP_BLOCK_ID_CSR_SUPPLIER_SIGNATURE: start-on-event=SetRamBlockStatus, operation=PS_NVP_BLOCK_ID_CSR_SUPPLIER_SIGNATURE.SetRamBlockStatus
        OpEventReadBlock_ReadBlock_PS_NVP_BLOCK_ID_CSR_SUPPLIER_SIGNATURE: start-on-event=ReadBlock, operation=PS_NVP_BLOCK_ID_CSR_SUPPLIER_SIGNATURE.ReadBlock
        OpEventWriteBlock_WriteBlock_PS_NVP_BLOCK_ID_CSR_SUPPLIER_SIGNATURE: start-on-event=WriteBlock, operation=PS_NVP_BLOCK_ID_CSR_SUPPLIER_SIGNATURE.WriteBlock
        OpEventInvalidateNvBlock_InvalidateNvBlock_PS_NVP_BLOCK_ID_CSR_SUPPLIER_SIGNATURE: start-on-event=InvalidateNvBlock, operation=PS_NVP_BLOCK_ID_CSR_SUPPLIER_SIGNATURE.InvalidateNvBlock
        OpEventEraseBlock_EraseBlock_PS_NVP_BLOCK_ID_CSR_SUPPLIER_SIGNATURE: start-on-event=EraseBlock, operation=PS_NVP_BLOCK_ID_CSR_SUPPLIER_SIGNATURE.EraseBlock
        OpEventSetBlockProtection_SetBlockProtection_PAdmin_NVP_BLOCK_ID_CSR_SUPPLIER_SIGNATURE: start-on-event=SetBlockProtection, operation=PAdmin_NVP_BLOCK_ID_CSR_SUPPLIER_SIGNATURE.SetBlockProtection
        OpEventGetErrorStatus_GetErrorStatus_PS_NVP_BLOCK_ID_HW_PARTNUMBER: start-on-event=GetErrorStatus, operation=PS_NVP_BLOCK_ID_HW_PARTNUMBER.GetErrorStatus
        OpEventSetRamBlockStatus_SetRamBlockStatus_PS_NVP_BLOCK_ID_HW_PARTNUMBER: start-on-event=SetRamBlockStatus, operation=PS_NVP_BLOCK_ID_HW_PARTNUMBER.SetRamBlockStatus
        OpEventReadBlock_ReadBlock_PS_NVP_BLOCK_ID_HW_PARTNUMBER: start-on-event=ReadBlock, operation=PS_NVP_BLOCK_ID_HW_PARTNUMBER.ReadBlock
        OpEventWriteBlock_WriteBlock_PS_NVP_BLOCK_ID_HW_PARTNUMBER: start-on-event=WriteBlock, operation=PS_NVP_BLOCK_ID_HW_PARTNUMBER.WriteBlock
        OpEventInvalidateNvBlock_InvalidateNvBlock_PS_NVP_BLOCK_ID_HW_PARTNUMBER: start-on-event=InvalidateNvBlock, operation=PS_NVP_BLOCK_ID_HW_PARTNUMBER.InvalidateNvBlock
        OpEventEraseBlock_EraseBlock_PS_NVP_BLOCK_ID_HW_PARTNUMBER: start-on-event=EraseBlock, operation=PS_NVP_BLOCK_ID_HW_PARTNUMBER.EraseBlock
        OpEventSetBlockProtection_SetBlockProtection_PAdmin_NVP_BLOCK_ID_HW_PARTNUMBER: start-on-event=SetBlockProtection, operation=PAdmin_NVP_BLOCK_ID_HW_PARTNUMBER.SetBlockProtection
        OpEventRestoreBlockDefaults_RestoreBlockDefaults_PS_NVP_BLOCK_ID_HW_PARTNUMBER: start-on-event=RestoreBlockDefaults, operation=PS_NVP_BLOCK_ID_HW_PARTNUMBER.RestoreBlockDefaults
        OpEventRestoreBlockDefaults_RestoreBlockDefaults_PS_NVP_BLOCK_ID_CSR_SUPPLIER_SIGNATURE: start-on-event=RestoreBlockDefaults, operation=PS_NVP_BLOCK_ID_CSR_SUPPLIER_SIGNATURE.RestoreBlockDefaults
      port-api-options:
        {enable-take-address=true, indirect-api=false, port-defined-argument-value{value=3, value-type=NvM_BlockIdType}, port=PS_Ssa_CodingNvM_Coding_CodingVIN}
        {enable-take-address=true, indirect-api=false, port-defined-argument-value{value=3, value-type=NvM_BlockIdType}, port=PAdmin_Ssa_CodingNvM_Coding_CodingVIN}
        {enable-take-address=true, indirect-api=false, port-defined-argument-value{value=4, value-type=NvM_BlockIdType}, port=PS_Ssa_CodingNvM_Coding_CurrentVIN}
        {enable-take-address=true, indirect-api=false, port-defined-argument-value{value=4, value-type=NvM_BlockIdType}, port=PAdmin_Ssa_CodingNvM_Coding_CurrentVIN}
        {enable-take-address=true, indirect-api=false, port-defined-argument-value{value=5, value-type=NvM_BlockIdType}, port=PS_Ssa_RightsM_NvM_RightsM_AclVersion}
        {enable-take-address=true, indirect-api=false, port-defined-argument-value{value=5, value-type=NvM_BlockIdType}, port=PAdmin_Ssa_RightsM_NvM_RightsM_AclVersion}
        {enable-take-address=true, indirect-api=false, port-defined-argument-value{value=6, value-type=NvM_BlockIdType}, port=PS_Ssa_RightsM_NvM_RightsM_Nonce}
        {enable-take-address=true, indirect-api=false, port-defined-argument-value{value=6, value-type=NvM_BlockIdType}, port=PAdmin_Ssa_RightsM_NvM_RightsM_Nonce}
        {enable-take-address=true, indirect-api=false, port-defined-argument-value{value=7, value-type=NvM_BlockIdType}, port=PS_Ssa_RightsM_NvM_RightsM_PostProductionStatus}
        {enable-take-address=true, indirect-api=false, port-defined-argument-value{value=7, value-type=NvM_BlockIdType}, port=PAdmin_Ssa_RightsM_NvM_RightsM_PostProductionStatus}
        {enable-take-address=true, indirect-api=false, port-defined-argument-value{value=8, value-type=NvM_BlockIdType}, port=PS_Ssa_SecLogNvM_SecLog_LogDataEvnt10_FailedPduMacVerif}
        {enable-take-address=true, indirect-api=false, port-defined-argument-value{value=8, value-type=NvM_BlockIdType}, port=PAdmin_Ssa_SecLogNvM_SecLog_LogDataEvnt10_FailedPduMacVerif}
        {enable-take-address=true, indirect-api=false, port-defined-argument-value{value=9, value-type=NvM_BlockIdType}, port=PS_Ssa_SecLogNvM_SecLog_LogDataEvnt11_SecOrAuthBoot}
        {enable-take-address=true, indirect-api=false, port-defined-argument-value{value=9, value-type=NvM_BlockIdType}, port=PAdmin_Ssa_SecLogNvM_SecLog_LogDataEvnt11_SecOrAuthBoot}
        {enable-take-address=true, indirect-api=false, port-defined-argument-value{value=10, value-type=NvM_BlockIdType}, port=PS_Ssa_SecLogNvM_SecLog_LogDataEvnt12_ChangeOfVin}
        {enable-take-address=true, indirect-api=false, port-defined-argument-value{value=10, value-type=NvM_BlockIdType}, port=PAdmin_Ssa_SecLogNvM_SecLog_LogDataEvnt12_ChangeOfVin}
        {enable-take-address=true, indirect-api=false, port-defined-argument-value{value=11, value-type=NvM_BlockIdType}, port=PS_Ssa_SecLogNvM_SecLog_LogDataEvnt13_AclReplacement}
        {enable-take-address=true, indirect-api=false, port-defined-argument-value{value=11, value-type=NvM_BlockIdType}, port=PAdmin_Ssa_SecLogNvM_SecLog_LogDataEvnt13_AclReplacement}
        {enable-take-address=true, indirect-api=false, port-defined-argument-value{value=12, value-type=NvM_BlockIdType}, port=PS_Ssa_SecLogNvM_SecLog_LogDataEvnt1_FailedCertVerif}
        {enable-take-address=true, indirect-api=false, port-defined-argument-value{value=12, value-type=NvM_BlockIdType}, port=PAdmin_Ssa_SecLogNvM_SecLog_LogDataEvnt1_FailedCertVerif}
        {enable-take-address=true, indirect-api=false, port-defined-argument-value{value=13, value-type=NvM_BlockIdType}, port=PS_Ssa_SecLogNvM_SecLog_LogDataEvnt2_SucCertVerif}
        {enable-take-address=true, indirect-api=false, port-defined-argument-value{value=13, value-type=NvM_BlockIdType}, port=PAdmin_Ssa_SecLogNvM_SecLog_LogDataEvnt2_SucCertVerif}
        {enable-take-address=true, indirect-api=false, port-defined-argument-value{value=14, value-type=NvM_BlockIdType}, port=PS_Ssa_SecLogNvM_SecLog_LogDataEvnt3_SucAuthAndEnhanceRights}
        {enable-take-address=true, indirect-api=false, port-defined-argument-value{value=14, value-type=NvM_BlockIdType}, port=PAdmin_Ssa_SecLogNvM_SecLog_LogDataEvnt3_SucAuthAndEnhanceRights}
        {enable-take-address=true, indirect-api=false, port-defined-argument-value{value=15, value-type=NvM_BlockIdType}, port=PS_Ssa_SecLogNvM_SecLog_LogDataEvnt4_AuthBySecAccess}
        {enable-take-address=true, indirect-api=false, port-defined-argument-value{value=15, value-type=NvM_BlockIdType}, port=PAdmin_Ssa_SecLogNvM_SecLog_LogDataEvnt4_AuthBySecAccess}
        {enable-take-address=true, indirect-api=false, port-defined-argument-value{value=16, value-type=NvM_BlockIdType}, port=PS_Ssa_SecLogNvM_SecLog_LogDataEvnt5_SucDiagServiceExec}
        {enable-take-address=true, indirect-api=false, port-defined-argument-value{value=16, value-type=NvM_BlockIdType}, port=PAdmin_Ssa_SecLogNvM_SecLog_LogDataEvnt5_SucDiagServiceExec}
        {enable-take-address=true, indirect-api=false, port-defined-argument-value{value=17, value-type=NvM_BlockIdType}, port=PS_Ssa_SecLogNvM_SecLog_LogDataEvnt6_RightsMgmt}
        {enable-take-address=true, indirect-api=false, port-defined-argument-value{value=17, value-type=NvM_BlockIdType}, port=PAdmin_Ssa_SecLogNvM_SecLog_LogDataEvnt6_RightsMgmt}
        {enable-take-address=true, indirect-api=false, port-defined-argument-value{value=18, value-type=NvM_BlockIdType}, port=PS_Ssa_SecLogNvM_SecLog_LogDataEvnt7_SigVerif}
        {enable-take-address=true, indirect-api=false, port-defined-argument-value{value=18, value-type=NvM_BlockIdType}, port=PAdmin_Ssa_SecLogNvM_SecLog_LogDataEvnt7_SigVerif}
        {enable-take-address=true, indirect-api=false, port-defined-argument-value{value=19, value-type=NvM_BlockIdType}, port=PS_Ssa_SecLogNvM_SecLog_LogDataEvnt8_TickCountDateAndTime}
        {enable-take-address=true, indirect-api=false, port-defined-argument-value{value=19, value-type=NvM_BlockIdType}, port=PAdmin_Ssa_SecLogNvM_SecLog_LogDataEvnt8_TickCountDateAndTime}
        {enable-take-address=true, indirect-api=false, port-defined-argument-value{value=20, value-type=NvM_BlockIdType}, port=PS_Ssa_SecLogNvM_SecLog_LogDataEvnt9_SecOcMisconfig}
        {enable-take-address=true, indirect-api=false, port-defined-argument-value{value=20, value-type=NvM_BlockIdType}, port=PAdmin_Ssa_SecLogNvM_SecLog_LogDataEvnt9_SecOcMisconfig}
        {enable-take-address=true, indirect-api=false, port-defined-argument-value{value=21, value-type=NvM_BlockIdType}, port=PS_Ssa_SecLogNvM_SecLog_LogFailedMacVerifCount_ExceededTh1}
        {enable-take-address=true, indirect-api=false, port-defined-argument-value{value=21, value-type=NvM_BlockIdType}, port=PAdmin_Ssa_SecLogNvM_SecLog_LogFailedMacVerifCount_ExceededTh1}
        {enable-take-address=true, indirect-api=false, port-defined-argument-value{value=22, value-type=NvM_BlockIdType}, port=PS_Ssa_SecLogNvM_SecLog_LogFailedMacVerifCount_ExceededTh2}
        {enable-take-address=true, indirect-api=false, port-defined-argument-value{value=22, value-type=NvM_BlockIdType}, port=PAdmin_Ssa_SecLogNvM_SecLog_LogFailedMacVerifCount_ExceededTh2}
        {enable-take-address=true, indirect-api=false, port-defined-argument-value{value=23, value-type=NvM_BlockIdType}, port=PS_Ssa_SecLogNvM_SecLog_LogFailedMacVerifCount_ExceededTh3}
        {enable-take-address=true, indirect-api=false, port-defined-argument-value{value=23, value-type=NvM_BlockIdType}, port=PAdmin_Ssa_SecLogNvM_SecLog_LogFailedMacVerifCount_ExceededTh3}
        {enable-take-address=true, indirect-api=false, port-defined-argument-value{value=24, value-type=NvM_BlockIdType}, port=PS_Ssa_TimeM_NvM_TimeM_RealTimeOffset}
        {enable-take-address=true, indirect-api=false, port-defined-argument-value{value=24, value-type=NvM_BlockIdType}, port=PAdmin_Ssa_TimeM_NvM_TimeM_RealTimeOffset}
        {enable-take-address=true, indirect-api=false, port-defined-argument-value{value=25, value-type=NvM_BlockIdType}, port=PS_Ssa_TimeM_NvM_TimeM_TickCount}
        {enable-take-address=true, indirect-api=false, port-defined-argument-value{value=25, value-type=NvM_BlockIdType}, port=PAdmin_Ssa_TimeM_NvM_TimeM_TickCount}
        {enable-take-address=true, indirect-api=false, port-defined-argument-value{value=27, value-type=NvM_BlockIdType}, port=PS_Ct_MBBL_SsaAppl_CodingNvmCoding_CurrentVehicleEquipment}
        {enable-take-address=true, indirect-api=false, port-defined-argument-value{value=27, value-type=NvM_BlockIdType}, port=PAdmin_Ct_MBBL_SsaAppl_CodingNvmCoding_CurrentVehicleEquipment}
        {enable-take-address=true, indirect-api=false, port-defined-argument-value{value=28, value-type=NvM_BlockIdType}, port=PS_Ct_MBBL_SsaAppl_CodingNvmCoding_TensioningCycleBSR}
        {enable-take-address=true, indirect-api=false, port-defined-argument-value{value=28, value-type=NvM_BlockIdType}, port=PAdmin_Ct_MBBL_SsaAppl_CodingNvmCoding_TensioningCycleBSR}
        {enable-take-address=true, indirect-api=false, port-defined-argument-value{value=29, value-type=NvM_BlockIdType}, port=PS_Ct_MBBL_SsaAppl_CodingNvmCoding_PreSafeCyclesLevel}
        {enable-take-address=true, indirect-api=false, port-defined-argument-value{value=29, value-type=NvM_BlockIdType}, port=PAdmin_Ct_MBBL_SsaAppl_CodingNvmCoding_PreSafeCyclesLevel}
        {enable-take-address=true, indirect-api=false, port-defined-argument-value{value=30, value-type=NvM_BlockIdType}, port=PS_Ct_MBBL_SsaAppl_CodingNvmCoding_ReleaseCyclesBsrAndPreSafe}
        {enable-take-address=true, indirect-api=false, port-defined-argument-value{value=30, value-type=NvM_BlockIdType}, port=PAdmin_Ct_MBBL_SsaAppl_CodingNvmCoding_ReleaseCyclesBsrAndPreSafe}
        {enable-take-address=true, indirect-api=false, port-defined-argument-value{value=31, value-type=NvM_BlockIdType}, port=PS_Ct_MBBL_SsaAppl_CodingNvmCoding_ZZZVehicleEquipmentDevelopment}
        {enable-take-address=true, indirect-api=false, port-defined-argument-value{value=31, value-type=NvM_BlockIdType}, port=PAdmin_Ct_MBBL_SsaAppl_CodingNvmCoding_ZZZVehicleEquipmentDevelopment}
        {enable-take-address=true, indirect-api=false, port-defined-argument-value{value=32, value-type=NvM_BlockIdType}, port=PS_Ct_MBBL_SsaAppl_CodingNvmCoding_CalibrationID}
        {enable-take-address=true, indirect-api=false, port-defined-argument-value{value=32, value-type=NvM_BlockIdType}, port=PAdmin_Ct_MBBL_SsaAppl_CodingNvmCoding_CalibrationID}
        {enable-take-address=true, indirect-api=false, port-defined-argument-value{value=33, value-type=NvM_BlockIdType}, port=PS_NvMBlockDescriptor_FblMetaData}
        {enable-take-address=true, indirect-api=false, port-defined-argument-value{value=33, value-type=NvM_BlockIdType}, port=PAdmin_NvMBlockDescriptor_FblMetaData}
        {enable-take-address=true, indirect-api=false, port-defined-argument-value{value=34, value-type=NvM_BlockIdType}, port=PS_NVP_BLOCK_ID_ECU_LOCATION}
        {enable-take-address=true, indirect-api=false, port-defined-argument-value{value=34, value-type=NvM_BlockIdType}, port=PAdmin_NVP_BLOCK_ID_ECU_LOCATION}
        {enable-take-address=true, indirect-api=false, port-defined-argument-value{value=35, value-type=NvM_BlockIdType}, port=PS_NVP_BLOCK_ID_BELT_ASSEMBLY_MANUF_DATE_AND_SN}
        {enable-take-address=true, indirect-api=false, port-defined-argument-value{value=35, value-type=NvM_BlockIdType}, port=PAdmin_NVP_BLOCK_ID_BELT_ASSEMBLY_MANUF_DATE_AND_SN}
        {enable-take-address=true, indirect-api=false, port-defined-argument-value{value=36, value-type=NvM_BlockIdType}, port=PS_NVP_BLOCK_ID_HB_CALIBRATION}
        {enable-take-address=true, indirect-api=false, port-defined-argument-value{value=36, value-type=NvM_BlockIdType}, port=PAdmin_NVP_BLOCK_ID_HB_CALIBRATION}
        {enable-take-address=true, indirect-api=false, port-defined-argument-value{value=38, value-type=NvM_BlockIdType}, port=PS_NVP_BLOCK_ID_AEE_TRACEABILITY}
        {enable-take-address=true, indirect-api=false, port-defined-argument-value{value=38, value-type=NvM_BlockIdType}, port=PAdmin_NVP_BLOCK_ID_AEE_TRACEABILITY}
        {enable-take-address=true, indirect-api=false, port-defined-argument-value{value=39, value-type=NvM_BlockIdType}, port=PS_NVP_BLOCK_ID_EXECUTION_COUNTERS}
        {enable-take-address=true, indirect-api=false, port-defined-argument-value{value=39, value-type=NvM_BlockIdType}, port=PAdmin_NVP_BLOCK_ID_EXECUTION_COUNTERS}
        {enable-take-address=true, indirect-api=false, port-defined-argument-value{value=40, value-type=NvM_BlockIdType}, port=PS_NVP_BLOCK_ID_TESTS_PARAM}
        {enable-take-address=true, indirect-api=false, port-defined-argument-value{value=40, value-type=NvM_BlockIdType}, port=PAdmin_NVP_BLOCK_ID_TESTS_PARAM}
        {enable-take-address=true, indirect-api=false, port-defined-argument-value{value=43, value-type=NvM_BlockIdType}, port=PS_NVP_BLOCK_ID_CYCLE}
        {enable-take-address=true, indirect-api=false, port-defined-argument-value{value=43, value-type=NvM_BlockIdType}, port=PAdmin_NVP_BLOCK_ID_CYCLE}
        {enable-take-address=true, indirect-api=false, port-defined-argument-value{value=47, value-type=NvM_BlockIdType}, port=PS_NVP_BLOCK_ID_STEP}
        {enable-take-address=true, indirect-api=false, port-defined-argument-value{value=47, value-type=NvM_BlockIdType}, port=PAdmin_NVP_BLOCK_ID_STEP}
        {enable-take-address=true, indirect-api=false, port-defined-argument-value{value=48, value-type=NvM_BlockIdType}, port=PS_CALIB_BLOCK_ID_EOL_PARAM}
        {enable-take-address=true, indirect-api=false, port-defined-argument-value{value=48, value-type=NvM_BlockIdType}, port=PAdmin_CALIB_BLOCK_ID_EOL_PARAM}
        {enable-take-address=true, indirect-api=false, port-defined-argument-value{value=49, value-type=NvM_BlockIdType}, port=PS_CALIB_BLOCK_ID_BFS_PRIO_PARAM}
        {enable-take-address=true, indirect-api=false, port-defined-argument-value{value=49, value-type=NvM_BlockIdType}, port=PAdmin_CALIB_BLOCK_ID_BFS_PRIO_PARAM}
        {enable-take-address=true, indirect-api=false, port-defined-argument-value{value=50, value-type=NvM_BlockIdType}, port=PS_CALIB_BLOCK_ID_PID_PARAM}
        {enable-take-address=true, indirect-api=false, port-defined-argument-value{value=50, value-type=NvM_BlockIdType}, port=PAdmin_CALIB_BLOCK_ID_PID_PARAM}
        {enable-take-address=true, indirect-api=false, port-defined-argument-value{value=51, value-type=NvM_BlockIdType}, port=PS_CALIB_BLOCK_ID_WEIGHT_REL_TABLE}
        {enable-take-address=true, indirect-api=false, port-defined-argument-value{value=51, value-type=NvM_BlockIdType}, port=PAdmin_CALIB_BLOCK_ID_WEIGHT_REL_TABLE}
        {enable-take-address=true, indirect-api=false, port-defined-argument-value{value=52, value-type=NvM_BlockIdType}, port=PS_CALIB_BLOCK_ID_WEIGHT_TENS0_TABLE}
        {enable-take-address=true, indirect-api=false, port-defined-argument-value{value=52, value-type=NvM_BlockIdType}, port=PAdmin_CALIB_BLOCK_ID_WEIGHT_TENS0_TABLE}
        {enable-take-address=true, indirect-api=false, port-defined-argument-value{value=53, value-type=NvM_BlockIdType}, port=PS_CALIB_BLOCK_ID_WEIGHT_TENS1_TABLE}
        {enable-take-address=true, indirect-api=false, port-defined-argument-value{value=53, value-type=NvM_BlockIdType}, port=PAdmin_CALIB_BLOCK_ID_WEIGHT_TENS1_TABLE}
        {enable-take-address=true, indirect-api=false, port-defined-argument-value{value=54, value-type=NvM_BlockIdType}, port=PS_CALIB_BLOCK_ID_WEIGHT_TENS2_TABLE}
        {enable-take-address=true, indirect-api=false, port-defined-argument-value{value=54, value-type=NvM_BlockIdType}, port=PAdmin_CALIB_BLOCK_ID_WEIGHT_TENS2_TABLE}
        {enable-take-address=true, indirect-api=false, port-defined-argument-value{value=55, value-type=NvM_BlockIdType}, port=PS_CALIB_BLOCK_ID_WEIGHT_TENS3_TABLE}
        {enable-take-address=true, indirect-api=false, port-defined-argument-value{value=55, value-type=NvM_BlockIdType}, port=PAdmin_CALIB_BLOCK_ID_WEIGHT_TENS3_TABLE}
        {enable-take-address=true, indirect-api=false, port-defined-argument-value{value=56, value-type=NvM_BlockIdType}, port=PS_CALIB_BLOCK_ID_INT_CURRENT_CORR}
        {enable-take-address=true, indirect-api=false, port-defined-argument-value{value=56, value-type=NvM_BlockIdType}, port=PAdmin_CALIB_BLOCK_ID_INT_CURRENT_CORR}
        {enable-take-address=true, indirect-api=false, port-defined-argument-value{value=57, value-type=NvM_BlockIdType}, port=PS_CALIB_BLOCK_ID_INT_CURRENT_TABLE}
        {enable-take-address=true, indirect-api=false, port-defined-argument-value{value=57, value-type=NvM_BlockIdType}, port=PAdmin_CALIB_BLOCK_ID_INT_CURRENT_TABLE}
        {enable-take-address=true, indirect-api=false, port-defined-argument-value{value=58, value-type=NvM_BlockIdType}, port=PS_CALIB_BLOCK_ID_ECPL_ALPHA_TABLE}
        {enable-take-address=true, indirect-api=false, port-defined-argument-value{value=58, value-type=NvM_BlockIdType}, port=PAdmin_CALIB_BLOCK_ID_ECPL_ALPHA_TABLE}
        {enable-take-address=true, indirect-api=false, port-defined-argument-value{value=59, value-type=NvM_BlockIdType}, port=PS_CALIB_BLOCK_ID_POWER_DEGRADATION}
        {enable-take-address=true, indirect-api=false, port-defined-argument-value{value=59, value-type=NvM_BlockIdType}, port=PAdmin_CALIB_BLOCK_ID_POWER_DEGRADATION}
        {enable-take-address=true, indirect-api=false, port-defined-argument-value{value=60, value-type=NvM_BlockIdType}, port=PS_CALIB_BLOCK_ID_ECPL_BETA_TABLE}
        {enable-take-address=true, indirect-api=false, port-defined-argument-value{value=60, value-type=NvM_BlockIdType}, port=PAdmin_CALIB_BLOCK_ID_ECPL_BETA_TABLE}
        {enable-take-address=true, indirect-api=false, port-defined-argument-value{value=61, value-type=NvM_BlockIdType}, port=PS_CALIB_BLOCK_ID_ECPL_OTHER_PARAM}
        {enable-take-address=true, indirect-api=false, port-defined-argument-value{value=61, value-type=NvM_BlockIdType}, port=PAdmin_CALIB_BLOCK_ID_ECPL_OTHER_PARAM}
        {enable-take-address=true, indirect-api=false, port-defined-argument-value{value=62, value-type=NvM_BlockIdType}, port=PS_CALIB_BLOCK_ID_BPA_MOTOR_CURRENT}
        {enable-take-address=true, indirect-api=false, port-defined-argument-value{value=62, value-type=NvM_BlockIdType}, port=PAdmin_CALIB_BLOCK_ID_BPA_MOTOR_CURRENT}
        {enable-take-address=true, indirect-api=false, port-defined-argument-value{value=63, value-type=NvM_BlockIdType}, port=PS_CALIB_BLOCK_ID_VOLT_THRS}
        {enable-take-address=true, indirect-api=false, port-defined-argument-value{value=63, value-type=NvM_BlockIdType}, port=PAdmin_CALIB_BLOCK_ID_VOLT_THRS}
        {enable-take-address=true, indirect-api=false, port-defined-argument-value{value=64, value-type=NvM_BlockIdType}, port=PS_CALIB_BLOCK_ID_BATTERY_LOSS_DETECTION_THRS}
        {enable-take-address=true, indirect-api=false, port-defined-argument-value{value=64, value-type=NvM_BlockIdType}, port=PAdmin_CALIB_BLOCK_ID_BATTERY_LOSS_DETECTION_THRS}
        {enable-take-address=true, indirect-api=false, port-defined-argument-value{value=65, value-type=NvM_BlockIdType}, port=PS_CALIB_BLOCK_ID_BOOST}
        {enable-take-address=true, indirect-api=false, port-defined-argument-value{value=65, value-type=NvM_BlockIdType}, port=PAdmin_CALIB_BLOCK_ID_BOOST}
        {enable-take-address=true, indirect-api=false, port-defined-argument-value{value=66, value-type=NvM_BlockIdType}, port=PS_CALIB_BLOCK_ID_ECU_PROPERTIES}
        {enable-take-address=true, indirect-api=false, port-defined-argument-value{value=66, value-type=NvM_BlockIdType}, port=PAdmin_CALIB_BLOCK_ID_ECU_PROPERTIES}
        {enable-take-address=true, indirect-api=false, port-defined-argument-value{value=67, value-type=NvM_BlockIdType}, port=PS_CALIB_BLOCK_ID_SW_SELF_PROTECTION_THRS}
        {enable-take-address=true, indirect-api=false, port-defined-argument-value{value=67, value-type=NvM_BlockIdType}, port=PAdmin_CALIB_BLOCK_ID_SW_SELF_PROTECTION_THRS}
        {enable-take-address=true, indirect-api=false, port-defined-argument-value{value=68, value-type=NvM_BlockIdType}, port=PS_CALIB_BLOCK_ID_MOTOR_RESIST_PARAM}
        {enable-take-address=true, indirect-api=false, port-defined-argument-value{value=68, value-type=NvM_BlockIdType}, port=PAdmin_CALIB_BLOCK_ID_MOTOR_RESIST_PARAM}
        {enable-take-address=true, indirect-api=false, port-defined-argument-value{value=69, value-type=NvM_BlockIdType}, port=PS_CALIB_BLOCK_ID_BOOST_ACTIVATION}
        {enable-take-address=true, indirect-api=false, port-defined-argument-value{value=69, value-type=NvM_BlockIdType}, port=PAdmin_CALIB_BLOCK_ID_BOOST_ACTIVATION}
        {enable-take-address=true, indirect-api=false, port-defined-argument-value{value=41, value-type=NvM_BlockIdType}, port=PS_NVP_BLOCK_ID_MEASUREMENT_FRAME_12_CONFIG}
        {enable-take-address=true, indirect-api=false, port-defined-argument-value{value=41, value-type=NvM_BlockIdType}, port=PAdmin_NVP_BLOCK_ID_MEASUREMENT_FRAME_12_CONFIG}
        {enable-take-address=true, indirect-api=false, port-defined-argument-value{value=42, value-type=NvM_BlockIdType}, port=PS_NVP_BLOCK_ID_MEASUREMENT_FRAME_CONFIG}
        {enable-take-address=true, indirect-api=false, port-defined-argument-value{value=42, value-type=NvM_BlockIdType}, port=PAdmin_NVP_BLOCK_ID_MEASUREMENT_FRAME_CONFIG}
        {enable-take-address=true, indirect-api=false, port-defined-argument-value{value=70, value-type=NvM_BlockIdType}, port=PS_NVP_BLOCK_ID_WARM_RESET}
        {enable-take-address=true, indirect-api=false, port-defined-argument-value{value=70, value-type=NvM_BlockIdType}, port=PAdmin_NVP_BLOCK_ID_WARM_RESET}
        {enable-take-address=true, indirect-api=false, port-defined-argument-value{value=71, value-type=NvM_BlockIdType}, port=PS_NVP_BLOCK_ID_PRE_SAFE_RECORDER_1}
        {enable-take-address=true, indirect-api=false, port-defined-argument-value{value=71, value-type=NvM_BlockIdType}, port=PAdmin_NVP_BLOCK_ID_PRE_SAFE_RECORDER_1}
        {enable-take-address=true, indirect-api=false, port-defined-argument-value{value=72, value-type=NvM_BlockIdType}, port=PS_NVP_BLOCK_ID_PRE_SAFE_RECORDER_ID}
        {enable-take-address=true, indirect-api=false, port-defined-argument-value{value=72, value-type=NvM_BlockIdType}, port=PAdmin_NVP_BLOCK_ID_PRE_SAFE_RECORDER_ID}
        {enable-take-address=true, indirect-api=false, port-defined-argument-value{value=44, value-type=NvM_BlockIdType}, port=PS_NVP_BLOCK_ID_CYCLE_DELAYS_MB}
        {enable-take-address=true, indirect-api=false, port-defined-argument-value{value=44, value-type=NvM_BlockIdType}, port=PAdmin_NVP_BLOCK_ID_CYCLE_DELAYS_MB}
        {enable-take-address=true, indirect-api=false, port-defined-argument-value{value=45, value-type=NvM_BlockIdType}, port=PS_NVP_BLOCK_ID_HAPTIC_CONFIG_MB}
        {enable-take-address=true, indirect-api=false, port-defined-argument-value{value=45, value-type=NvM_BlockIdType}, port=PAdmin_NVP_BLOCK_ID_HAPTIC_CONFIG_MB}
        {enable-take-address=true, indirect-api=false, port-defined-argument-value{value=46, value-type=NvM_BlockIdType}, port=PS_NVP_BLOCK_ID_EOL_MAPPING_MB}
        {enable-take-address=true, indirect-api=false, port-defined-argument-value{value=46, value-type=NvM_BlockIdType}, port=PAdmin_NVP_BLOCK_ID_EOL_MAPPING_MB}
        {enable-take-address=true, indirect-api=false, port-defined-argument-value{value=37, value-type=NvM_BlockIdType}, port=PS_NVP_BLOCK_ID_HW_VERSION}
        {enable-take-address=true, indirect-api=false, port-defined-argument-value{value=37, value-type=NvM_BlockIdType}, port=PAdmin_NVP_BLOCK_ID_HW_VERSION}
        {enable-take-address=true, indirect-api=false, port-defined-argument-value{value=75, value-type=NvM_BlockIdType}, port=PS_NVP_BLOCK_ID_HWA_REPETITION}
        {enable-take-address=true, indirect-api=false, port-defined-argument-value{value=75, value-type=NvM_BlockIdType}, port=PAdmin_NVP_BLOCK_ID_HWA_REPETITION}
        {enable-take-address=true, indirect-api=false, port-defined-argument-value{value=76, value-type=NvM_BlockIdType}, port=PS_NVP_BLOCK_TEMP_SENSOR_TABLE}
        {enable-take-address=true, indirect-api=false, port-defined-argument-value{value=76, value-type=NvM_BlockIdType}, port=PAdmin_NVP_BLOCK_TEMP_SENSOR_TABLE}
        {enable-take-address=true, indirect-api=false, port-defined-argument-value{value=80, value-type=NvM_BlockIdType}, port=PS_NVP_BLOCK_ID_VELOCITY_PID_PARAM}
        {enable-take-address=true, indirect-api=false, port-defined-argument-value{value=80, value-type=NvM_BlockIdType}, port=PAdmin_NVP_BLOCK_ID_VELOCITY_PID_PARAM}
        {enable-take-address=true, indirect-api=false, port-defined-argument-value{value=81, value-type=NvM_BlockIdType}, port=PS_NVP_BLOCK_ID_AEC_STATUS}
        {enable-take-address=true, indirect-api=false, port-defined-argument-value{value=81, value-type=NvM_BlockIdType}, port=PAdmin_NVP_BLOCK_ID_AEC_STATUS}
        {enable-take-address=true, indirect-api=false, port-defined-argument-value{value=82, value-type=NvM_BlockIdType}, port=PS_NVP_BLOCK_ID_ATM_ENABLE_PARAM}
        {enable-take-address=true, indirect-api=false, port-defined-argument-value{value=82, value-type=NvM_BlockIdType}, port=PAdmin_NVP_BLOCK_ID_ATM_ENABLE_PARAM}
        {enable-take-address=true, indirect-api=false, port-defined-argument-value{value=97, value-type=NvM_BlockIdType}, port=PS_Ssa_KeyM_NvM_KeyM_TrustModelChainOfTrustState}
        {enable-take-address=true, indirect-api=false, port-defined-argument-value{value=97, value-type=NvM_BlockIdType}, port=PAdmin_Ssa_KeyM_NvM_KeyM_TrustModelChainOfTrustState}
        {enable-take-address=true, indirect-api=false, port-defined-argument-value{value=74, value-type=NvM_BlockIdType}, port=PS_NVP_BLOCK_ID_PRE_SAFE_RECORDER_2}
        {enable-take-address=true, indirect-api=false, port-defined-argument-value{value=74, value-type=NvM_BlockIdType}, port=PAdmin_NVP_BLOCK_ID_PRE_SAFE_RECORDER_2}
        {enable-take-address=true, indirect-api=false, port-defined-argument-value{value=77, value-type=NvM_BlockIdType}, port=PS_NVP_BLOCK_ID_SYSTEM_CONTEXT_0}
        {enable-take-address=true, indirect-api=false, port-defined-argument-value{value=77, value-type=NvM_BlockIdType}, port=PAdmin_NVP_BLOCK_ID_SYSTEM_CONTEXT_0}
        {enable-take-address=true, indirect-api=false, port-defined-argument-value{value=78, value-type=NvM_BlockIdType}, port=PS_NVP_BLOCK_ID_SYSTEM_CONTEXT_1}
        {enable-take-address=true, indirect-api=false, port-defined-argument-value{value=78, value-type=NvM_BlockIdType}, port=PAdmin_NVP_BLOCK_ID_SYSTEM_CONTEXT_1}
        {enable-take-address=true, indirect-api=false, port-defined-argument-value{value=79, value-type=NvM_BlockIdType}, port=PS_NVP_BLOCK_ID_SYSTEM_CONTEXT_2}
        {enable-take-address=true, indirect-api=false, port-defined-argument-value{value=79, value-type=NvM_BlockIdType}, port=PAdmin_NVP_BLOCK_ID_SYSTEM_CONTEXT_2}
        {enable-take-address=true, indirect-api=false, port-defined-argument-value{value=73, value-type=NvM_BlockIdType}, port=PS_NVP_BLOCK_ID_CAN_INPUT_SIGNALS}
        {enable-take-address=true, indirect-api=false, port-defined-argument-value{value=73, value-type=NvM_BlockIdType}, port=PAdmin_NVP_BLOCK_ID_CAN_INPUT_SIGNALS}
        {enable-take-address=true, indirect-api=false, port-defined-argument-value{value=100, value-type=NvM_BlockIdType}, port=PS_NVP_BLOCK_ID_PCBA_PPN}
        {enable-take-address=true, indirect-api=false, port-defined-argument-value{value=100, value-type=NvM_BlockIdType}, port=PAdmin_NVP_BLOCK_ID_PCBA_PPN}
        {enable-take-address=true, indirect-api=false, port-defined-argument-value{value=101, value-type=NvM_BlockIdType}, port=PAdmin_NVP_BLOCK_ID_CSR_SUPPLIER_SIGNATURE}
        {enable-take-address=true, indirect-api=false, port-defined-argument-value{value=102, value-type=NvM_BlockIdType}, port=PAdmin_NVP_BLOCK_ID_HW_PARTNUMBER}
        {enable-take-address=true, indirect-api=false, port-defined-argument-value{value=102, value-type=NvM_BlockIdType}, port=PS_NVP_BLOCK_ID_HW_PARTNUMBER}
        {enable-take-address=true, indirect-api=false, port-defined-argument-value{value=101, value-type=NvM_BlockIdType}, port=PS_NVP_BLOCK_ID_CSR_SUPPLIER_SIGNATURE}
      11 x runnable:
        NvM_MainFunction
        GetErrorStatus: can-be-invoked-concurrently=true, symbol=NvM_GetErrorStatus
        SetRamBlockStatus: can-be-invoked-concurrently=true, symbol=NvM_SetRamBlockStatus
        ReadBlock: can-be-invoked-concurrently=true, symbol=NvM_ReadBlock
        WriteBlock: can-be-invoked-concurrently=true, symbol=NvM_WriteBlock
        RestoreBlockDefaults: can-be-invoked-concurrently=true, symbol=NvM_RestoreBlockDefaults
        InvalidateNvBlock: can-be-invoked-concurrently=true, symbol=NvM_InvalidateNvBlock
        EraseBlock: can-be-invoked-concurrently=true, symbol=NvM_EraseNvBlock
        SetBlockProtection: can-be-invoked-concurrently=true, symbol=NvM_SetBlockProtection
        SetDataIndex: can-be-invoked-concurrently=true, symbol=NvM_SetDataIndex
        GetDataIndex: can-be-invoked-concurrently=true, symbol=NvM_GetDataIndex
  swc implementation NvMImplementation: programming-language=C, behavior=NvMInternalBehavior
